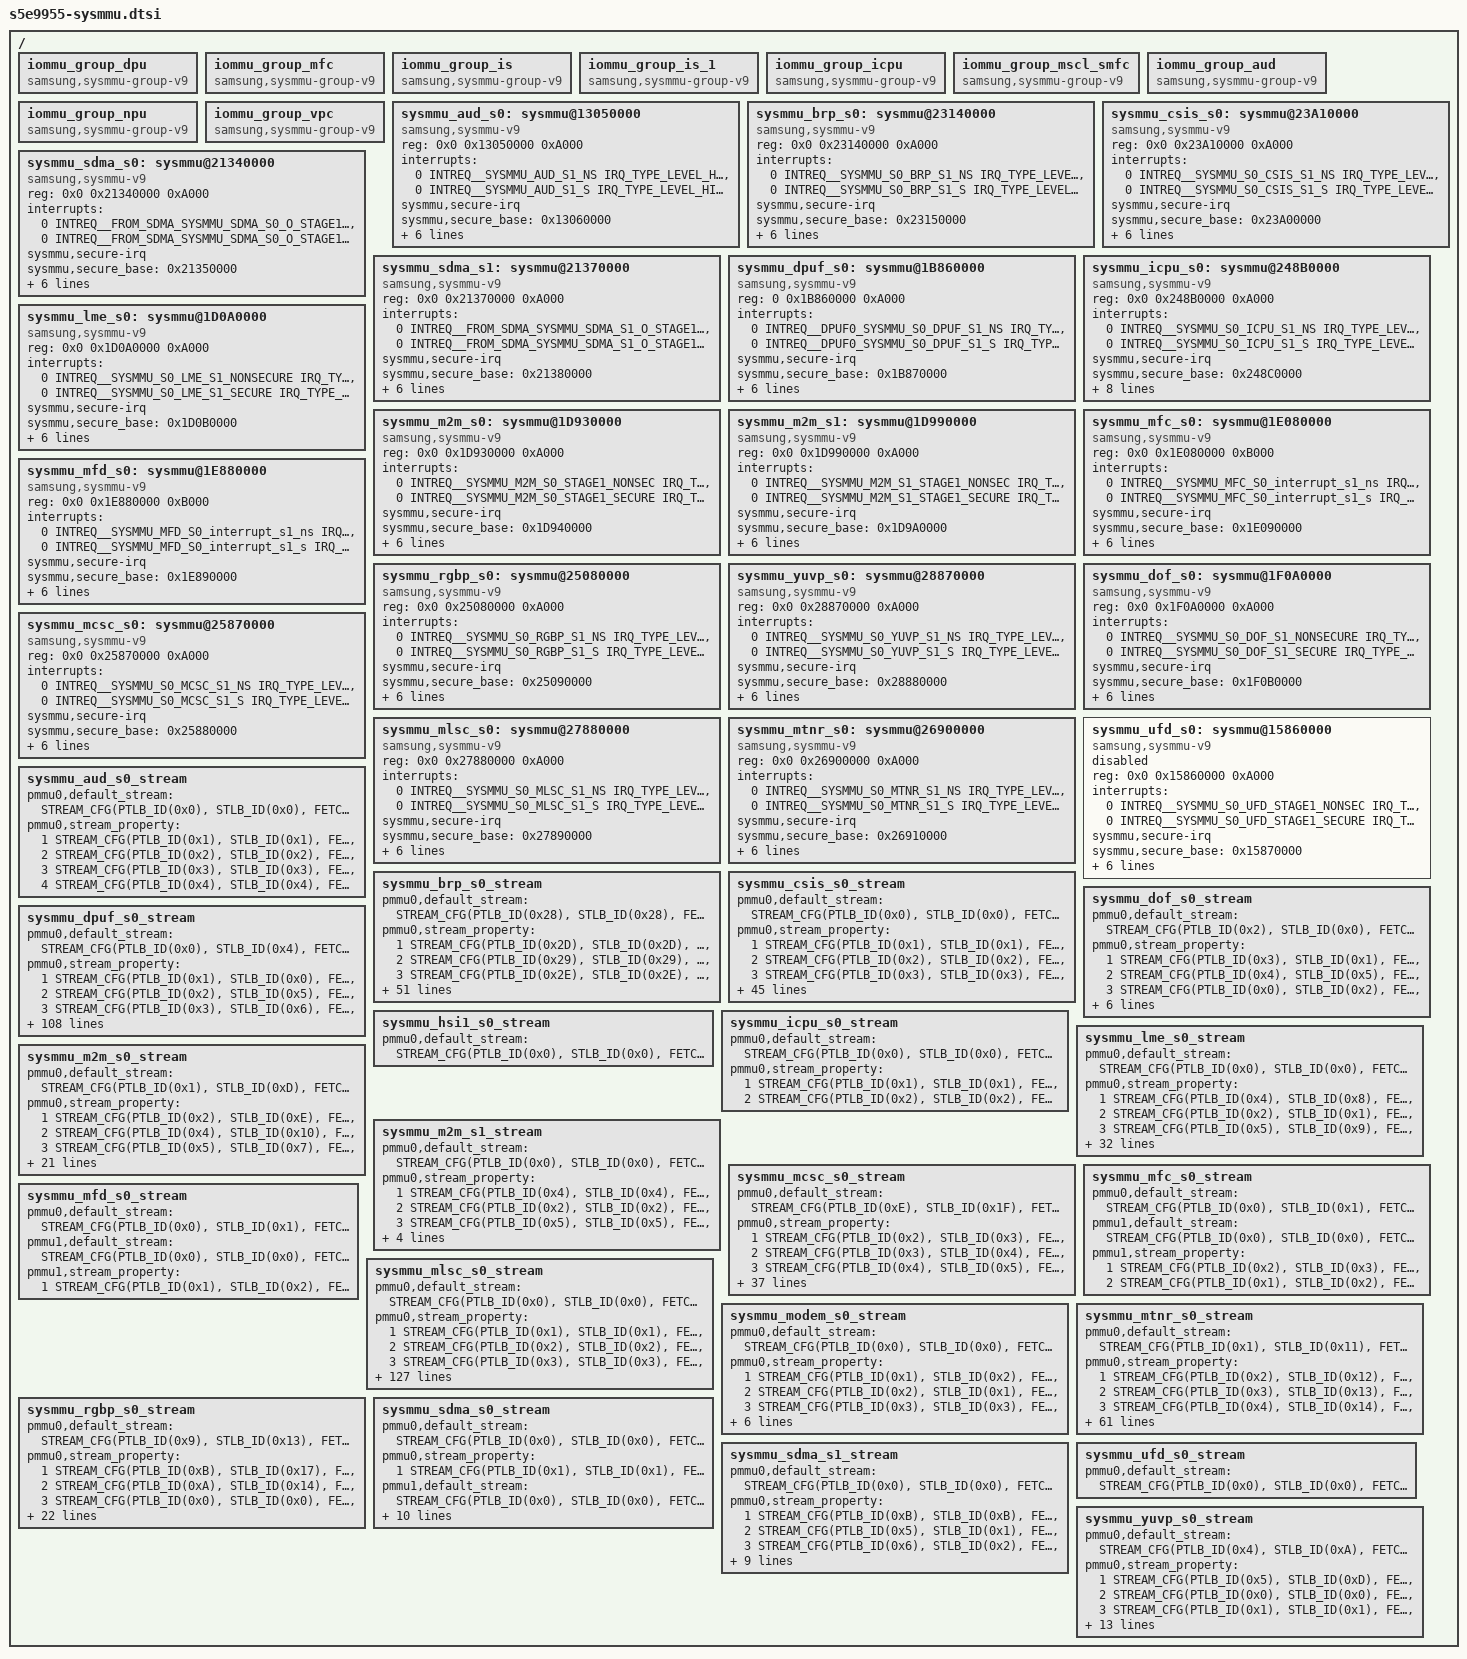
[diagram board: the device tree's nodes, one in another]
// SPDX-License-Identifier: GPL-2.0
/*
 * SAMSUNG S5E9955 SoC device tree source
 *
 * Copyright (c) 2023 Samsung Electronics Co., Ltd.
 *      http://www.samsung.com
 *
 * SAMSUNG S5E9955 SoC device nodes are listed in this file.
 * S5E9955 based board files can include this file and provide
 * values for board specific bindings.
 *
 * This program is free software; you can redistribute it and/or modify
 * it under the terms of the GNU General Public License version 2 as
 * published by the Free Software Foundation.
 */

#include <dt-bindings/interrupt-controller/arm-gic.h>
#include <dt-bindings/soc/samsung,sysmmu-v9.h>

/ {
	iommu_group_dpu: iommu_group_dpu {
		compatible = "samsung,sysmmu-group-v9";
	};

	iommu_group_mfc: iommu_group_mfc {
		compatible = "samsung,sysmmu-group-v9";
	};

	iommu_group_is: iommu_group_is {
		compatible = "samsung,sysmmu-group-v9";
	};

	iommu_group_is_1: iommu_group_is_1 {
		compatible = "samsung,sysmmu-group-v9";
	};

	iommu_group_icpu: iommu_group_icpu {
		compatible = "samsung,sysmmu-group-v9";
	};

	iommu_group_mscl_smfc: iommu_group_mscl_smfc {
		compatible = "samsung,sysmmu-group-v9";
	};

	iommu_group_aud: iommu_group_aud {
		compatible = "samsung,sysmmu-group-v9";
	};

	iommu_group_npu: iommu_group_npu {
		compatible = "samsung,sysmmu-group-v9";
	};

	iommu_group_vpc: iommu_group_vpc {
		compatible = "samsung,sysmmu-group-v9";
	};

	sysmmu_aud_s0: sysmmu@13050000 {
		compatible = "samsung,sysmmu-v9";
		reg = <0x0 0x13050000 0xA000>;
		interrupts = <0 INTREQ__SYSMMU_AUD_S1_NS IRQ_TYPE_LEVEL_HIGH>,
				<0 INTREQ__SYSMMU_AUD_S1_S IRQ_TYPE_LEVEL_HIGH>;
		sysmmu,secure-irq;
		sysmmu,secure_base = <0x13060000>;
		qos = <15>;
		#iommu-cells = <0>;
		stream-property = <&sysmmu_aud_s0_stream>;
		vmid_mask = <0x3>;
		sysmmu,feature-info = <0x1>;
		port-name = "ABOX (CA32_0) ABOX (CA32_1) ...";
		power-domains = <&pd_aud>;
	};

	sysmmu_brp_s0: sysmmu@23140000 {
		compatible = "samsung,sysmmu-v9";
		reg = <0x0 0x23140000 0xA000>;
		interrupts = <0 INTREQ__SYSMMU_S0_BRP_S1_NS IRQ_TYPE_LEVEL_HIGH>,
				<0 INTREQ__SYSMMU_S0_BRP_S1_S IRQ_TYPE_LEVEL_HIGH>;
		sysmmu,secure-irq;
		sysmmu,secure_base = <0x23150000>;
		qos = <15>;
		#iommu-cells = <0>;
		stream-property = <&sysmmu_brp_s0_stream>;
		vmid_mask = <0x3>;
		sysmmu,feature-info = <0x1>;
		port-name = "BYRP (M0) BYRP (M0) BYRP (M ...";
		power-domains = <&pd_byrp>;
		status = "okay";
	};

	sysmmu_csis_s0: sysmmu@23A10000 {
		compatible = "samsung,sysmmu-v9";
		reg = <0x0 0x23A10000 0xA000>;
		interrupts = <0 INTREQ__SYSMMU_S0_CSIS_S1_NS IRQ_TYPE_LEVEL_HIGH>,
				<0 INTREQ__SYSMMU_S0_CSIS_S1_S IRQ_TYPE_LEVEL_HIGH>;
		sysmmu,secure-irq;
		sysmmu,secure_base = <0x23A00000>;
		qos = <15>;
		#iommu-cells = <0>;
		stream-property = <&sysmmu_csis_s0_stream>;
		vmid_mask = <0x3>;
		sysmmu,feature-info = <0x1>;
		port-name = "CSISX7_V1.0 (CSIS DMA0) CSI ...";
		power-domains = <&pd_csis>;
		status = "okay";
	};

	sysmmu_sdma_s0: sysmmu@21340000 {
		compatible = "samsung,sysmmu-v9";
		reg = <0x0 0x21340000 0xA000>;
		interrupts = <0 INTREQ__FROM_SDMA_SYSMMU_SDMA_S0_O_STAGE1_NONSEC IRQ_TYPE_LEVEL_HIGH>,
				<0 INTREQ__FROM_SDMA_SYSMMU_SDMA_S0_O_STAGE1_SECURE IRQ_TYPE_LEVEL_HIGH>;
		sysmmu,secure-irq;
		sysmmu,secure_base = <0x21350000>;
		qos = <15>;
		#iommu-cells = <0>;
		stream-property = <&sysmmu_sdma_s0_stream>;
		vmid_mask = <0x3>;
		sysmmu,feature-info = <0x1>;
		port-name = "IP_SDMA (BUSD0) IP_SDMA (BU ...";
		power-domains = <&pd_sdma>;
	};

	sysmmu_sdma_s1: sysmmu@21370000 {
		compatible = "samsung,sysmmu-v9";
		reg = <0x0 0x21370000 0xA000>;
		interrupts = <0 INTREQ__FROM_SDMA_SYSMMU_SDMA_S1_O_STAGE1_NONSEC IRQ_TYPE_LEVEL_HIGH>,
				<0 INTREQ__FROM_SDMA_SYSMMU_SDMA_S1_O_STAGE1_SECURE IRQ_TYPE_LEVEL_HIGH>;
		sysmmu,secure-irq;
		sysmmu,secure_base = <0x21380000>;
		qos = <15>;
		#iommu-cells = <0>;
		stream-property = <&sysmmu_sdma_s1_stream>;
		vmid_mask = <0x3>;
		sysmmu,feature-info = <0x1>;
		port-name = "IP_DNC (DRAM)";
		power-domains = <&pd_sdma>;
	};

	sysmmu_dpuf_s0: sysmmu@1B860000 {
		compatible = "samsung,sysmmu-v9";
		reg = <0 0x1B860000 0xA000>;
		interrupts = <0 INTREQ__DPUF0_SYSMMU_S0_DPUF_S1_NS IRQ_TYPE_LEVEL_HIGH>,
				<0 INTREQ__DPUF0_SYSMMU_S0_DPUF_S1_S IRQ_TYPE_LEVEL_HIGH>;
		sysmmu,secure-irq;
		sysmmu,secure_base = <0x1B870000>;
		qos = <15>;
		#iommu-cells = <0>;
		stream-property = <&sysmmu_dpuf_s0_stream>;
		vmid_mask = <0x3>;
		sysmmu,feature-info = <0x1>;
		port-name = "DPU_DMA_TOP";
		power-domains = <&pd_dpuf1>;
	};

	sysmmu_icpu_s0: sysmmu@248B0000 {
		compatible = "samsung,sysmmu-v9";
		reg = <0x0 0x248B0000 0xA000>;
		interrupts = <0 INTREQ__SYSMMU_S0_ICPU_S1_NS IRQ_TYPE_LEVEL_HIGH>,
				<0 INTREQ__SYSMMU_S0_ICPU_S1_S  IRQ_TYPE_LEVEL_HIGH>;
		sysmmu,secure-irq;
		sysmmu,secure_base = <0x248C0000>;
		sysmmu,async-fault;
		qos = <15>;
		#iommu-cells = <0>;
		stream-property = <&sysmmu_icpu_s0_stream>;
		vmid_mask = <0x3>;
		sysmmu,feature-info = <0x1>;
		sysmmu,cacheable-override;
		port-name = "ICPU";
		power-domains = <&pd_icpu>;
		status = "okay";
	};

	sysmmu_lme_s0: sysmmu@1D0A0000 {
		compatible = "samsung,sysmmu-v9";
		reg = <0x0 0x1D0A0000 0xA000>;
		interrupts = <0 INTREQ__SYSMMU_S0_LME_S1_NONSECURE IRQ_TYPE_LEVEL_HIGH>,
				<0 INTREQ__SYSMMU_S0_LME_S1_SECURE IRQ_TYPE_LEVEL_HIGH>;
		sysmmu,secure-irq;
		sysmmu,secure_base = <0x1D0B0000>;
		qos = <15>;
		#iommu-cells = <0>;
		stream-property = <&sysmmu_lme_s0_stream>;
		vmid_mask = <0x3>;
		sysmmu,feature-info = <0x1>;
		port-name = "LME";
		power-domains = <&pd_lme>;
		status = "okay";
	};

	sysmmu_m2m_s0: sysmmu@1D930000 {
		compatible = "samsung,sysmmu-v9";
		reg = <0x0 0x1D930000 0xA000>;
		interrupts = <0 INTREQ__SYSMMU_M2M_S0_STAGE1_NONSEC IRQ_TYPE_LEVEL_HIGH>,
				<0 INTREQ__SYSMMU_M2M_S0_STAGE1_SECURE IRQ_TYPE_LEVEL_HIGH>;
		sysmmu,secure-irq;
		sysmmu,secure_base = <0x1D940000>;
		qos = <15>;
		#iommu-cells = <0>;
		stream-property = <&sysmmu_m2m_s0_stream>;
		vmid_mask = <0x3>;
		sysmmu,feature-info = <0x1>;
		port-name = "m2m_s0";
		power-domains = <&pd_m2m>;
	};

	sysmmu_m2m_s1: sysmmu@1D990000 {
		compatible = "samsung,sysmmu-v9";
		reg = <0x0 0x1D990000 0xA000>;
		interrupts = <0 INTREQ__SYSMMU_M2M_S1_STAGE1_NONSEC IRQ_TYPE_LEVEL_HIGH>,
				<0 INTREQ__SYSMMU_M2M_S1_STAGE1_SECURE IRQ_TYPE_LEVEL_HIGH>;
		sysmmu,secure-irq;
		sysmmu,secure_base = <0x1D9A0000>;
		qos = <15>;
		#iommu-cells = <0>;
		stream-property = <&sysmmu_m2m_s1_stream>;
		vmid_mask = <0x3>;
		sysmmu,feature-info = <0x1>;
		port-name = "m2m_s1";
		power-domains = <&pd_m2m>;
	};

	sysmmu_mfc_s0: sysmmu@1E080000 {
		compatible = "samsung,sysmmu-v9";
		reg = <0x0 0x1E080000 0xB000>;
		interrupts = <0 INTREQ__SYSMMU_MFC_S0_interrupt_s1_ns IRQ_TYPE_LEVEL_HIGH>,
				<0 INTREQ__SYSMMU_MFC_S0_interrupt_s1_s IRQ_TYPE_LEVEL_HIGH>;
		sysmmu,secure-irq;
		sysmmu,secure_base = <0x1E090000>;
		qos = <15>;
		#iommu-cells = <0>;
		stream-property = <&sysmmu_mfc_s0_stream>;
		vmid_mask = <0x7>;
		sysmmu,feature-info = <0x1>;
		port-name = "MFC0";
		power-domains = <&pd_mfc>;
	};

	sysmmu_mfd_s0: sysmmu@1E880000 {
		compatible = "samsung,sysmmu-v9";
		reg = <0x0 0x1E880000 0xB000>;
		interrupts = <0 INTREQ__SYSMMU_MFD_S0_interrupt_s1_ns IRQ_TYPE_LEVEL_HIGH>,
				<0 INTREQ__SYSMMU_MFD_S0_interrupt_s1_s IRQ_TYPE_LEVEL_HIGH>;
		sysmmu,secure-irq;
		sysmmu,secure_base = <0x1E890000>;
		qos = <15>;
		#iommu-cells = <0>;
		stream-property = <&sysmmu_mfd_s0_stream>;
		vmid_mask = <0x7>;
		sysmmu,feature-info = <0x1>;
		port-name = "MFC1";
		power-domains = <&pd_mfd>;
	};

	sysmmu_rgbp_s0: sysmmu@25080000 {
		compatible = "samsung,sysmmu-v9";
		reg = <0x0 0x25080000 0xA000>;
		interrupts = <0 INTREQ__SYSMMU_S0_RGBP_S1_NS IRQ_TYPE_LEVEL_HIGH>,
				<0 INTREQ__SYSMMU_S0_RGBP_S1_S IRQ_TYPE_LEVEL_HIGH>;
		sysmmu,secure-irq;
		sysmmu,secure_base = <0x25090000>;
		qos = <15>;
		#iommu-cells = <0>;
		stream-property = <&sysmmu_rgbp_s0_stream>;
		vmid_mask = <0x3>;
		sysmmu,feature-info = <0x1>;
		port-name = "RGBP (M0) RGBP (M0) RGBP (M ...";
		power-domains = <&pd_rgbp>;
		status = "okay";
	};

	sysmmu_yuvp_s0: sysmmu@28870000 {
		compatible = "samsung,sysmmu-v9";
		reg = <0x0 0x28870000 0xA000>;
		interrupts = <0 INTREQ__SYSMMU_S0_YUVP_S1_NS IRQ_TYPE_LEVEL_HIGH>,
				<0 INTREQ__SYSMMU_S0_YUVP_S1_S IRQ_TYPE_LEVEL_HIGH>;
		sysmmu,secure-irq;
		sysmmu,secure_base = <0x28880000>;
		qos = <15>;
		#iommu-cells = <0>;
		stream-property = <&sysmmu_yuvp_s0_stream>;
		vmid_mask = <0x3>;
		sysmmu,feature-info = <0x1>;
		port-name = "YUVP_M0_CL_VOTFR YUVP_M1_Y_ ...";
		power-domains = <&pd_yuvp>;
		status = "okay";
	};

	sysmmu_dof_s0: sysmmu@1F0A0000 {
		compatible = "samsung,sysmmu-v9";
		reg = <0x0 0x1F0A0000 0xA000>;
		interrupts = <0 INTREQ__SYSMMU_S0_DOF_S1_NONSECURE IRQ_TYPE_LEVEL_HIGH>,
				<0 INTREQ__SYSMMU_S0_DOF_S1_SECURE IRQ_TYPE_LEVEL_HIGH>;
		sysmmu,secure-irq;
		sysmmu,secure_base = <0x1F0B0000>;
		qos = <15>;
		#iommu-cells = <0>;
		stream-property = <&sysmmu_dof_s0_stream>;
		vmid_mask = <0x3>;
		sysmmu,feature-info = <0x1>;
		port-name = "DOF";
		power-domains = <&pd_dof>;
		status = "okay";
	};

	sysmmu_mcsc_s0: sysmmu@25870000 {
		compatible = "samsung,sysmmu-v9";
		reg = <0x0 0x25870000 0xA000>;
		interrupts = <0 INTREQ__SYSMMU_S0_MCSC_S1_NS IRQ_TYPE_LEVEL_HIGH>,
				<0 INTREQ__SYSMMU_S0_MCSC_S1_S IRQ_TYPE_LEVEL_HIGH>;
		sysmmu,secure-irq;
		sysmmu,secure_base = <0x25880000>;
		qos = <15>;
		#iommu-cells = <0>;
		stream-property = <&sysmmu_mcsc_s0_stream>;
		vmid_mask = <0x3>;
		sysmmu,feature-info = <0x1>;
		power-domains = <&pd_mcsc>;
		port-name = "MCSC";
		status = "okay";
	};

	sysmmu_mlsc_s0: sysmmu@27880000 {
		compatible = "samsung,sysmmu-v9";
		reg = <0x0 0x27880000 0xA000>;
		interrupts = <0 INTREQ__SYSMMU_S0_MLSC_S1_NS IRQ_TYPE_LEVEL_HIGH>,
				<0 INTREQ__SYSMMU_S0_MLSC_S1_S IRQ_TYPE_LEVEL_HIGH>;
		sysmmu,secure-irq;
		sysmmu,secure_base = <0x27890000>;
		qos = <15>;
		#iommu-cells = <0>;
		stream-property = <&sysmmu_mlsc_s0_stream>;
		vmid_mask = <0x3>;
		sysmmu,feature-info = <0x1>;
		power-domains = <&pd_mlsc>;
		port-name = "MLSC";
		status = "okay";
	};

	sysmmu_mtnr_s0: sysmmu@26900000 {
		compatible = "samsung,sysmmu-v9";
		reg = <0x0 0x26900000 0xA000>;
		interrupts = <0 INTREQ__SYSMMU_S0_MTNR_S1_NS IRQ_TYPE_LEVEL_HIGH>,
				<0 INTREQ__SYSMMU_S0_MTNR_S1_S IRQ_TYPE_LEVEL_HIGH>;
		sysmmu,secure-irq;
		sysmmu,secure_base = <0x26910000>;
		qos = <15>;
		#iommu-cells = <0>;
		stream-property = <&sysmmu_mtnr_s0_stream>;
		vmid_mask = <0x3>;
		sysmmu,feature-info = <0x1>;
		power-domains = <&pd_mtnr>;
		port-name = "MTNR";
		status = "okay";
	};

	sysmmu_ufd_s0: sysmmu@15860000 {
		compatible = "samsung,sysmmu-v9";
		reg = <0x0 0x15860000 0xA000>;
		interrupts = <0 INTREQ__SYSMMU_S0_UFD_STAGE1_NONSEC IRQ_TYPE_LEVEL_HIGH>,
				<0 INTREQ__SYSMMU_S0_UFD_STAGE1_SECURE IRQ_TYPE_LEVEL_HIGH>;
		sysmmu,secure-irq;
		sysmmu,secure_base = <0x15870000>;
		qos = <15>;
		#iommu-cells = <0>;
		stream-property = <&sysmmu_mlsc_s0_stream>;
		vmid_mask = <0x3>;
		sysmmu,feature-info = <0x1>;
		power-domains = <&pd_ufd>;
		port-name = "UFD";
		status = "disabled";
	};

	sysmmu_aud_s0_stream: sysmmu_aud_s0_stream {
		pmmu0,default_stream =
		<STREAM_CFG(PTLB_ID(0x0), STLB_ID(0x0), FETCH_SIZE(SIZE1), PTLB_DIS, STLB_DIS)>;
		pmmu0,stream_property =
		<1 STREAM_CFG(PTLB_ID(0x1), STLB_ID(0x1), FETCH_SIZE(SIZE1), PTLB_DIS, STLB_DIS)
		 STREAM_MATCH_CFG(DIR_RW)
		 STREAM_MATCH_SID_VALUE(0x1)
		 STREAM_MATCH_SID_MASK(0xF87)>,
		<2 STREAM_CFG(PTLB_ID(0x2), STLB_ID(0x2), FETCH_SIZE(SIZE1), PTLB_DIS, STLB_EN)
		 STREAM_MATCH_CFG(DIR_RW)
		 STREAM_MATCH_SID_VALUE(0x3)
		 STREAM_MATCH_SID_MASK(0xF87)>,
		<3 STREAM_CFG(PTLB_ID(0x3), STLB_ID(0x3), FETCH_SIZE(SIZE1), PTLB_DIS, STLB_DIS)
		 STREAM_MATCH_CFG(DIR_WRITE)
		 STREAM_MATCH_SID_VALUE(0x4)
		 STREAM_MATCH_SID_MASK(0xF87)>,
		<4 STREAM_CFG(PTLB_ID(0x4), STLB_ID(0x4), FETCH_SIZE(SIZE1), PTLB_DIS, STLB_DIS)
		 STREAM_MATCH_CFG(DIR_WRITE)
		 STREAM_MATCH_SID_VALUE(0x5)
		 STREAM_MATCH_SID_MASK(0xF87)>;
	};

	sysmmu_brp_s0_stream: sysmmu_brp_s0_stream {
		pmmu0,default_stream =
		<STREAM_CFG(PTLB_ID(0x28), STLB_ID(0x28), FETCH_SIZE(SIZE1), PTLB_DIS, STLB_DIS)>;
		pmmu0,stream_property =
		<1 STREAM_CFG(PTLB_ID(0x2D), STLB_ID(0x2D), FETCH_SIZE(SIZE1), PTLB_DIS, STLB_DIS)
		 STREAM_MATCH_CFG(DIR_WRITE)
		 STREAM_MATCH_SID_VALUE(0x0)
		 STREAM_MATCH_SID_MASK(0xF81)>,
		<2 STREAM_CFG(PTLB_ID(0x29), STLB_ID(0x29), FETCH_SIZE(SIZE1), PTLB_DIS, STLB_DIS)
		 STREAM_MATCH_CFG(DIR_READ)
		 STREAM_MATCH_SID_VALUE(0x80)
		 STREAM_MATCH_SID_MASK(0xF81)>,
		<3 STREAM_CFG(PTLB_ID(0x2E), STLB_ID(0x2E), FETCH_SIZE(SIZE1), PTLB_DIS, STLB_DIS)
		 STREAM_MATCH_CFG(DIR_WRITE)
		 STREAM_MATCH_SID_VALUE(0x80)
		 STREAM_MATCH_SID_MASK(0xF81)>,
		<4 STREAM_CFG(PTLB_ID(0x2A), STLB_ID(0x2A), FETCH_SIZE(SIZE1), PTLB_DIS, STLB_DIS)
		 STREAM_MATCH_CFG(DIR_READ)
		 STREAM_MATCH_SID_VALUE(0x100)
		 STREAM_MATCH_SID_MASK(0xF81)>,
		<5 STREAM_CFG(PTLB_ID(0x2F), STLB_ID(0x2F), FETCH_SIZE(SIZE1), PTLB_DIS, STLB_DIS)
		 STREAM_MATCH_CFG(DIR_WRITE)
		 STREAM_MATCH_SID_VALUE(0x100)
		 STREAM_MATCH_SID_MASK(0xF81)>,
		<6 STREAM_CFG(PTLB_ID(0x2B), STLB_ID(0x2B), FETCH_SIZE(SIZE1), PTLB_DIS, STLB_DIS)
		 STREAM_MATCH_CFG(DIR_READ)
		 STREAM_MATCH_SID_VALUE(0x180)
		 STREAM_MATCH_SID_MASK(0xF81)>,
		<7 STREAM_CFG(PTLB_ID(0x30), STLB_ID(0x30), FETCH_SIZE(SIZE1), PTLB_DIS, STLB_DIS)
		 STREAM_MATCH_CFG(DIR_WRITE)
		 STREAM_MATCH_SID_VALUE(0x180)
		 STREAM_MATCH_SID_MASK(0xF81)>,
		<8 STREAM_CFG(PTLB_ID(0x2C), STLB_ID(0x2C), FETCH_SIZE(SIZE1), PTLB_DIS, STLB_DIS)
		 STREAM_MATCH_CFG(DIR_READ)
		 STREAM_MATCH_SID_VALUE(0x200)
		 STREAM_MATCH_SID_MASK(0xF81)>,
		<9 STREAM_CFG(PTLB_ID(0x31), STLB_ID(0x31), FETCH_SIZE(SIZE1), PTLB_DIS, STLB_DIS)
		 STREAM_MATCH_CFG(DIR_WRITE)
		 STREAM_MATCH_SID_VALUE(0x200)
		 STREAM_MATCH_SID_MASK(0xF81)>,
		<10 STREAM_CFG(PTLB_ID(0x0), STLB_ID(0x0), FETCH_SIZE(SIZE1), PTLB_EN, STLB_EN)
		 STREAM_MATCH_CFG(DIR_READ)
		 STREAM_MATCH_SID_VALUE(0x280)
		 STREAM_MATCH_SID_MASK(0xF81)>,
		<11 STREAM_CFG(PTLB_ID(0x1), STLB_ID(0x1), FETCH_SIZE(SIZE1), PTLB_EN, STLB_EN)
		 STREAM_MATCH_CFG(DIR_READ)
		 STREAM_MATCH_SID_VALUE(0x281)
		 STREAM_MATCH_SID_MASK(0xF81)>,
		<12 STREAM_CFG(PTLB_ID(0x32), STLB_ID(0x32), FETCH_SIZE(SIZE1), PTLB_DIS, STLB_DIS)
		 STREAM_MATCH_CFG(DIR_WRITE)
		 STREAM_MATCH_SID_VALUE(0x280)
		 STREAM_MATCH_SID_MASK(0xF81)>,
		<13 STREAM_CFG(PTLB_ID(0x2), STLB_ID(0x2), FETCH_SIZE(SIZE1), PTLB_EN, STLB_EN)
		 STREAM_MATCH_CFG(DIR_READ)
		 STREAM_MATCH_SID_VALUE(0x300)
		 STREAM_MATCH_SID_MASK(0xF81)>,
		<14 STREAM_CFG(PTLB_ID(0x3), STLB_ID(0x3), FETCH_SIZE(SIZE1), PTLB_EN, STLB_EN)
		 STREAM_MATCH_CFG(DIR_READ)
		 STREAM_MATCH_SID_VALUE(0x301)
		 STREAM_MATCH_SID_MASK(0xF81)>,
		<15 STREAM_CFG(PTLB_ID(0x33), STLB_ID(0x33), FETCH_SIZE(SIZE1), PTLB_DIS, STLB_DIS)
		 STREAM_MATCH_CFG(DIR_WRITE)
		 STREAM_MATCH_SID_VALUE(0x300)
		 STREAM_MATCH_SID_MASK(0xF81)>,
		<16 STREAM_CFG(PTLB_ID(0x4), STLB_ID(0x4), FETCH_SIZE(SIZE1), PTLB_EN, STLB_EN)
		 STREAM_MATCH_CFG(DIR_READ)
		 STREAM_MATCH_SID_VALUE(0x380)
		 STREAM_MATCH_SID_MASK(0xF81)>,
		<17 STREAM_CFG(PTLB_ID(0x5), STLB_ID(0x5), FETCH_SIZE(SIZE1), PTLB_EN, STLB_EN)
		 STREAM_MATCH_CFG(DIR_READ)
		 STREAM_MATCH_SID_VALUE(0x381)
		 STREAM_MATCH_SID_MASK(0xF81)>,
		<18 STREAM_CFG(PTLB_ID(0x34), STLB_ID(0x34), FETCH_SIZE(SIZE1), PTLB_DIS, STLB_DIS)
		 STREAM_MATCH_CFG(DIR_WRITE)
		 STREAM_MATCH_SID_VALUE(0x380)
		 STREAM_MATCH_SID_MASK(0xF81)>,
		<19 STREAM_CFG(PTLB_ID(0x6), STLB_ID(0x6), FETCH_SIZE(SIZE1), PTLB_EN, STLB_EN)
		 STREAM_MATCH_CFG(DIR_READ)
		 STREAM_MATCH_SID_VALUE(0x400)
		 STREAM_MATCH_SID_MASK(0xF81)>,
		<20 STREAM_CFG(PTLB_ID(0x7), STLB_ID(0x7), FETCH_SIZE(SIZE1), PTLB_EN, STLB_EN)
		 STREAM_MATCH_CFG(DIR_READ)
		 STREAM_MATCH_SID_VALUE(0x401)
		 STREAM_MATCH_SID_MASK(0xF81)>,
		<21 STREAM_CFG(PTLB_ID(0x35), STLB_ID(0x35), FETCH_SIZE(SIZE1), PTLB_DIS, STLB_DIS)
		 STREAM_MATCH_CFG(DIR_WRITE)
		 STREAM_MATCH_SID_VALUE(0x400)
		 STREAM_MATCH_SID_MASK(0xF81)>,
		<22 STREAM_CFG(PTLB_ID(0x8), STLB_ID(0x8), FETCH_SIZE(SIZE1), PTLB_EN, STLB_EN)
		 STREAM_MATCH_CFG(DIR_READ)
		 STREAM_MATCH_SID_VALUE(0x480)
		 STREAM_MATCH_SID_MASK(0xF81)>,
		<23 STREAM_CFG(PTLB_ID(0x9), STLB_ID(0x9), FETCH_SIZE(SIZE1), PTLB_EN, STLB_EN)
		 STREAM_MATCH_CFG(DIR_READ)
		 STREAM_MATCH_SID_VALUE(0x481)
		 STREAM_MATCH_SID_MASK(0xF81)>,
		<24 STREAM_CFG(PTLB_ID(0x36), STLB_ID(0x36), FETCH_SIZE(SIZE1), PTLB_DIS, STLB_DIS)
		 STREAM_MATCH_CFG(DIR_WRITE)
		 STREAM_MATCH_SID_VALUE(0x480)
		 STREAM_MATCH_SID_MASK(0xF81)>,
		<25 STREAM_CFG(PTLB_ID(0xA), STLB_ID(0xA), FETCH_SIZE(SIZE1), PTLB_DIS, STLB_EN)
		 STREAM_MATCH_CFG(DIR_WRITE)
		 STREAM_MATCH_SID_VALUE(0x500)
		 STREAM_MATCH_SID_MASK(0xFFF)>,
		<26 STREAM_CFG(PTLB_ID(0xB), STLB_ID(0xB), FETCH_SIZE(SIZE1), PTLB_DIS, STLB_EN)
		 STREAM_MATCH_CFG(DIR_WRITE)
		 STREAM_MATCH_SID_VALUE(0x508)
		 STREAM_MATCH_SID_MASK(0xFFF)>,
		<27 STREAM_CFG(PTLB_ID(0xC), STLB_ID(0xC), FETCH_SIZE(SIZE1), PTLB_DIS, STLB_EN)
		 STREAM_MATCH_CFG(DIR_WRITE)
		 STREAM_MATCH_SID_VALUE(0x510)
		 STREAM_MATCH_SID_MASK(0xFFF)>,
		<28 STREAM_CFG(PTLB_ID(0xD), STLB_ID(0xD), FETCH_SIZE(SIZE1), PTLB_DIS, STLB_EN)
		 STREAM_MATCH_CFG(DIR_WRITE)
		 STREAM_MATCH_SID_VALUE(0x518)
		 STREAM_MATCH_SID_MASK(0xFFF)>,
		<29 STREAM_CFG(PTLB_ID(0xE), STLB_ID(0xE), FETCH_SIZE(SIZE1), PTLB_DIS, STLB_EN)
		 STREAM_MATCH_CFG(DIR_WRITE)
		 STREAM_MATCH_SID_VALUE(0x520)
		 STREAM_MATCH_SID_MASK(0xFFF)>,
		<30 STREAM_CFG(PTLB_ID(0xF), STLB_ID(0xF), FETCH_SIZE(SIZE1), PTLB_DIS, STLB_EN)
		 STREAM_MATCH_CFG(DIR_WRITE)
		 STREAM_MATCH_SID_VALUE(0x580)
		 STREAM_MATCH_SID_MASK(0xFFF)>,
		<31 STREAM_CFG(PTLB_ID(0x10), STLB_ID(0x10), FETCH_SIZE(SIZE1), PTLB_DIS, STLB_EN)
		 STREAM_MATCH_CFG(DIR_WRITE)
		 STREAM_MATCH_SID_VALUE(0x588)
		 STREAM_MATCH_SID_MASK(0xFFF)>,
		<32 STREAM_CFG(PTLB_ID(0x11), STLB_ID(0x11), FETCH_SIZE(SIZE1), PTLB_DIS, STLB_EN)
		 STREAM_MATCH_CFG(DIR_WRITE)
		 STREAM_MATCH_SID_VALUE(0x590)
		 STREAM_MATCH_SID_MASK(0xFFF)>,
		<33 STREAM_CFG(PTLB_ID(0x12), STLB_ID(0x12), FETCH_SIZE(SIZE1), PTLB_DIS, STLB_EN)
		 STREAM_MATCH_CFG(DIR_WRITE)
		 STREAM_MATCH_SID_VALUE(0x598)
		 STREAM_MATCH_SID_MASK(0xFFF)>,
		<34 STREAM_CFG(PTLB_ID(0x13), STLB_ID(0x13), FETCH_SIZE(SIZE1), PTLB_DIS, STLB_EN)
		 STREAM_MATCH_CFG(DIR_WRITE)
		 STREAM_MATCH_SID_VALUE(0x5A0)
		 STREAM_MATCH_SID_MASK(0xFFF)>,
		<35 STREAM_CFG(PTLB_ID(0x14), STLB_ID(0x14), FETCH_SIZE(SIZE1), PTLB_DIS, STLB_EN)
		 STREAM_MATCH_CFG(DIR_WRITE)
		 STREAM_MATCH_SID_VALUE(0x600)
		 STREAM_MATCH_SID_MASK(0xFFF)>,
		<36 STREAM_CFG(PTLB_ID(0x15), STLB_ID(0x15), FETCH_SIZE(SIZE1), PTLB_DIS, STLB_EN)
		 STREAM_MATCH_CFG(DIR_WRITE)
		 STREAM_MATCH_SID_VALUE(0x608)
		 STREAM_MATCH_SID_MASK(0xFFF)>,
		<37 STREAM_CFG(PTLB_ID(0x16), STLB_ID(0x16), FETCH_SIZE(SIZE1), PTLB_DIS, STLB_EN)
		 STREAM_MATCH_CFG(DIR_WRITE)
		 STREAM_MATCH_SID_VALUE(0x610)
		 STREAM_MATCH_SID_MASK(0xFFF)>,
		<38 STREAM_CFG(PTLB_ID(0x17), STLB_ID(0x17), FETCH_SIZE(SIZE1), PTLB_DIS, STLB_EN)
		 STREAM_MATCH_CFG(DIR_WRITE)
		 STREAM_MATCH_SID_VALUE(0x618)
		 STREAM_MATCH_SID_MASK(0xFFF)>,
		<39 STREAM_CFG(PTLB_ID(0x18), STLB_ID(0x18), FETCH_SIZE(SIZE1), PTLB_DIS, STLB_EN)
		 STREAM_MATCH_CFG(DIR_WRITE)
		 STREAM_MATCH_SID_VALUE(0x620)
		 STREAM_MATCH_SID_MASK(0xFFF)>,
		<40 STREAM_CFG(PTLB_ID(0x19), STLB_ID(0x19), FETCH_SIZE(SIZE1), PTLB_DIS, STLB_EN)
		 STREAM_MATCH_CFG(DIR_WRITE)
		 STREAM_MATCH_SID_VALUE(0x680)
		 STREAM_MATCH_SID_MASK(0xFFF)>,
		<41 STREAM_CFG(PTLB_ID(0x1A), STLB_ID(0x1A), FETCH_SIZE(SIZE1), PTLB_DIS, STLB_EN)
		 STREAM_MATCH_CFG(DIR_WRITE)
		 STREAM_MATCH_SID_VALUE(0x688)
		 STREAM_MATCH_SID_MASK(0xFFF)>,
		<42 STREAM_CFG(PTLB_ID(0x1B), STLB_ID(0x1B), FETCH_SIZE(SIZE1), PTLB_DIS, STLB_EN)
		 STREAM_MATCH_CFG(DIR_WRITE)
		 STREAM_MATCH_SID_VALUE(0x690)
		 STREAM_MATCH_SID_MASK(0xFFF)>,
		<43 STREAM_CFG(PTLB_ID(0x1C), STLB_ID(0x1C), FETCH_SIZE(SIZE1), PTLB_DIS, STLB_EN)
		 STREAM_MATCH_CFG(DIR_WRITE)
		 STREAM_MATCH_SID_VALUE(0x698)
		 STREAM_MATCH_SID_MASK(0xFFF)>,
		<44 STREAM_CFG(PTLB_ID(0x1D), STLB_ID(0x1D), FETCH_SIZE(SIZE1), PTLB_DIS, STLB_EN)
		 STREAM_MATCH_CFG(DIR_WRITE)
		 STREAM_MATCH_SID_VALUE(0x6A0)
		 STREAM_MATCH_SID_MASK(0xFFF)>,
		<45 STREAM_CFG(PTLB_ID(0x1E), STLB_ID(0x1E), FETCH_SIZE(SIZE1), PTLB_DIS, STLB_EN)
		 STREAM_MATCH_CFG(DIR_WRITE)
		 STREAM_MATCH_SID_VALUE(0x700)
		 STREAM_MATCH_SID_MASK(0xFFF)>,
		<46 STREAM_CFG(PTLB_ID(0x1F), STLB_ID(0x1F), FETCH_SIZE(SIZE1), PTLB_DIS, STLB_EN)
		 STREAM_MATCH_CFG(DIR_WRITE)
		 STREAM_MATCH_SID_VALUE(0x708)
		 STREAM_MATCH_SID_MASK(0xFFF)>,
		<47 STREAM_CFG(PTLB_ID(0x20), STLB_ID(0x20), FETCH_SIZE(SIZE1), PTLB_DIS, STLB_EN)
		 STREAM_MATCH_CFG(DIR_WRITE)
		 STREAM_MATCH_SID_VALUE(0x710)
		 STREAM_MATCH_SID_MASK(0xFFF)>,
		<48 STREAM_CFG(PTLB_ID(0x21), STLB_ID(0x21), FETCH_SIZE(SIZE1), PTLB_DIS, STLB_EN)
		 STREAM_MATCH_CFG(DIR_WRITE)
		 STREAM_MATCH_SID_VALUE(0x718)
		 STREAM_MATCH_SID_MASK(0xFFF)>,
		<49 STREAM_CFG(PTLB_ID(0x22), STLB_ID(0x22), FETCH_SIZE(SIZE1), PTLB_DIS, STLB_EN)
		 STREAM_MATCH_CFG(DIR_WRITE)
		 STREAM_MATCH_SID_VALUE(0x720)
		 STREAM_MATCH_SID_MASK(0xFFF)>,
		<50 STREAM_CFG(PTLB_ID(0x23), STLB_ID(0x23), FETCH_SIZE(SIZE1), PTLB_DIS, STLB_EN)
		 STREAM_MATCH_CFG(DIR_WRITE)
		 STREAM_MATCH_SID_VALUE(0x780)
		 STREAM_MATCH_SID_MASK(0xFFF)>,
		<51 STREAM_CFG(PTLB_ID(0x24), STLB_ID(0x24), FETCH_SIZE(SIZE1), PTLB_DIS, STLB_EN)
		 STREAM_MATCH_CFG(DIR_WRITE)
		 STREAM_MATCH_SID_VALUE(0x788)
		 STREAM_MATCH_SID_MASK(0xFFF)>,
		<52 STREAM_CFG(PTLB_ID(0x25), STLB_ID(0x25), FETCH_SIZE(SIZE1), PTLB_DIS, STLB_EN)
		 STREAM_MATCH_CFG(DIR_WRITE)
		 STREAM_MATCH_SID_VALUE(0x790)
		 STREAM_MATCH_SID_MASK(0xFFF)>,
		<53 STREAM_CFG(PTLB_ID(0x26), STLB_ID(0x26), FETCH_SIZE(SIZE1), PTLB_DIS, STLB_EN)
		 STREAM_MATCH_CFG(DIR_WRITE)
		 STREAM_MATCH_SID_VALUE(0x798)
		 STREAM_MATCH_SID_MASK(0xFFF)>,
		<54 STREAM_CFG(PTLB_ID(0x27), STLB_ID(0x27), FETCH_SIZE(SIZE1), PTLB_DIS, STLB_EN)
		 STREAM_MATCH_CFG(DIR_WRITE)
		 STREAM_MATCH_SID_VALUE(0x7A0)
		 STREAM_MATCH_SID_MASK(0xFFF)>;
	};

	sysmmu_csis_s0_stream: sysmmu_csis_s0_stream {
		pmmu0,default_stream =
		<STREAM_CFG(PTLB_ID(0x0), STLB_ID(0x0), FETCH_SIZE(SIZE1), PTLB_DIS, STLB_EN)>;
		pmmu0,stream_property =
		<1 STREAM_CFG(PTLB_ID(0x1), STLB_ID(0x1), FETCH_SIZE(SIZE1), PTLB_DIS, STLB_EN)
		 STREAM_MATCH_CFG(DIR_WRITE)
		 STREAM_MATCH_SID_VALUE(0x1)
		 STREAM_MATCH_SID_MASK(0xF87)>,
		<2 STREAM_CFG(PTLB_ID(0x2), STLB_ID(0x2), FETCH_SIZE(SIZE1), PTLB_DIS, STLB_EN)
		 STREAM_MATCH_CFG(DIR_WRITE)
		 STREAM_MATCH_SID_VALUE(0x2)
		 STREAM_MATCH_SID_MASK(0xF87)>,
		<3 STREAM_CFG(PTLB_ID(0x3), STLB_ID(0x3), FETCH_SIZE(SIZE1), PTLB_DIS, STLB_EN)
		 STREAM_MATCH_CFG(DIR_WRITE)
		 STREAM_MATCH_SID_VALUE(0x4)
		 STREAM_MATCH_SID_MASK(0xF87)>,
		<4 STREAM_CFG(PTLB_ID(0x4), STLB_ID(0x4), FETCH_SIZE(SIZE1), PTLB_DIS, STLB_EN)
		 STREAM_MATCH_CFG(DIR_WRITE)
		 STREAM_MATCH_SID_VALUE(0x6)
		 STREAM_MATCH_SID_MASK(0xF87)>,
		<5 STREAM_CFG(PTLB_ID(0x5), STLB_ID(0x5), FETCH_SIZE(SIZE1), PTLB_DIS, STLB_EN)
		 STREAM_MATCH_CFG(DIR_WRITE)
		 STREAM_MATCH_SID_VALUE(0x80)
		 STREAM_MATCH_SID_MASK(0xF87)>,
		<6 STREAM_CFG(PTLB_ID(0x6), STLB_ID(0x6), FETCH_SIZE(SIZE1), PTLB_DIS, STLB_EN)
		 STREAM_MATCH_CFG(DIR_WRITE)
		 STREAM_MATCH_SID_VALUE(0x81)
		 STREAM_MATCH_SID_MASK(0xF87)>,
		<7 STREAM_CFG(PTLB_ID(0x7), STLB_ID(0x7), FETCH_SIZE(SIZE1), PTLB_DIS, STLB_EN)
		 STREAM_MATCH_CFG(DIR_WRITE)
		 STREAM_MATCH_SID_VALUE(0x82)
		 STREAM_MATCH_SID_MASK(0xF87)>,
		<8 STREAM_CFG(PTLB_ID(0x8), STLB_ID(0x8), FETCH_SIZE(SIZE1), PTLB_DIS, STLB_EN)
		 STREAM_MATCH_CFG(DIR_WRITE)
		 STREAM_MATCH_SID_VALUE(0x84)
		 STREAM_MATCH_SID_MASK(0xF87)>,
		<9 STREAM_CFG(PTLB_ID(0x9), STLB_ID(0x9), FETCH_SIZE(SIZE1), PTLB_DIS, STLB_EN)
		 STREAM_MATCH_CFG(DIR_WRITE)
		 STREAM_MATCH_SID_VALUE(0x86)
		 STREAM_MATCH_SID_MASK(0xF87)>;
		pmmu1,default_stream =
		<STREAM_CFG(PTLB_ID(0x0), STLB_ID(0xA), FETCH_SIZE(SIZE1), PTLB_DIS, STLB_EN)>;
		pmmu1,stream_property =
		<1 STREAM_CFG(PTLB_ID(0x1), STLB_ID(0xB), FETCH_SIZE(SIZE1), PTLB_DIS, STLB_EN)
		 STREAM_MATCH_CFG(DIR_WRITE)
		 STREAM_MATCH_SID_VALUE(0x1)
		 STREAM_MATCH_SID_MASK(0xF87)>,
		<2 STREAM_CFG(PTLB_ID(0x2), STLB_ID(0xC), FETCH_SIZE(SIZE1), PTLB_DIS, STLB_EN)
		 STREAM_MATCH_CFG(DIR_WRITE)
		 STREAM_MATCH_SID_VALUE(0x2)
		 STREAM_MATCH_SID_MASK(0xF87)>,
		<3 STREAM_CFG(PTLB_ID(0x3), STLB_ID(0xD), FETCH_SIZE(SIZE1), PTLB_DIS, STLB_EN)
		 STREAM_MATCH_CFG(DIR_WRITE)
		 STREAM_MATCH_SID_VALUE(0x4)
		 STREAM_MATCH_SID_MASK(0xF87)>,
		<4 STREAM_CFG(PTLB_ID(0x4), STLB_ID(0xE), FETCH_SIZE(SIZE1), PTLB_DIS, STLB_EN)
		 STREAM_MATCH_CFG(DIR_WRITE)
		 STREAM_MATCH_SID_VALUE(0x6)
		 STREAM_MATCH_SID_MASK(0xF87)>,
		<5 STREAM_CFG(PTLB_ID(0x5), STLB_ID(0xF), FETCH_SIZE(SIZE1), PTLB_DIS, STLB_EN)
		 STREAM_MATCH_CFG(DIR_WRITE)
		 STREAM_MATCH_SID_VALUE(0x80)
		 STREAM_MATCH_SID_MASK(0xF87)>,
		<6 STREAM_CFG(PTLB_ID(0x6), STLB_ID(0x10), FETCH_SIZE(SIZE1), PTLB_DIS, STLB_EN)
		 STREAM_MATCH_CFG(DIR_WRITE)
		 STREAM_MATCH_SID_VALUE(0x81)
		 STREAM_MATCH_SID_MASK(0xF87)>,
		<7 STREAM_CFG(PTLB_ID(0x7), STLB_ID(0x11), FETCH_SIZE(SIZE1), PTLB_DIS, STLB_EN)
		 STREAM_MATCH_CFG(DIR_WRITE)
		 STREAM_MATCH_SID_VALUE(0x82)
		 STREAM_MATCH_SID_MASK(0xF87)>,
		<8 STREAM_CFG(PTLB_ID(0x8), STLB_ID(0x12), FETCH_SIZE(SIZE1), PTLB_DIS, STLB_EN)
		 STREAM_MATCH_CFG(DIR_WRITE)
		 STREAM_MATCH_SID_VALUE(0x84)
		 STREAM_MATCH_SID_MASK(0xF87)>,
		<9 STREAM_CFG(PTLB_ID(0x9), STLB_ID(0x13), FETCH_SIZE(SIZE1), PTLB_DIS, STLB_EN)
		 STREAM_MATCH_CFG(DIR_WRITE)
		 STREAM_MATCH_SID_VALUE(0x86)
		 STREAM_MATCH_SID_MASK(0xF87)>,
		<10 STREAM_CFG(PTLB_ID(0xA), STLB_ID(0x14), FETCH_SIZE(SIZE1), PTLB_DIS, STLB_EN)
		 STREAM_MATCH_CFG(DIR_WRITE)
		 STREAM_MATCH_SID_VALUE(0x100)
		 STREAM_MATCH_SID_MASK(0xF87)>,
		<11 STREAM_CFG(PTLB_ID(0xB), STLB_ID(0x15), FETCH_SIZE(SIZE1), PTLB_DIS, STLB_EN)
		 STREAM_MATCH_CFG(DIR_WRITE)
		 STREAM_MATCH_SID_VALUE(0x101)
		 STREAM_MATCH_SID_MASK(0xF87)>,
		<12 STREAM_CFG(PTLB_ID(0xC), STLB_ID(0x16), FETCH_SIZE(SIZE1), PTLB_DIS, STLB_EN)
		 STREAM_MATCH_CFG(DIR_WRITE)
		 STREAM_MATCH_SID_VALUE(0x102)
		 STREAM_MATCH_SID_MASK(0xF87)>,
		<13 STREAM_CFG(PTLB_ID(0xD), STLB_ID(0x17), FETCH_SIZE(SIZE1), PTLB_DIS, STLB_EN)
		 STREAM_MATCH_CFG(DIR_WRITE)
		 STREAM_MATCH_SID_VALUE(0x104)
		 STREAM_MATCH_SID_MASK(0xF87)>,
		<14 STREAM_CFG(PTLB_ID(0xE), STLB_ID(0x18), FETCH_SIZE(SIZE1), PTLB_DIS, STLB_EN)
		 STREAM_MATCH_CFG(DIR_WRITE)
		 STREAM_MATCH_SID_VALUE(0x106)
		 STREAM_MATCH_SID_MASK(0xF87)>;
		pmmu2,default_stream =
		<STREAM_CFG(PTLB_ID(0x0), STLB_ID(0x19), FETCH_SIZE(SIZE1), PTLB_EN, STLB_EN)>;
		pmmu2,stream_property =
		<1 STREAM_CFG(PTLB_ID(0x1), STLB_ID(0x1A), FETCH_SIZE(SIZE1), PTLB_DIS, STLB_EN)
		 STREAM_MATCH_CFG(DIR_WRITE)
		 STREAM_MATCH_SID_VALUE(0x0)
		 STREAM_MATCH_SID_MASK(0xFFF)>,
		<2 STREAM_CFG(PTLB_ID(0x2), STLB_ID(0x1B), FETCH_SIZE(SIZE1), PTLB_DIS, STLB_EN)
		 STREAM_MATCH_CFG(DIR_WRITE)
		 STREAM_MATCH_SID_VALUE(0x8)
		 STREAM_MATCH_SID_MASK(0xFFF)>,
		<3 STREAM_CFG(PTLB_ID(0x3), STLB_ID(0x1C), FETCH_SIZE(SIZE1), PTLB_DIS, STLB_EN)
		 STREAM_MATCH_CFG(DIR_WRITE)
		 STREAM_MATCH_SID_VALUE(0x10)
		 STREAM_MATCH_SID_MASK(0xFFF)>,
		<4 STREAM_CFG(PTLB_ID(0x4), STLB_ID(0x1D), FETCH_SIZE(SIZE1), PTLB_DIS, STLB_EN)
		 STREAM_MATCH_CFG(DIR_WRITE)
		 STREAM_MATCH_SID_VALUE(0x18)
		 STREAM_MATCH_SID_MASK(0xFFF)>,
		<5 STREAM_CFG(PTLB_ID(0x5), STLB_ID(0x1E), FETCH_SIZE(SIZE1), PTLB_DIS, STLB_EN)
		 STREAM_MATCH_CFG(DIR_WRITE)
		 STREAM_MATCH_SID_VALUE(0x80)
		 STREAM_MATCH_SID_MASK(0xFFF)>,
		<6 STREAM_CFG(PTLB_ID(0x6), STLB_ID(0x1F), FETCH_SIZE(SIZE1), PTLB_DIS, STLB_EN)
		 STREAM_MATCH_CFG(DIR_WRITE)
		 STREAM_MATCH_SID_VALUE(0x88)
		 STREAM_MATCH_SID_MASK(0xFFF)>,
		<7 STREAM_CFG(PTLB_ID(0x7), STLB_ID(0x20), FETCH_SIZE(SIZE1), PTLB_DIS, STLB_EN)
		 STREAM_MATCH_CFG(DIR_WRITE)
		 STREAM_MATCH_SID_VALUE(0x90)
		 STREAM_MATCH_SID_MASK(0xFFF)>,
		<8 STREAM_CFG(PTLB_ID(0x8), STLB_ID(0x21), FETCH_SIZE(SIZE1), PTLB_DIS, STLB_EN)
		 STREAM_MATCH_CFG(DIR_WRITE)
		 STREAM_MATCH_SID_VALUE(0x98)
		 STREAM_MATCH_SID_MASK(0xFFF)>,
		<9 STREAM_CFG(PTLB_ID(0x9), STLB_ID(0x22), FETCH_SIZE(SIZE1), PTLB_DIS, STLB_EN)
		 STREAM_MATCH_CFG(DIR_WRITE)
		 STREAM_MATCH_SID_VALUE(0x100)
		 STREAM_MATCH_SID_MASK(0xFFF)>,
		<10 STREAM_CFG(PTLB_ID(0xA), STLB_ID(0x23), FETCH_SIZE(SIZE1), PTLB_DIS, STLB_EN)
		 STREAM_MATCH_CFG(DIR_WRITE)
		 STREAM_MATCH_SID_VALUE(0x108)
		 STREAM_MATCH_SID_MASK(0xFFF)>,
		<11 STREAM_CFG(PTLB_ID(0xB), STLB_ID(0x24), FETCH_SIZE(SIZE1), PTLB_DIS, STLB_EN)
		 STREAM_MATCH_CFG(DIR_WRITE)
		 STREAM_MATCH_SID_VALUE(0x110)
		 STREAM_MATCH_SID_MASK(0xFFF)>,
		<12 STREAM_CFG(PTLB_ID(0xC), STLB_ID(0x25), FETCH_SIZE(SIZE1), PTLB_DIS, STLB_EN)
		 STREAM_MATCH_CFG(DIR_WRITE)
		 STREAM_MATCH_SID_VALUE(0x118)
		 STREAM_MATCH_SID_MASK(0xFFF)>,
		<13 STREAM_CFG(PTLB_ID(0x11), STLB_ID(0x2A), FETCH_SIZE(SIZE1), PTLB_DIS, STLB_DIS)
		 STREAM_MATCH_CFG(DIR_WRITE)
		 STREAM_MATCH_SID_VALUE(0x180)
		 STREAM_MATCH_SID_MASK(0xF81)>,
		<14 STREAM_CFG(PTLB_ID(0x12), STLB_ID(0x2B), FETCH_SIZE(SIZE1), PTLB_DIS, STLB_DIS)
		 STREAM_MATCH_CFG(DIR_WRITE)
		 STREAM_MATCH_SID_VALUE(0x200)
		 STREAM_MATCH_SID_MASK(0xF81)>,
		<15 STREAM_CFG(PTLB_ID(0x13), STLB_ID(0x2C), FETCH_SIZE(SIZE1), PTLB_DIS, STLB_DIS)
		 STREAM_MATCH_CFG(DIR_WRITE)
		 STREAM_MATCH_SID_VALUE(0x280)
		 STREAM_MATCH_SID_MASK(0xF81)>,
		<16 STREAM_CFG(PTLB_ID(0xD), STLB_ID(0x26), FETCH_SIZE(SIZE1), PTLB_DIS, STLB_DIS)
		 STREAM_MATCH_CFG(DIR_READ)
		 STREAM_MATCH_SID_VALUE(0x300)
		 STREAM_MATCH_SID_MASK(0xF81)>,
		<17 STREAM_CFG(PTLB_ID(0xE), STLB_ID(0x27), FETCH_SIZE(SIZE1), PTLB_DIS, STLB_DIS)
		 STREAM_MATCH_CFG(DIR_READ)
		 STREAM_MATCH_SID_VALUE(0x380)
		 STREAM_MATCH_SID_MASK(0xF81)>,
		<18 STREAM_CFG(PTLB_ID(0xF), STLB_ID(0x28), FETCH_SIZE(SIZE1), PTLB_DIS, STLB_DIS)
		 STREAM_MATCH_CFG(DIR_READ)
		 STREAM_MATCH_SID_VALUE(0x400)
		 STREAM_MATCH_SID_MASK(0xF81)>,
		<19 STREAM_CFG(PTLB_ID(0x10), STLB_ID(0x29), FETCH_SIZE(SIZE1), PTLB_DIS, STLB_DIS)
		 STREAM_MATCH_CFG(DIR_READ)
		 STREAM_MATCH_SID_VALUE(0x480)
		 STREAM_MATCH_SID_MASK(0xF81)>;
	};

	sysmmu_dof_s0_stream: sysmmu_dof_s0_stream {
		pmmu0,default_stream =
		<STREAM_CFG(PTLB_ID(0x2), STLB_ID(0x0), FETCH_SIZE(SIZE8), PTLB_EN, STLB_DIS)>;
		pmmu0,stream_property =
		<1 STREAM_CFG(PTLB_ID(0x3), STLB_ID(0x1), FETCH_SIZE(SIZE8), PTLB_EN, STLB_DIS)
		 STREAM_MATCH_CFG(DIR_READ)
		 STREAM_MATCH_SID_VALUE(0x1)
		 STREAM_MATCH_SID_MASK(0xF87)>,
		<2 STREAM_CFG(PTLB_ID(0x4), STLB_ID(0x5), FETCH_SIZE(SIZE1), PTLB_DIS, STLB_DIS)
		 STREAM_MATCH_CFG(DIR_RW)
		 STREAM_MATCH_SID_VALUE(0x2)
		 STREAM_MATCH_SID_MASK(0xF87)>,
		<3 STREAM_CFG(PTLB_ID(0x0), STLB_ID(0x2), FETCH_SIZE(SIZE4), PTLB_DIS, STLB_DIS)
		 STREAM_MATCH_CFG(DIR_RW)
		 STREAM_MATCH_SID_VALUE(0x3)
		 STREAM_MATCH_SID_MASK(0xF87)>,
		<4 STREAM_CFG(PTLB_ID(0x5), STLB_ID(0x6), FETCH_SIZE(SIZE1), PTLB_DIS, STLB_EN)
		 STREAM_MATCH_CFG(DIR_READ)
		 STREAM_MATCH_SID_VALUE(0x4)
		 STREAM_MATCH_SID_MASK(0xF87)>,
		<5 STREAM_CFG(PTLB_ID(0x6), STLB_ID(0x7), FETCH_SIZE(SIZE1), PTLB_DIS, STLB_EN)
		 STREAM_MATCH_CFG(DIR_READ)
		 STREAM_MATCH_SID_VALUE(0x5)
		 STREAM_MATCH_SID_MASK(0xF87)>,
		<6 STREAM_CFG(PTLB_ID(0x7), STLB_ID(0x3), FETCH_SIZE(SIZE8), PTLB_EN, STLB_DIS)
		 STREAM_MATCH_CFG(DIR_READ)
		 STREAM_MATCH_SID_VALUE(0x6)
		 STREAM_MATCH_SID_MASK(0xF87)>,
		<7 STREAM_CFG(PTLB_ID(0x1), STLB_ID(0x4), FETCH_SIZE(SIZE4), PTLB_DIS, STLB_DIS)
		 STREAM_MATCH_CFG(DIR_RW)
		 STREAM_MATCH_SID_VALUE(0x7)
		 STREAM_MATCH_SID_MASK(0xF87)>,
		<8 STREAM_CFG(PTLB_ID(0x8), STLB_ID(0x8), FETCH_SIZE(SIZE1), PTLB_DIS, STLB_DIS)
		 STREAM_MATCH_CFG(DIR_READ)
		 STREAM_MATCH_SID_VALUE(0x80)
		 STREAM_MATCH_SID_MASK(0xF81)>,
		<9 STREAM_CFG(PTLB_ID(0x9), STLB_ID(0x9), FETCH_SIZE(SIZE1), PTLB_DIS, STLB_DIS)
		 STREAM_MATCH_CFG(DIR_WRITE)
		 STREAM_MATCH_SID_VALUE(0x80)
		 STREAM_MATCH_SID_MASK(0xF81)>;
	};

	sysmmu_dpuf_s0_stream: sysmmu_dpuf_s0_stream {
		pmmu0,default_stream =
		<STREAM_CFG(PTLB_ID(0x0), STLB_ID(0x4), FETCH_SIZE(SIZE16), PTLB_EN, STLB_EN)>;
		pmmu0,stream_property =
		<1 STREAM_CFG(PTLB_ID(0x1), STLB_ID(0x0), FETCH_SIZE(SIZE32), PTLB_EN, STLB_EN)
		 STREAM_MATCH_CFG(DIR_READ)
		 STREAM_MATCH_SID_VALUE(0x4)
		 STREAM_MATCH_SID_MASK(0x1F)>,
		<2 STREAM_CFG(PTLB_ID(0x2), STLB_ID(0x5), FETCH_SIZE(SIZE16), PTLB_DIS, STLB_EN)
		 STREAM_MATCH_CFG(DIR_READ)
		 STREAM_MATCH_SID_VALUE(0x8)
		 STREAM_MATCH_SID_MASK(0x1F)>,
		<3 STREAM_CFG(PTLB_ID(0x3), STLB_ID(0x6), FETCH_SIZE(SIZE16), PTLB_DIS, STLB_EN)
		 STREAM_MATCH_CFG(DIR_READ)
		 STREAM_MATCH_SID_VALUE(0x10)
		 STREAM_MATCH_SID_MASK(0x1F)>,
		<4 STREAM_CFG(PTLB_ID(0x4), STLB_ID(0x7), FETCH_SIZE(SIZE16), PTLB_EN, STLB_EN)
		 STREAM_MATCH_CFG(DIR_READ)
		 STREAM_MATCH_SID_VALUE(0x18)
		 STREAM_MATCH_SID_MASK(0x1F)>,
		<5 STREAM_CFG(PTLB_ID(0x5), STLB_ID(0xC), FETCH_SIZE(SIZE2), PTLB_EN, STLB_EN)
		 STREAM_MATCH_CFG(DIR_READ)
		 STREAM_MATCH_SID_VALUE(0xC)
		 STREAM_MATCH_SID_MASK(0x1F)>,
		<6 STREAM_CFG(PTLB_ID(0x6), STLB_ID(0xD), FETCH_SIZE(SIZE2), PTLB_EN, STLB_EN)
		 STREAM_MATCH_CFG(DIR_READ)
		 STREAM_MATCH_SID_VALUE(0x14)
		 STREAM_MATCH_SID_MASK(0x1F)>,
		<7 STREAM_CFG(PTLB_ID(0x7), STLB_ID(0xE), FETCH_SIZE(SIZE2), PTLB_EN, STLB_EN)
		 STREAM_MATCH_CFG(DIR_READ)
		 STREAM_MATCH_SID_VALUE(0x1C)
		 STREAM_MATCH_SID_MASK(0x1F)>,
		<8 STREAM_CFG(PTLB_ID(0x8), STLB_ID(0x1), FETCH_SIZE(SIZE32), PTLB_EN, STLB_EN)
		 STREAM_MATCH_CFG(DIR_READ)
		 STREAM_MATCH_SID_VALUE(0x5)
		 STREAM_MATCH_SID_MASK(0x1F)>,
		<9 STREAM_CFG(PTLB_ID(0x9), STLB_ID(0xF), FETCH_SIZE(SIZE2), PTLB_EN, STLB_EN)
		 STREAM_MATCH_CFG(DIR_READ)
		 STREAM_MATCH_SID_VALUE(0xD)
		 STREAM_MATCH_SID_MASK(0x1F)>,
		<10 STREAM_CFG(PTLB_ID(0xA), STLB_ID(0x10), FETCH_SIZE(SIZE2), PTLB_EN, STLB_EN)
		 STREAM_MATCH_CFG(DIR_READ)
		 STREAM_MATCH_SID_VALUE(0x15)
		 STREAM_MATCH_SID_MASK(0x1F)>,
		<11 STREAM_CFG(PTLB_ID(0xB), STLB_ID(0x11), FETCH_SIZE(SIZE2), PTLB_EN, STLB_EN)
		 STREAM_MATCH_CFG(DIR_READ)
		 STREAM_MATCH_SID_VALUE(0x1D)
		 STREAM_MATCH_SID_MASK(0x1F)>,
		<12 STREAM_CFG(PTLB_ID(0xC), STLB_ID(0x12), FETCH_SIZE(SIZE2), PTLB_EN, STLB_EN)
		 STREAM_MATCH_CFG(DIR_READ)
		 STREAM_MATCH_SID_VALUE(0x2)
		 STREAM_MATCH_SID_MASK(0x1F)>,
		<13 STREAM_CFG(PTLB_ID(0xD), STLB_ID(0x13), FETCH_SIZE(SIZE2), PTLB_EN, STLB_EN)
		 STREAM_MATCH_CFG(DIR_READ)
		 STREAM_MATCH_SID_VALUE(0xA)
		 STREAM_MATCH_SID_MASK(0x1F)>,
		<14 STREAM_CFG(PTLB_ID(0xE), STLB_ID(0x14), FETCH_SIZE(SIZE2), PTLB_EN, STLB_EN)
		 STREAM_MATCH_CFG(DIR_READ)
		 STREAM_MATCH_SID_VALUE(0x12)
		 STREAM_MATCH_SID_MASK(0x1F)>,
		<15 STREAM_CFG(PTLB_ID(0xF), STLB_ID(0x15), FETCH_SIZE(SIZE2), PTLB_EN, STLB_EN)
		 STREAM_MATCH_CFG(DIR_READ)
		 STREAM_MATCH_SID_VALUE(0x1A)
		 STREAM_MATCH_SID_MASK(0x1F)>,
		<16 STREAM_CFG(PTLB_ID(0x10), STLB_ID(0x16), FETCH_SIZE(SIZE2), PTLB_EN, STLB_EN)
		 STREAM_MATCH_CFG(DIR_READ)
		 STREAM_MATCH_SID_VALUE(0x6)
		 STREAM_MATCH_SID_MASK(0x1F)>,
		<17 STREAM_CFG(PTLB_ID(0x11), STLB_ID(0x17), FETCH_SIZE(SIZE2), PTLB_EN, STLB_EN)
		 STREAM_MATCH_CFG(DIR_READ)
		 STREAM_MATCH_SID_VALUE(0xE)
		 STREAM_MATCH_SID_MASK(0x1F)>,
		<18 STREAM_CFG(PTLB_ID(0x12), STLB_ID(0x18), FETCH_SIZE(SIZE2), PTLB_EN, STLB_EN)
		 STREAM_MATCH_CFG(DIR_READ)
		 STREAM_MATCH_SID_VALUE(0x16)
		 STREAM_MATCH_SID_MASK(0x1F)>,
		<19 STREAM_CFG(PTLB_ID(0x13), STLB_ID(0x19), FETCH_SIZE(SIZE2), PTLB_EN, STLB_EN)
		 STREAM_MATCH_CFG(DIR_READ)
		 STREAM_MATCH_SID_VALUE(0x7)
		 STREAM_MATCH_SID_MASK(0x1F)>,
		<20 STREAM_CFG(PTLB_ID(0x14), STLB_ID(0x1A), FETCH_SIZE(SIZE2), PTLB_EN, STLB_EN)
		 STREAM_MATCH_CFG(DIR_READ)
		 STREAM_MATCH_SID_VALUE(0xF)
		 STREAM_MATCH_SID_MASK(0x1F)>,
		<21 STREAM_CFG(PTLB_ID(0x15), STLB_ID(0x1B), FETCH_SIZE(SIZE2), PTLB_EN, STLB_EN)
		 STREAM_MATCH_CFG(DIR_READ)
		 STREAM_MATCH_SID_VALUE(0x17)
		 STREAM_MATCH_SID_MASK(0x1F)>,
		<22 STREAM_CFG(PTLB_ID(0x16), STLB_ID(0x2C), FETCH_SIZE(SIZE1), PTLB_EN, STLB_EN)
		 STREAM_MATCH_CFG(DIR_READ)
		 STREAM_MATCH_SID_VALUE(0xB)
		 STREAM_MATCH_SID_MASK(0x1F)>,
		<23 STREAM_CFG(PTLB_ID(0x17), STLB_ID(0x2D), FETCH_SIZE(SIZE1), PTLB_EN, STLB_EN)
		 STREAM_MATCH_CFG(DIR_READ)
		 STREAM_MATCH_SID_VALUE(0x1B)
		 STREAM_MATCH_SID_MASK(0x1F)>,
		<24 STREAM_CFG(PTLB_ID(0x18), STLB_ID(0x2E), FETCH_SIZE(SIZE1), PTLB_DIS, STLB_EN)
		 STREAM_MATCH_CFG(DIR_WRITE)
		 STREAM_MATCH_SID_VALUE(0x0)
		 STREAM_MATCH_SID_MASK(0x1F)>,
		<25 STREAM_CFG(PTLB_ID(0x19), STLB_ID(0x2F), FETCH_SIZE(SIZE1), PTLB_DIS, STLB_EN)
		 STREAM_MATCH_CFG(DIR_WRITE)
		 STREAM_MATCH_SID_VALUE(0x1)
		 STREAM_MATCH_SID_MASK(0x1F)>;
		pmmu1,default_stream =
		<STREAM_CFG(PTLB_ID(0x0), STLB_ID(0x4), FETCH_SIZE(SIZE16), PTLB_EN, STLB_EN)>;
		pmmu1,stream_property =
		<1 STREAM_CFG(PTLB_ID(0x1), STLB_ID(0x0), FETCH_SIZE(SIZE32), PTLB_EN, STLB_EN)
		 STREAM_MATCH_CFG(DIR_READ)
		 STREAM_MATCH_SID_VALUE(0x4)
		 STREAM_MATCH_SID_MASK(0x1F)>,
		<2 STREAM_CFG(PTLB_ID(0x2), STLB_ID(0x5), FETCH_SIZE(SIZE16), PTLB_EN, STLB_EN)
		 STREAM_MATCH_CFG(DIR_READ)
		 STREAM_MATCH_SID_VALUE(0x8)
		 STREAM_MATCH_SID_MASK(0x1F)>,
		<3 STREAM_CFG(PTLB_ID(0x3), STLB_ID(0x6), FETCH_SIZE(SIZE16), PTLB_EN, STLB_EN)
		 STREAM_MATCH_CFG(DIR_READ)
		 STREAM_MATCH_SID_VALUE(0x10)
		 STREAM_MATCH_SID_MASK(0x1F)>,
		<4 STREAM_CFG(PTLB_ID(0x4), STLB_ID(0x7), FETCH_SIZE(SIZE16), PTLB_EN, STLB_EN)
		 STREAM_MATCH_CFG(DIR_READ)
		 STREAM_MATCH_SID_VALUE(0x18)
		 STREAM_MATCH_SID_MASK(0x1F)>,
		<5 STREAM_CFG(PTLB_ID(0x5), STLB_ID(0xC), FETCH_SIZE(SIZE2), PTLB_EN, STLB_EN)
		 STREAM_MATCH_CFG(DIR_READ)
		 STREAM_MATCH_SID_VALUE(0xC)
		 STREAM_MATCH_SID_MASK(0x1F)>,
		<6 STREAM_CFG(PTLB_ID(0x6), STLB_ID(0xD), FETCH_SIZE(SIZE2), PTLB_EN, STLB_EN)
		 STREAM_MATCH_CFG(DIR_READ)
		 STREAM_MATCH_SID_VALUE(0x14)
		 STREAM_MATCH_SID_MASK(0x1F)>,
		<7 STREAM_CFG(PTLB_ID(0x7), STLB_ID(0xE), FETCH_SIZE(SIZE2), PTLB_EN, STLB_EN)
		 STREAM_MATCH_CFG(DIR_READ)
		 STREAM_MATCH_SID_VALUE(0x1C)
		 STREAM_MATCH_SID_MASK(0x1F)>,
		<8 STREAM_CFG(PTLB_ID(0x8), STLB_ID(0x1), FETCH_SIZE(SIZE32), PTLB_EN, STLB_EN)
		 STREAM_MATCH_CFG(DIR_READ)
		 STREAM_MATCH_SID_VALUE(0x5)
		 STREAM_MATCH_SID_MASK(0x1F)>,
		<9 STREAM_CFG(PTLB_ID(0x9), STLB_ID(0xF), FETCH_SIZE(SIZE2), PTLB_EN, STLB_EN)
		 STREAM_MATCH_CFG(DIR_READ)
		 STREAM_MATCH_SID_VALUE(0xD)
		 STREAM_MATCH_SID_MASK(0x1F)>,
		<10 STREAM_CFG(PTLB_ID(0xA), STLB_ID(0x10), FETCH_SIZE(SIZE2), PTLB_EN, STLB_EN)
		 STREAM_MATCH_CFG(DIR_READ)
		 STREAM_MATCH_SID_VALUE(0x15)
		 STREAM_MATCH_SID_MASK(0x1F)>,
		<11 STREAM_CFG(PTLB_ID(0xB), STLB_ID(0x11), FETCH_SIZE(SIZE2), PTLB_EN, STLB_EN)
		 STREAM_MATCH_CFG(DIR_READ)
		 STREAM_MATCH_SID_VALUE(0x1D)
		 STREAM_MATCH_SID_MASK(0x1F)>,
		<12 STREAM_CFG(PTLB_ID(0xC), STLB_ID(0x12), FETCH_SIZE(SIZE2), PTLB_EN, STLB_EN)
		 STREAM_MATCH_CFG(DIR_READ)
		 STREAM_MATCH_SID_VALUE(0x2)
		 STREAM_MATCH_SID_MASK(0x1F)>,
		<13 STREAM_CFG(PTLB_ID(0xD), STLB_ID(0x13), FETCH_SIZE(SIZE2), PTLB_EN, STLB_EN)
		 STREAM_MATCH_CFG(DIR_READ)
		 STREAM_MATCH_SID_VALUE(0xA)
		 STREAM_MATCH_SID_MASK(0x1F)>,
		<14 STREAM_CFG(PTLB_ID(0xE), STLB_ID(0x14), FETCH_SIZE(SIZE2), PTLB_EN, STLB_EN)
		 STREAM_MATCH_CFG(DIR_READ)
		 STREAM_MATCH_SID_VALUE(0x12)
		 STREAM_MATCH_SID_MASK(0x1F)>,
		<15 STREAM_CFG(PTLB_ID(0xF), STLB_ID(0x15), FETCH_SIZE(SIZE2), PTLB_EN, STLB_EN)
		 STREAM_MATCH_CFG(DIR_READ)
		 STREAM_MATCH_SID_VALUE(0x1A)
		 STREAM_MATCH_SID_MASK(0x1F)>,
		<16 STREAM_CFG(PTLB_ID(0x10), STLB_ID(0x16), FETCH_SIZE(SIZE2), PTLB_EN, STLB_EN)
		 STREAM_MATCH_CFG(DIR_READ)
		 STREAM_MATCH_SID_VALUE(0x6)
		 STREAM_MATCH_SID_MASK(0x1F)>,
		<17 STREAM_CFG(PTLB_ID(0x11), STLB_ID(0x17), FETCH_SIZE(SIZE2), PTLB_EN, STLB_EN)
		 STREAM_MATCH_CFG(DIR_READ)
		 STREAM_MATCH_SID_VALUE(0xE)
		 STREAM_MATCH_SID_MASK(0x1F)>,
		<18 STREAM_CFG(PTLB_ID(0x12), STLB_ID(0x18), FETCH_SIZE(SIZE2), PTLB_EN, STLB_EN)
		 STREAM_MATCH_CFG(DIR_READ)
		 STREAM_MATCH_SID_VALUE(0x16)
		 STREAM_MATCH_SID_MASK(0x1F)>,
		<19 STREAM_CFG(PTLB_ID(0x13), STLB_ID(0x19), FETCH_SIZE(SIZE2), PTLB_EN, STLB_EN)
		 STREAM_MATCH_CFG(DIR_READ)
		 STREAM_MATCH_SID_VALUE(0x7)
		 STREAM_MATCH_SID_MASK(0x1F)>,
		<20 STREAM_CFG(PTLB_ID(0x14), STLB_ID(0x1A), FETCH_SIZE(SIZE2), PTLB_EN, STLB_EN)
		 STREAM_MATCH_CFG(DIR_READ)
		 STREAM_MATCH_SID_VALUE(0xF)
		 STREAM_MATCH_SID_MASK(0x1F)>,
		<21 STREAM_CFG(PTLB_ID(0x15), STLB_ID(0x1B), FETCH_SIZE(SIZE2), PTLB_EN, STLB_EN)
		 STREAM_MATCH_CFG(DIR_READ)
		 STREAM_MATCH_SID_VALUE(0x17)
		 STREAM_MATCH_SID_MASK(0x1F)>,
		<22 STREAM_CFG(PTLB_ID(0x16), STLB_ID(0x38), FETCH_SIZE(SIZE1), PTLB_DIS, STLB_DIS)
		 STREAM_MATCH_CFG(DIR_WRITE)
		 STREAM_MATCH_SID_VALUE(0x10)
		 STREAM_MATCH_SID_MASK(0x1F)>;
		pmmu2,default_stream =
		<STREAM_CFG(PTLB_ID(0x0), STLB_ID(0x8), FETCH_SIZE(SIZE16), PTLB_EN, STLB_EN)>;
		pmmu2,stream_property =
		<1 STREAM_CFG(PTLB_ID(0x1), STLB_ID(0x2), FETCH_SIZE(SIZE32), PTLB_EN, STLB_EN)
		 STREAM_MATCH_CFG(DIR_READ)
		 STREAM_MATCH_SID_VALUE(0x4)
		 STREAM_MATCH_SID_MASK(0x1F)>,
		<2 STREAM_CFG(PTLB_ID(0x2), STLB_ID(0x9), FETCH_SIZE(SIZE16), PTLB_DIS, STLB_EN)
		 STREAM_MATCH_CFG(DIR_READ)
		 STREAM_MATCH_SID_VALUE(0x8)
		 STREAM_MATCH_SID_MASK(0x1F)>,
		<3 STREAM_CFG(PTLB_ID(0x3), STLB_ID(0xA), FETCH_SIZE(SIZE16), PTLB_DIS, STLB_EN)
		 STREAM_MATCH_CFG(DIR_READ)
		 STREAM_MATCH_SID_VALUE(0x10)
		 STREAM_MATCH_SID_MASK(0x1F)>,
		<4 STREAM_CFG(PTLB_ID(0x4), STLB_ID(0xB), FETCH_SIZE(SIZE16), PTLB_EN, STLB_EN)
		 STREAM_MATCH_CFG(DIR_READ)
		 STREAM_MATCH_SID_VALUE(0x18)
		 STREAM_MATCH_SID_MASK(0x1F)>,
		<5 STREAM_CFG(PTLB_ID(0x5), STLB_ID(0x1C), FETCH_SIZE(SIZE2), PTLB_EN, STLB_EN)
		 STREAM_MATCH_CFG(DIR_READ)
		 STREAM_MATCH_SID_VALUE(0xC)
		 STREAM_MATCH_SID_MASK(0x1F)>,
		<6 STREAM_CFG(PTLB_ID(0x6), STLB_ID(0x1D), FETCH_SIZE(SIZE2), PTLB_EN, STLB_EN)
		 STREAM_MATCH_CFG(DIR_READ)
		 STREAM_MATCH_SID_VALUE(0x14)
		 STREAM_MATCH_SID_MASK(0x1F)>,
		<7 STREAM_CFG(PTLB_ID(0x7), STLB_ID(0x1E), FETCH_SIZE(SIZE2), PTLB_EN, STLB_EN)
		 STREAM_MATCH_CFG(DIR_READ)
		 STREAM_MATCH_SID_VALUE(0x1C)
		 STREAM_MATCH_SID_MASK(0x1F)>,
		<8 STREAM_CFG(PTLB_ID(0x8), STLB_ID(0x3), FETCH_SIZE(SIZE32), PTLB_EN, STLB_EN)
		 STREAM_MATCH_CFG(DIR_READ)
		 STREAM_MATCH_SID_VALUE(0x5)
		 STREAM_MATCH_SID_MASK(0x1F)>,
		<9 STREAM_CFG(PTLB_ID(0x9), STLB_ID(0x1F), FETCH_SIZE(SIZE2), PTLB_EN, STLB_EN)
		 STREAM_MATCH_CFG(DIR_READ)
		 STREAM_MATCH_SID_VALUE(0xD)
		 STREAM_MATCH_SID_MASK(0x1F)>,
		<10 STREAM_CFG(PTLB_ID(0xA), STLB_ID(0x20), FETCH_SIZE(SIZE2), PTLB_EN, STLB_EN)
		 STREAM_MATCH_CFG(DIR_READ)
		 STREAM_MATCH_SID_VALUE(0x15)
		 STREAM_MATCH_SID_MASK(0x1F)>,
		<11 STREAM_CFG(PTLB_ID(0xB), STLB_ID(0x21), FETCH_SIZE(SIZE2), PTLB_EN, STLB_EN)
		 STREAM_MATCH_CFG(DIR_READ)
		 STREAM_MATCH_SID_VALUE(0x1D)
		 STREAM_MATCH_SID_MASK(0x1F)>,
		<12 STREAM_CFG(PTLB_ID(0xC), STLB_ID(0x22), FETCH_SIZE(SIZE2), PTLB_EN, STLB_EN)
		 STREAM_MATCH_CFG(DIR_READ)
		 STREAM_MATCH_SID_VALUE(0x2)
		 STREAM_MATCH_SID_MASK(0x1F)>,
		<13 STREAM_CFG(PTLB_ID(0xD), STLB_ID(0x23), FETCH_SIZE(SIZE2), PTLB_EN, STLB_EN)
		 STREAM_MATCH_CFG(DIR_READ)
		 STREAM_MATCH_SID_VALUE(0xA)
		 STREAM_MATCH_SID_MASK(0x1F)>,
		<14 STREAM_CFG(PTLB_ID(0xE), STLB_ID(0x24), FETCH_SIZE(SIZE2), PTLB_EN, STLB_EN)
		 STREAM_MATCH_CFG(DIR_READ)
		 STREAM_MATCH_SID_VALUE(0x12)
		 STREAM_MATCH_SID_MASK(0x1F)>,
		<15 STREAM_CFG(PTLB_ID(0xF), STLB_ID(0x25), FETCH_SIZE(SIZE2), PTLB_EN, STLB_EN)
		 STREAM_MATCH_CFG(DIR_READ)
		 STREAM_MATCH_SID_VALUE(0x1A)
		 STREAM_MATCH_SID_MASK(0x1F)>,
		<16 STREAM_CFG(PTLB_ID(0x10), STLB_ID(0x26), FETCH_SIZE(SIZE2), PTLB_EN, STLB_EN)
		 STREAM_MATCH_CFG(DIR_READ)
		 STREAM_MATCH_SID_VALUE(0x6)
		 STREAM_MATCH_SID_MASK(0x1F)>,
		<17 STREAM_CFG(PTLB_ID(0x11), STLB_ID(0x27), FETCH_SIZE(SIZE2), PTLB_EN, STLB_EN)
		 STREAM_MATCH_CFG(DIR_READ)
		 STREAM_MATCH_SID_VALUE(0xE)
		 STREAM_MATCH_SID_MASK(0x1F)>,
		<18 STREAM_CFG(PTLB_ID(0x12), STLB_ID(0x28), FETCH_SIZE(SIZE2), PTLB_EN, STLB_EN)
		 STREAM_MATCH_CFG(DIR_READ)
		 STREAM_MATCH_SID_VALUE(0x16)
		 STREAM_MATCH_SID_MASK(0x1F)>,
		<19 STREAM_CFG(PTLB_ID(0x13), STLB_ID(0x29), FETCH_SIZE(SIZE2), PTLB_EN, STLB_EN)
		 STREAM_MATCH_CFG(DIR_READ)
		 STREAM_MATCH_SID_VALUE(0x7)
		 STREAM_MATCH_SID_MASK(0x1F)>,
		<20 STREAM_CFG(PTLB_ID(0x14), STLB_ID(0x2A), FETCH_SIZE(SIZE2), PTLB_EN, STLB_EN)
		 STREAM_MATCH_CFG(DIR_READ)
		 STREAM_MATCH_SID_VALUE(0xF)
		 STREAM_MATCH_SID_MASK(0x1F)>,
		<21 STREAM_CFG(PTLB_ID(0x15), STLB_ID(0x2B), FETCH_SIZE(SIZE2), PTLB_EN, STLB_EN)
		 STREAM_MATCH_CFG(DIR_READ)
		 STREAM_MATCH_SID_VALUE(0x17)
		 STREAM_MATCH_SID_MASK(0x1F)>,
		<22 STREAM_CFG(PTLB_ID(0x16), STLB_ID(0x30), FETCH_SIZE(SIZE1), PTLB_EN, STLB_EN)
		 STREAM_MATCH_CFG(DIR_READ)
		 STREAM_MATCH_SID_VALUE(0xB)
		 STREAM_MATCH_SID_MASK(0x1F)>,
		<23 STREAM_CFG(PTLB_ID(0x17), STLB_ID(0x31), FETCH_SIZE(SIZE1), PTLB_EN, STLB_EN)
		 STREAM_MATCH_CFG(DIR_READ)
		 STREAM_MATCH_SID_VALUE(0x1B)
		 STREAM_MATCH_SID_MASK(0x1F)>,
		<24 STREAM_CFG(PTLB_ID(0x18), STLB_ID(0x32), FETCH_SIZE(SIZE1), PTLB_DIS, STLB_EN)
		 STREAM_MATCH_CFG(DIR_WRITE)
		 STREAM_MATCH_SID_VALUE(0x0)
		 STREAM_MATCH_SID_MASK(0x1F)>,
		<25 STREAM_CFG(PTLB_ID(0x19), STLB_ID(0x33), FETCH_SIZE(SIZE1), PTLB_DIS, STLB_EN)
		 STREAM_MATCH_CFG(DIR_WRITE)
		 STREAM_MATCH_SID_VALUE(0x1)
		 STREAM_MATCH_SID_MASK(0x1F)>;
		pmmu3,default_stream =
		<STREAM_CFG(PTLB_ID(0x0), STLB_ID(0x8), FETCH_SIZE(SIZE16), PTLB_EN, STLB_EN)>;
		pmmu3,stream_property =
		<1 STREAM_CFG(PTLB_ID(0x1), STLB_ID(0x2), FETCH_SIZE(SIZE32), PTLB_EN, STLB_EN)
		 STREAM_MATCH_CFG(DIR_READ)
		 STREAM_MATCH_SID_VALUE(0x4)
		 STREAM_MATCH_SID_MASK(0x1F)>,
		<2 STREAM_CFG(PTLB_ID(0x2), STLB_ID(0x9), FETCH_SIZE(SIZE16), PTLB_EN, STLB_EN)
		 STREAM_MATCH_CFG(DIR_READ)
		 STREAM_MATCH_SID_VALUE(0x8)
		 STREAM_MATCH_SID_MASK(0x1F)>,
		<3 STREAM_CFG(PTLB_ID(0x3), STLB_ID(0xA), FETCH_SIZE(SIZE16), PTLB_EN, STLB_EN)
		 STREAM_MATCH_CFG(DIR_READ)
		 STREAM_MATCH_SID_VALUE(0x10)
		 STREAM_MATCH_SID_MASK(0x1F)>,
		<4 STREAM_CFG(PTLB_ID(0x4), STLB_ID(0xB), FETCH_SIZE(SIZE16), PTLB_EN, STLB_EN)
		 STREAM_MATCH_CFG(DIR_READ)
		 STREAM_MATCH_SID_VALUE(0x18)
		 STREAM_MATCH_SID_MASK(0x1F)>,
		<5 STREAM_CFG(PTLB_ID(0x5), STLB_ID(0x1C), FETCH_SIZE(SIZE2), PTLB_EN, STLB_EN)
		 STREAM_MATCH_CFG(DIR_READ)
		 STREAM_MATCH_SID_VALUE(0xC)
		 STREAM_MATCH_SID_MASK(0x1F)>,
		<6 STREAM_CFG(PTLB_ID(0x6), STLB_ID(0x1D), FETCH_SIZE(SIZE2), PTLB_EN, STLB_EN)
		 STREAM_MATCH_CFG(DIR_READ)
		 STREAM_MATCH_SID_VALUE(0x14)
		 STREAM_MATCH_SID_MASK(0x1F)>,
		<7 STREAM_CFG(PTLB_ID(0x7), STLB_ID(0x1E), FETCH_SIZE(SIZE2), PTLB_EN, STLB_EN)
		 STREAM_MATCH_CFG(DIR_READ)
		 STREAM_MATCH_SID_VALUE(0x1C)
		 STREAM_MATCH_SID_MASK(0x1F)>,
		<8 STREAM_CFG(PTLB_ID(0x8), STLB_ID(0x3), FETCH_SIZE(SIZE32), PTLB_EN, STLB_EN)
		 STREAM_MATCH_CFG(DIR_READ)
		 STREAM_MATCH_SID_VALUE(0x5)
		 STREAM_MATCH_SID_MASK(0x1F)>,
		<9 STREAM_CFG(PTLB_ID(0x9), STLB_ID(0x1F), FETCH_SIZE(SIZE2), PTLB_EN, STLB_EN)
		 STREAM_MATCH_CFG(DIR_READ)
		 STREAM_MATCH_SID_VALUE(0xD)
		 STREAM_MATCH_SID_MASK(0x1F)>,
		<10 STREAM_CFG(PTLB_ID(0xA), STLB_ID(0x20), FETCH_SIZE(SIZE2), PTLB_EN, STLB_EN)
		 STREAM_MATCH_CFG(DIR_READ)
		 STREAM_MATCH_SID_VALUE(0x15)
		 STREAM_MATCH_SID_MASK(0x1F)>,
		<11 STREAM_CFG(PTLB_ID(0xB), STLB_ID(0x21), FETCH_SIZE(SIZE2), PTLB_EN, STLB_EN)
		 STREAM_MATCH_CFG(DIR_READ)
		 STREAM_MATCH_SID_VALUE(0x1D)
		 STREAM_MATCH_SID_MASK(0x1F)>,
		<12 STREAM_CFG(PTLB_ID(0xC), STLB_ID(0x22), FETCH_SIZE(SIZE2), PTLB_EN, STLB_EN)
		 STREAM_MATCH_CFG(DIR_READ)
		 STREAM_MATCH_SID_VALUE(0x2)
		 STREAM_MATCH_SID_MASK(0x1F)>,
		<13 STREAM_CFG(PTLB_ID(0xD), STLB_ID(0x23), FETCH_SIZE(SIZE2), PTLB_EN, STLB_EN)
		 STREAM_MATCH_CFG(DIR_READ)
		 STREAM_MATCH_SID_VALUE(0xA)
		 STREAM_MATCH_SID_MASK(0x1F)>,
		<14 STREAM_CFG(PTLB_ID(0xE), STLB_ID(0x24), FETCH_SIZE(SIZE2), PTLB_EN, STLB_EN)
		 STREAM_MATCH_CFG(DIR_READ)
		 STREAM_MATCH_SID_VALUE(0x12)
		 STREAM_MATCH_SID_MASK(0x1F)>,
		<15 STREAM_CFG(PTLB_ID(0xF), STLB_ID(0x25), FETCH_SIZE(SIZE2), PTLB_EN, STLB_EN)
		 STREAM_MATCH_CFG(DIR_READ)
		 STREAM_MATCH_SID_VALUE(0x1A)
		 STREAM_MATCH_SID_MASK(0x1F)>,
		<16 STREAM_CFG(PTLB_ID(0x10), STLB_ID(0x26), FETCH_SIZE(SIZE2), PTLB_EN, STLB_EN)
		 STREAM_MATCH_CFG(DIR_READ)
		 STREAM_MATCH_SID_VALUE(0x6)
		 STREAM_MATCH_SID_MASK(0x1F)>,
		<17 STREAM_CFG(PTLB_ID(0x11), STLB_ID(0x27), FETCH_SIZE(SIZE2), PTLB_EN, STLB_EN)
		 STREAM_MATCH_CFG(DIR_READ)
		 STREAM_MATCH_SID_VALUE(0xE)
		 STREAM_MATCH_SID_MASK(0x1F)>,
		<18 STREAM_CFG(PTLB_ID(0x12), STLB_ID(0x28), FETCH_SIZE(SIZE2), PTLB_EN, STLB_EN)
		 STREAM_MATCH_CFG(DIR_READ)
		 STREAM_MATCH_SID_VALUE(0x16)
		 STREAM_MATCH_SID_MASK(0x1F)>,
		<19 STREAM_CFG(PTLB_ID(0x13), STLB_ID(0x29), FETCH_SIZE(SIZE2), PTLB_EN, STLB_EN)
		 STREAM_MATCH_CFG(DIR_READ)
		 STREAM_MATCH_SID_VALUE(0x7)
		 STREAM_MATCH_SID_MASK(0x1F)>,
		<20 STREAM_CFG(PTLB_ID(0x14), STLB_ID(0x2A), FETCH_SIZE(SIZE2), PTLB_EN, STLB_EN)
		 STREAM_MATCH_CFG(DIR_READ)
		 STREAM_MATCH_SID_VALUE(0xF)
		 STREAM_MATCH_SID_MASK(0x1F)>,
		<21 STREAM_CFG(PTLB_ID(0x15), STLB_ID(0x2B), FETCH_SIZE(SIZE2), PTLB_EN, STLB_EN)
		 STREAM_MATCH_CFG(DIR_READ)
		 STREAM_MATCH_SID_VALUE(0x17)
		 STREAM_MATCH_SID_MASK(0x1F)>,
		<22 STREAM_CFG(PTLB_ID(0x16), STLB_ID(0x39), FETCH_SIZE(SIZE1), PTLB_DIS, STLB_DIS)
		 STREAM_MATCH_CFG(DIR_WRITE)
		 STREAM_MATCH_SID_VALUE(0x10)
		 STREAM_MATCH_SID_MASK(0x1F)>;
		pmmu4,default_stream =
		<STREAM_CFG(PTLB_ID(0x0), STLB_ID(0x34), FETCH_SIZE(SIZE1), PTLB_EN, STLB_EN)>;
		pmmu4,stream_property =
		<1 STREAM_CFG(PTLB_ID(0x1), STLB_ID(0x35), FETCH_SIZE(SIZE1), PTLB_EN, STLB_EN)
		 STREAM_MATCH_CFG(DIR_READ)
		 STREAM_MATCH_SID_VALUE(0x11)
		 STREAM_MATCH_SID_MASK(0x1F)>;
		pmmu5,default_stream =
		<STREAM_CFG(PTLB_ID(0x0), STLB_ID(0x36), FETCH_SIZE(SIZE1), PTLB_EN, STLB_EN)>;
		pmmu5,stream_property =
		<1 STREAM_CFG(PTLB_ID(0x1), STLB_ID(0x37), FETCH_SIZE(SIZE1), PTLB_EN, STLB_EN)
		 STREAM_MATCH_CFG(DIR_READ)
		 STREAM_MATCH_SID_VALUE(0x13)
		 STREAM_MATCH_SID_MASK(0x1F)>;
	};

	sysmmu_hsi1_s0_stream: sysmmu_hsi1_s0_stream {
		pmmu0,default_stream =
		<STREAM_CFG(PTLB_ID(0x0), STLB_ID(0x0), FETCH_SIZE(SIZE1), PTLB_DIS, STLB_DIS)>;
	};

	sysmmu_icpu_s0_stream: sysmmu_icpu_s0_stream {
		pmmu0,default_stream =
		<STREAM_CFG(PTLB_ID(0x0), STLB_ID(0x0), FETCH_SIZE(SIZE1), PTLB_DIS, STLB_DIS)>;
		pmmu0,stream_property =
		<1 STREAM_CFG(PTLB_ID(0x1), STLB_ID(0x1), FETCH_SIZE(SIZE1), PTLB_EN, STLB_EN)
		 STREAM_MATCH_CFG(DIR_RW)
		 STREAM_MATCH_SID_VALUE(0x81)
		 STREAM_MATCH_SID_MASK(0xF81)>,
		<2 STREAM_CFG(PTLB_ID(0x2), STLB_ID(0x2), FETCH_SIZE(SIZE1), PTLB_DIS, STLB_DIS)
		 STREAM_MATCH_CFG(DIR_WRITE)
		 STREAM_MATCH_SID_VALUE(0x0)
		 STREAM_MATCH_SID_MASK(0xF83)>;
	};

	sysmmu_lme_s0_stream: sysmmu_lme_s0_stream {
		pmmu0,default_stream =
		<STREAM_CFG(PTLB_ID(0x0), STLB_ID(0x0), FETCH_SIZE(SIZE8), PTLB_EN, STLB_EN)>;
		pmmu0,stream_property =
		<1 STREAM_CFG(PTLB_ID(0x4), STLB_ID(0x8), FETCH_SIZE(SIZE1), PTLB_EN, STLB_EN)
		 STREAM_MATCH_CFG(DIR_READ)
		 STREAM_MATCH_SID_VALUE(0x1)
		 STREAM_MATCH_SID_MASK(0xF83)>,
		<2 STREAM_CFG(PTLB_ID(0x2), STLB_ID(0x1), FETCH_SIZE(SIZE8), PTLB_EN, STLB_EN)
		 STREAM_MATCH_CFG(DIR_WRITE)
		 STREAM_MATCH_SID_VALUE(0x0)
		 STREAM_MATCH_SID_MASK(0xF83)>,
		<3 STREAM_CFG(PTLB_ID(0x5), STLB_ID(0x9), FETCH_SIZE(SIZE1), PTLB_DIS, STLB_EN)
		 STREAM_MATCH_CFG(DIR_WRITE)
		 STREAM_MATCH_SID_VALUE(0x1)
		 STREAM_MATCH_SID_MASK(0xF83)>,
		<4 STREAM_CFG(PTLB_ID(0x3), STLB_ID(0x2), FETCH_SIZE(SIZE8), PTLB_EN, STLB_EN)
		 STREAM_MATCH_CFG(DIR_WRITE)
		 STREAM_MATCH_SID_VALUE(0x2)
		 STREAM_MATCH_SID_MASK(0xF83)>,
		<5 STREAM_CFG(PTLB_ID(0x6), STLB_ID(0xA), FETCH_SIZE(SIZE1), PTLB_DIS, STLB_EN)
		 STREAM_MATCH_CFG(DIR_WRITE)
		 STREAM_MATCH_SID_VALUE(0x3)
		 STREAM_MATCH_SID_MASK(0xF83)>,
		<6 STREAM_CFG(PTLB_ID(0x1), STLB_ID(0x3), FETCH_SIZE(SIZE8), PTLB_EN, STLB_EN)
		 STREAM_MATCH_CFG(DIR_READ)
		 STREAM_MATCH_SID_VALUE(0x80)
		 STREAM_MATCH_SID_MASK(0xF81)>,
		<7 STREAM_CFG(PTLB_ID(0x7), STLB_ID(0xB), FETCH_SIZE(SIZE1), PTLB_EN, STLB_EN)
		 STREAM_MATCH_CFG(DIR_READ)
		 STREAM_MATCH_SID_VALUE(0x81)
		 STREAM_MATCH_SID_MASK(0xF81)>,
		<8 STREAM_CFG(PTLB_ID(0x8), STLB_ID(0x16), FETCH_SIZE(SIZE1), PTLB_EN, STLB_DIS)
		 STREAM_MATCH_CFG(DIR_WRITE)
		 STREAM_MATCH_SID_VALUE(0x100)
		 STREAM_MATCH_SID_MASK(0xF81)>,
		<9 STREAM_CFG(PTLB_ID(0xA), STLB_ID(0x17), FETCH_SIZE(SIZE1), PTLB_EN, STLB_DIS)
		 STREAM_MATCH_CFG(DIR_WRITE)
		 STREAM_MATCH_SID_VALUE(0x180)
		 STREAM_MATCH_SID_MASK(0xF81)>,
		<10 STREAM_CFG(PTLB_ID(0x9), STLB_ID(0x18), FETCH_SIZE(SIZE1), PTLB_EN, STLB_DIS)
		 STREAM_MATCH_CFG(DIR_READ)
		 STREAM_MATCH_SID_VALUE(0x200)
		 STREAM_MATCH_SID_MASK(0xF81)>,
		<11 STREAM_CFG(PTLB_ID(0xB), STLB_ID(0x19), FETCH_SIZE(SIZE1), PTLB_DIS, STLB_DIS)
		 STREAM_MATCH_CFG(DIR_WRITE)
		 STREAM_MATCH_SID_VALUE(0x200)
		 STREAM_MATCH_SID_MASK(0xF81)>;
		pmmu1,default_stream =
		<STREAM_CFG(PTLB_ID(0x0), STLB_ID(0x4), FETCH_SIZE(SIZE8), PTLB_EN, STLB_EN)>;
		pmmu1,stream_property =
		<1 STREAM_CFG(PTLB_ID(0x4), STLB_ID(0xC), FETCH_SIZE(SIZE1), PTLB_EN, STLB_EN)
		 STREAM_MATCH_CFG(DIR_READ)
		 STREAM_MATCH_SID_VALUE(0x1)
		 STREAM_MATCH_SID_MASK(0xF83)>,
		<2 STREAM_CFG(PTLB_ID(0x2), STLB_ID(0x5), FETCH_SIZE(SIZE8), PTLB_EN, STLB_EN)
		 STREAM_MATCH_CFG(DIR_WRITE)
		 STREAM_MATCH_SID_VALUE(0x0)
		 STREAM_MATCH_SID_MASK(0xF83)>,
		<3 STREAM_CFG(PTLB_ID(0x5), STLB_ID(0xD), FETCH_SIZE(SIZE1), PTLB_DIS, STLB_EN)
		 STREAM_MATCH_CFG(DIR_WRITE)
		 STREAM_MATCH_SID_VALUE(0x1)
		 STREAM_MATCH_SID_MASK(0xF83)>,
		<4 STREAM_CFG(PTLB_ID(0x3), STLB_ID(0x6), FETCH_SIZE(SIZE8), PTLB_EN, STLB_EN)
		 STREAM_MATCH_CFG(DIR_WRITE)
		 STREAM_MATCH_SID_VALUE(0x2)
		 STREAM_MATCH_SID_MASK(0xF83)>,
		<5 STREAM_CFG(PTLB_ID(0x6), STLB_ID(0xE), FETCH_SIZE(SIZE1), PTLB_DIS, STLB_EN)
		 STREAM_MATCH_CFG(DIR_WRITE)
		 STREAM_MATCH_SID_VALUE(0x3)
		 STREAM_MATCH_SID_MASK(0xF83)>,
		<6 STREAM_CFG(PTLB_ID(0x1), STLB_ID(0x7), FETCH_SIZE(SIZE8), PTLB_EN, STLB_EN)
		 STREAM_MATCH_CFG(DIR_READ)
		 STREAM_MATCH_SID_VALUE(0x80)
		 STREAM_MATCH_SID_MASK(0xF81)>,
		<7 STREAM_CFG(PTLB_ID(0x7), STLB_ID(0xF), FETCH_SIZE(SIZE1), PTLB_EN, STLB_EN)
		 STREAM_MATCH_CFG(DIR_READ)
		 STREAM_MATCH_SID_VALUE(0x81)
		 STREAM_MATCH_SID_MASK(0xF81)>,
		<8 STREAM_CFG(PTLB_ID(0x8), STLB_ID(0x10), FETCH_SIZE(SIZE1), PTLB_EN, STLB_EN)
		 STREAM_MATCH_CFG(DIR_WRITE)
		 STREAM_MATCH_SID_VALUE(0x80)
		 STREAM_MATCH_SID_MASK(0xF81)>,
		<9 STREAM_CFG(PTLB_ID(0x9), STLB_ID(0x1A), FETCH_SIZE(SIZE1), PTLB_EN, STLB_DIS)
		 STREAM_MATCH_CFG(DIR_WRITE)
		 STREAM_MATCH_SID_VALUE(0x100)
		 STREAM_MATCH_SID_MASK(0xF81)>,
		<10 STREAM_CFG(PTLB_ID(0xB), STLB_ID(0x1D), FETCH_SIZE(SIZE1), PTLB_EN, STLB_DIS)
		 STREAM_MATCH_CFG(DIR_WRITE)
		 STREAM_MATCH_SID_VALUE(0x180)
		 STREAM_MATCH_SID_MASK(0xF81)>,
		<11 STREAM_CFG(PTLB_ID(0xA), STLB_ID(0x1B), FETCH_SIZE(SIZE1), PTLB_EN, STLB_DIS)
		 STREAM_MATCH_CFG(DIR_READ)
		 STREAM_MATCH_SID_VALUE(0x200)
		 STREAM_MATCH_SID_MASK(0xF81)>,
		<12 STREAM_CFG(PTLB_ID(0xC), STLB_ID(0x1E), FETCH_SIZE(SIZE1), PTLB_DIS, STLB_DIS)
		 STREAM_MATCH_CFG(DIR_WRITE)
		 STREAM_MATCH_SID_VALUE(0x200)
		 STREAM_MATCH_SID_MASK(0xF81)>;
		pmmu2,default_stream =
		<STREAM_CFG(PTLB_ID(0x5), STLB_ID(0x1C), FETCH_SIZE(SIZE1), PTLB_DIS, STLB_DIS)>;
		pmmu2,stream_property =
		<1 STREAM_CFG(PTLB_ID(0x1), STLB_ID(0x11), FETCH_SIZE(SIZE1), PTLB_DIS, STLB_EN)
		 STREAM_MATCH_CFG(DIR_WRITE)
		 STREAM_MATCH_SID_VALUE(0x0)
		 STREAM_MATCH_SID_MASK(0xF81)>,
		<2 STREAM_CFG(PTLB_ID(0x0), STLB_ID(0x15), FETCH_SIZE(SIZE1), PTLB_DIS, STLB_DIS)
		 STREAM_MATCH_CFG(DIR_READ)
		 STREAM_MATCH_SID_VALUE(0x80)
		 STREAM_MATCH_SID_MASK(0xF81)>,
		<3 STREAM_CFG(PTLB_ID(0x2), STLB_ID(0x12), FETCH_SIZE(SIZE1), PTLB_DIS, STLB_EN)
		 STREAM_MATCH_CFG(DIR_WRITE)
		 STREAM_MATCH_SID_VALUE(0x80)
		 STREAM_MATCH_SID_MASK(0xF81)>,
		<4 STREAM_CFG(PTLB_ID(0x3), STLB_ID(0x13), FETCH_SIZE(SIZE1), PTLB_EN, STLB_EN)
		 STREAM_MATCH_CFG(DIR_READ)
		 STREAM_MATCH_SID_VALUE(0x100)
		 STREAM_MATCH_SID_MASK(0xF81)>,
		<5 STREAM_CFG(PTLB_ID(0x4), STLB_ID(0x14), FETCH_SIZE(SIZE1), PTLB_DIS, STLB_EN)
		 STREAM_MATCH_CFG(DIR_WRITE)
		 STREAM_MATCH_SID_VALUE(0x100)
		 STREAM_MATCH_SID_MASK(0xF81)>,
		<6 STREAM_CFG(PTLB_ID(0x6), STLB_ID(0x1F), FETCH_SIZE(SIZE1), PTLB_DIS, STLB_DIS)
		 STREAM_MATCH_CFG(DIR_WRITE)
		 STREAM_MATCH_SID_VALUE(0x180)
		 STREAM_MATCH_SID_MASK(0xF81)>;
	};

	sysmmu_m2m_s0_stream: sysmmu_m2m_s0_stream {
		pmmu0,default_stream =
		<STREAM_CFG(PTLB_ID(0x1), STLB_ID(0xD), FETCH_SIZE(SIZE8), PTLB_DIS, STLB_DIS)>;
		pmmu0,stream_property =
		<1 STREAM_CFG(PTLB_ID(0x2), STLB_ID(0xE), FETCH_SIZE(SIZE8), PTLB_DIS, STLB_DIS)
		 STREAM_MATCH_CFG(DIR_RW)
		 STREAM_MATCH_SID_VALUE(0x80)
		 STREAM_MATCH_SID_MASK(0xF80)>,
		<2 STREAM_CFG(PTLB_ID(0x4), STLB_ID(0x10), FETCH_SIZE(SIZE1), PTLB_EN, STLB_DIS)
		 STREAM_MATCH_CFG(DIR_READ)
		 STREAM_MATCH_SID_VALUE(0x101)
		 STREAM_MATCH_SID_MASK(0xF81)>,
		<3 STREAM_CFG(PTLB_ID(0x5), STLB_ID(0x7), FETCH_SIZE(SIZE1), PTLB_DIS, STLB_EN)
		 STREAM_MATCH_CFG(DIR_WRITE)
		 STREAM_MATCH_SID_VALUE(0x104)
		 STREAM_MATCH_SID_MASK(0xF8F)>,
		<4 STREAM_CFG(PTLB_ID(0x6), STLB_ID(0x8), FETCH_SIZE(SIZE1), PTLB_DIS, STLB_EN)
		 STREAM_MATCH_CFG(DIR_WRITE)
		 STREAM_MATCH_SID_VALUE(0x106)
		 STREAM_MATCH_SID_MASK(0xF8F)>,
		<5 STREAM_CFG(PTLB_ID(0x0), STLB_ID(0xC), FETCH_SIZE(SIZE32), PTLB_DIS, STLB_EN)
		 STREAM_MATCH_CFG(DIR_READ)
		 STREAM_MATCH_SID_VALUE(0x100)
		 STREAM_MATCH_SID_MASK(0xF81)>,
		<6 STREAM_CFG(PTLB_ID(0x0), STLB_ID(0xC), FETCH_SIZE(SIZE32), PTLB_DIS, STLB_EN)
		 STREAM_MATCH_CFG(DIR_WRITE)
		 STREAM_MATCH_SID_VALUE(0x108)
		 STREAM_MATCH_SID_MASK(0xF8F)>,
		<7 STREAM_CFG(PTLB_ID(0x0), STLB_ID(0xC), FETCH_SIZE(SIZE32), PTLB_DIS, STLB_EN)
		 STREAM_MATCH_CFG(DIR_WRITE)
		 STREAM_MATCH_SID_VALUE(0x100)
		 STREAM_MATCH_SID_MASK(0xF8F)>,
		<8 STREAM_CFG(PTLB_ID(0x0), STLB_ID(0xC), FETCH_SIZE(SIZE32), PTLB_DIS, STLB_EN)
		 STREAM_MATCH_CFG(DIR_WRITE)
		 STREAM_MATCH_SID_VALUE(0x102)
		 STREAM_MATCH_SID_MASK(0xF8F)>,
		<9 STREAM_CFG(PTLB_ID(0xA), STLB_ID(0x11), FETCH_SIZE(SIZE1), PTLB_DIS, STLB_DIS)
		 STREAM_MATCH_CFG(DIR_WRITE)
		 STREAM_MATCH_SID_VALUE(0x181)
		 STREAM_MATCH_SID_MASK(0xF81)>,
		<10 STREAM_CFG(PTLB_ID(0x3), STLB_ID(0xF), FETCH_SIZE(SIZE8), PTLB_DIS, STLB_DIS)
		 STREAM_MATCH_CFG(DIR_RW)
		 STREAM_MATCH_SID_VALUE(0x200)
		 STREAM_MATCH_SID_MASK(0xF80)>,
		<11 STREAM_CFG(PTLB_ID(0xB), STLB_ID(0x0), FETCH_SIZE(SIZE8), PTLB_DIS, STLB_EN)
		 STREAM_MATCH_CFG(DIR_READ)
		 STREAM_MATCH_SID_VALUE(0x280)
		 STREAM_MATCH_SID_MASK(0xF87)>,
		<12 STREAM_CFG(PTLB_ID(0xC), STLB_ID(0x3), FETCH_SIZE(SIZE4), PTLB_DIS, STLB_EN)
		 STREAM_MATCH_CFG(DIR_READ)
		 STREAM_MATCH_SID_VALUE(0x281)
		 STREAM_MATCH_SID_MASK(0xF87)>,
		<13 STREAM_CFG(PTLB_ID(0xD), STLB_ID(0x1), FETCH_SIZE(SIZE8), PTLB_DIS, STLB_EN)
		 STREAM_MATCH_CFG(DIR_READ)
		 STREAM_MATCH_SID_VALUE(0x282)
		 STREAM_MATCH_SID_MASK(0xF87)>,
		<14 STREAM_CFG(PTLB_ID(0xE), STLB_ID(0x4), FETCH_SIZE(SIZE4), PTLB_DIS, STLB_EN)
		 STREAM_MATCH_CFG(DIR_READ)
		 STREAM_MATCH_SID_VALUE(0x283)
		 STREAM_MATCH_SID_MASK(0xF87)>,
		<15 STREAM_CFG(PTLB_ID(0xF), STLB_ID(0x2), FETCH_SIZE(SIZE8), PTLB_DIS, STLB_EN)
		 STREAM_MATCH_CFG(DIR_READ)
		 STREAM_MATCH_SID_VALUE(0x284)
		 STREAM_MATCH_SID_MASK(0xF87)>,
		<16 STREAM_CFG(PTLB_ID(0x7), STLB_ID(0x9), FETCH_SIZE(SIZE1), PTLB_DIS, STLB_EN)
		 STREAM_MATCH_CFG(DIR_READ)
		 STREAM_MATCH_SID_VALUE(0x285)
		 STREAM_MATCH_SID_MASK(0xF87)>,
		<17 STREAM_CFG(PTLB_ID(0xC), STLB_ID(0x3), FETCH_SIZE(SIZE4), PTLB_DIS, STLB_EN)
		 STREAM_MATCH_CFG(DIR_READ)
		 STREAM_MATCH_SID_VALUE(0x286)
		 STREAM_MATCH_SID_MASK(0xF87)>,
		<18 STREAM_CFG(PTLB_ID(0xB), STLB_ID(0x0), FETCH_SIZE(SIZE8), PTLB_DIS, STLB_EN)
		 STREAM_MATCH_CFG(DIR_READ)
		 STREAM_MATCH_SID_VALUE(0x287)
		 STREAM_MATCH_SID_MASK(0xF87)>,
		<19 STREAM_CFG(PTLB_ID(0x10), STLB_ID(0x5), FETCH_SIZE(SIZE4), PTLB_DIS, STLB_EN)
		 STREAM_MATCH_CFG(DIR_WRITE)
		 STREAM_MATCH_SID_VALUE(0x280)
		 STREAM_MATCH_SID_MASK(0xF87)>,
		<20 STREAM_CFG(PTLB_ID(0x11), STLB_ID(0x6), FETCH_SIZE(SIZE2), PTLB_DIS, STLB_EN)
		 STREAM_MATCH_CFG(DIR_WRITE)
		 STREAM_MATCH_SID_VALUE(0x281)
		 STREAM_MATCH_SID_MASK(0xF87)>,
		<21 STREAM_CFG(PTLB_ID(0x8), STLB_ID(0xA), FETCH_SIZE(SIZE1), PTLB_DIS, STLB_EN)
		 STREAM_MATCH_CFG(DIR_WRITE)
		 STREAM_MATCH_SID_VALUE(0x282)
		 STREAM_MATCH_SID_MASK(0xF87)>,
		<22 STREAM_CFG(PTLB_ID(0x9), STLB_ID(0xB), FETCH_SIZE(SIZE1), PTLB_DIS, STLB_EN)
		 STREAM_MATCH_CFG(DIR_WRITE)
		 STREAM_MATCH_SID_VALUE(0x283)
		 STREAM_MATCH_SID_MASK(0xF87)>,
		<23 STREAM_CFG(PTLB_ID(0x11), STLB_ID(0x6), FETCH_SIZE(SIZE2), PTLB_DIS, STLB_EN)
		 STREAM_MATCH_CFG(DIR_WRITE)
		 STREAM_MATCH_SID_VALUE(0x284)
		 STREAM_MATCH_SID_MASK(0xF87)>,
		<24 STREAM_CFG(PTLB_ID(0x10), STLB_ID(0x5), FETCH_SIZE(SIZE4), PTLB_DIS, STLB_EN)
		 STREAM_MATCH_CFG(DIR_WRITE)
		 STREAM_MATCH_SID_VALUE(0x285)
		 STREAM_MATCH_SID_MASK(0xF87)>;
	};

	sysmmu_m2m_s1_stream: sysmmu_m2m_s1_stream {
		pmmu0,default_stream =
		<STREAM_CFG(PTLB_ID(0x0), STLB_ID(0x0), FETCH_SIZE(SIZE32), PTLB_EN, STLB_EN)>;
		pmmu0,stream_property =
		<1 STREAM_CFG(PTLB_ID(0x4), STLB_ID(0x4), FETCH_SIZE(SIZE1), PTLB_EN, STLB_EN)
		 STREAM_MATCH_CFG(DIR_READ)
		 STREAM_MATCH_SID_VALUE(0x1)
		 STREAM_MATCH_SID_MASK(0xF83)>,
		<2 STREAM_CFG(PTLB_ID(0x2), STLB_ID(0x2), FETCH_SIZE(SIZE16), PTLB_EN, STLB_EN)
		 STREAM_MATCH_CFG(DIR_READ)
		 STREAM_MATCH_SID_VALUE(0x2)
		 STREAM_MATCH_SID_MASK(0xF83)>,
		<3 STREAM_CFG(PTLB_ID(0x5), STLB_ID(0x5), FETCH_SIZE(SIZE1), PTLB_EN, STLB_EN)
		 STREAM_MATCH_CFG(DIR_READ)
		 STREAM_MATCH_SID_VALUE(0x3)
		 STREAM_MATCH_SID_MASK(0xF83)>,
		<4 STREAM_CFG(PTLB_ID(0x3), STLB_ID(0x3), FETCH_SIZE(SIZE16), PTLB_DIS, STLB_EN)
		 STREAM_MATCH_CFG(DIR_WRITE)
		 STREAM_MATCH_SID_VALUE(0x0)
		 STREAM_MATCH_SID_MASK(0xF81)>,
		<5 STREAM_CFG(PTLB_ID(0x6), STLB_ID(0x6), FETCH_SIZE(SIZE1), PTLB_DIS, STLB_EN)
		 STREAM_MATCH_CFG(DIR_WRITE)
		 STREAM_MATCH_SID_VALUE(0x1)
		 STREAM_MATCH_SID_MASK(0xF81)>,
		<6 STREAM_CFG(PTLB_ID(0x1), STLB_ID(0x1), FETCH_SIZE(SIZE32), PTLB_DIS, STLB_EN)
		 STREAM_MATCH_CFG(DIR_WRITE)
		 STREAM_MATCH_SID_VALUE(0x80)
		 STREAM_MATCH_SID_MASK(0xF81)>,
		<7 STREAM_CFG(PTLB_ID(0x7), STLB_ID(0x7), FETCH_SIZE(SIZE1), PTLB_DIS, STLB_EN)
		 STREAM_MATCH_CFG(DIR_WRITE)
		 STREAM_MATCH_SID_VALUE(0x81)
		 STREAM_MATCH_SID_MASK(0xF81)>;
	};

	sysmmu_mcsc_s0_stream: sysmmu_mcsc_s0_stream {
		pmmu0,default_stream =
		<STREAM_CFG(PTLB_ID(0xE), STLB_ID(0x1F), FETCH_SIZE(SIZE1), PTLB_DIS, STLB_DIS)>;
		pmmu0,stream_property =
		<1 STREAM_CFG(PTLB_ID(0x2), STLB_ID(0x3), FETCH_SIZE(SIZE1), PTLB_DIS, STLB_EN)
		 STREAM_MATCH_CFG(DIR_WRITE)
		 STREAM_MATCH_SID_VALUE(0x0)
		 STREAM_MATCH_SID_MASK(0xF87)>,
		<2 STREAM_CFG(PTLB_ID(0x3), STLB_ID(0x4), FETCH_SIZE(SIZE1), PTLB_DIS, STLB_EN)
		 STREAM_MATCH_CFG(DIR_WRITE)
		 STREAM_MATCH_SID_VALUE(0x1)
		 STREAM_MATCH_SID_MASK(0xF87)>,
		<3 STREAM_CFG(PTLB_ID(0x4), STLB_ID(0x5), FETCH_SIZE(SIZE1), PTLB_DIS, STLB_EN)
		 STREAM_MATCH_CFG(DIR_WRITE)
		 STREAM_MATCH_SID_VALUE(0x2)
		 STREAM_MATCH_SID_MASK(0xF87)>,
		<4 STREAM_CFG(PTLB_ID(0x5), STLB_ID(0x6), FETCH_SIZE(SIZE1), PTLB_DIS, STLB_EN)
		 STREAM_MATCH_CFG(DIR_WRITE)
		 STREAM_MATCH_SID_VALUE(0x3)
		 STREAM_MATCH_SID_MASK(0xF87)>,
		<5 STREAM_CFG(PTLB_ID(0x6), STLB_ID(0x7), FETCH_SIZE(SIZE1), PTLB_DIS, STLB_EN)
		 STREAM_MATCH_CFG(DIR_WRITE)
		 STREAM_MATCH_SID_VALUE(0x4)
		 STREAM_MATCH_SID_MASK(0xF87)>,
		<6 STREAM_CFG(PTLB_ID(0x7), STLB_ID(0x8), FETCH_SIZE(SIZE1), PTLB_DIS, STLB_EN)
		 STREAM_MATCH_CFG(DIR_WRITE)
		 STREAM_MATCH_SID_VALUE(0x80)
		 STREAM_MATCH_SID_MASK(0xF87)>,
		<7 STREAM_CFG(PTLB_ID(0x8), STLB_ID(0x9), FETCH_SIZE(SIZE1), PTLB_DIS, STLB_EN)
		 STREAM_MATCH_CFG(DIR_WRITE)
		 STREAM_MATCH_SID_VALUE(0x82)
		 STREAM_MATCH_SID_MASK(0xF87)>,
		<8 STREAM_CFG(PTLB_ID(0x9), STLB_ID(0xA), FETCH_SIZE(SIZE1), PTLB_DIS, STLB_EN)
		 STREAM_MATCH_CFG(DIR_WRITE)
		 STREAM_MATCH_SID_VALUE(0x84)
		 STREAM_MATCH_SID_MASK(0xF87)>,
		<9 STREAM_CFG(PTLB_ID(0x10), STLB_ID(0x1D), FETCH_SIZE(SIZE1), PTLB_DIS, STLB_DIS)
		 STREAM_MATCH_CFG(DIR_WRITE)
		 STREAM_MATCH_SID_VALUE(0x100)
		 STREAM_MATCH_SID_MASK(0xF81)>,
		<10 STREAM_CFG(PTLB_ID(0x11), STLB_ID(0x21), FETCH_SIZE(SIZE1), PTLB_DIS, STLB_DIS)
		 STREAM_MATCH_CFG(DIR_WRITE)
		 STREAM_MATCH_SID_VALUE(0x180)
		 STREAM_MATCH_SID_MASK(0xF81)>,
		<11 STREAM_CFG(PTLB_ID(0xF), STLB_ID(0x20), FETCH_SIZE(SIZE1), PTLB_DIS, STLB_DIS)
		 STREAM_MATCH_CFG(DIR_READ)
		 STREAM_MATCH_SID_VALUE(0x200)
		 STREAM_MATCH_SID_MASK(0xF81)>,
		<12 STREAM_CFG(PTLB_ID(0xA), STLB_ID(0xB), FETCH_SIZE(SIZE1), PTLB_EN, STLB_EN)
		 STREAM_MATCH_CFG(DIR_READ)
		 STREAM_MATCH_SID_VALUE(0x280)
		 STREAM_MATCH_SID_MASK(0xF81)>,
		<13 STREAM_CFG(PTLB_ID(0x12), STLB_ID(0x22), FETCH_SIZE(SIZE1), PTLB_DIS, STLB_DIS)
		 STREAM_MATCH_CFG(DIR_WRITE)
		 STREAM_MATCH_SID_VALUE(0x280)
		 STREAM_MATCH_SID_MASK(0xF81)>,
		<14 STREAM_CFG(PTLB_ID(0xB), STLB_ID(0xC), FETCH_SIZE(SIZE1), PTLB_EN, STLB_EN)
		 STREAM_MATCH_CFG(DIR_READ)
		 STREAM_MATCH_SID_VALUE(0x300)
		 STREAM_MATCH_SID_MASK(0xF81)>,
		<15 STREAM_CFG(PTLB_ID(0x0), STLB_ID(0x1E), FETCH_SIZE(SIZE32), PTLB_EN, STLB_EN)
		 STREAM_MATCH_CFG(DIR_READ)
		 STREAM_MATCH_SID_VALUE(0x380)
		 STREAM_MATCH_SID_MASK(0xF81)>,
		<16 STREAM_CFG(PTLB_ID(0xC), STLB_ID(0x1), FETCH_SIZE(SIZE1), PTLB_EN, STLB_DIS)
		 STREAM_MATCH_CFG(DIR_READ)
		 STREAM_MATCH_SID_VALUE(0x381)
		 STREAM_MATCH_SID_MASK(0xF81)>,
		<17 STREAM_CFG(PTLB_ID(0x1), STLB_ID(0x1E), FETCH_SIZE(SIZE32), PTLB_EN, STLB_EN)
		 STREAM_MATCH_CFG(DIR_READ)
		 STREAM_MATCH_SID_VALUE(0x400)
		 STREAM_MATCH_SID_MASK(0xF81)>,
		<18 STREAM_CFG(PTLB_ID(0xD), STLB_ID(0x1), FETCH_SIZE(SIZE1), PTLB_EN, STLB_DIS)
		 STREAM_MATCH_CFG(DIR_READ)
		 STREAM_MATCH_SID_VALUE(0x401)
		 STREAM_MATCH_SID_MASK(0xF81)>;
		pmmu1,default_stream =
		<STREAM_CFG(PTLB_ID(0x1), STLB_ID(0xD), FETCH_SIZE(SIZE1), PTLB_DIS, STLB_EN)>;
		pmmu1,stream_property =
		<1 STREAM_CFG(PTLB_ID(0x2), STLB_ID(0xE), FETCH_SIZE(SIZE1), PTLB_DIS, STLB_EN)
		 STREAM_MATCH_CFG(DIR_WRITE)
		 STREAM_MATCH_SID_VALUE(0x1)
		 STREAM_MATCH_SID_MASK(0xF87)>,
		<2 STREAM_CFG(PTLB_ID(0x3), STLB_ID(0xF), FETCH_SIZE(SIZE1), PTLB_DIS, STLB_EN)
		 STREAM_MATCH_CFG(DIR_WRITE)
		 STREAM_MATCH_SID_VALUE(0x2)
		 STREAM_MATCH_SID_MASK(0xF87)>,
		<3 STREAM_CFG(PTLB_ID(0x4), STLB_ID(0x10), FETCH_SIZE(SIZE1), PTLB_DIS, STLB_EN)
		 STREAM_MATCH_CFG(DIR_WRITE)
		 STREAM_MATCH_SID_VALUE(0x3)
		 STREAM_MATCH_SID_MASK(0xF87)>,
		<4 STREAM_CFG(PTLB_ID(0x5), STLB_ID(0x11), FETCH_SIZE(SIZE1), PTLB_DIS, STLB_EN)
		 STREAM_MATCH_CFG(DIR_WRITE)
		 STREAM_MATCH_SID_VALUE(0x4)
		 STREAM_MATCH_SID_MASK(0xF87)>,
		<5 STREAM_CFG(PTLB_ID(0x6), STLB_ID(0x12), FETCH_SIZE(SIZE1), PTLB_DIS, STLB_EN)
		 STREAM_MATCH_CFG(DIR_WRITE)
		 STREAM_MATCH_SID_VALUE(0x80)
		 STREAM_MATCH_SID_MASK(0xF87)>,
		<6 STREAM_CFG(PTLB_ID(0x7), STLB_ID(0x13), FETCH_SIZE(SIZE1), PTLB_DIS, STLB_EN)
		 STREAM_MATCH_CFG(DIR_WRITE)
		 STREAM_MATCH_SID_VALUE(0x82)
		 STREAM_MATCH_SID_MASK(0xF87)>,
		<7 STREAM_CFG(PTLB_ID(0x8), STLB_ID(0x14), FETCH_SIZE(SIZE1), PTLB_DIS, STLB_EN)
		 STREAM_MATCH_CFG(DIR_WRITE)
		 STREAM_MATCH_SID_VALUE(0x84)
		 STREAM_MATCH_SID_MASK(0xF87)>,
		<8 STREAM_CFG(PTLB_ID(0x9), STLB_ID(0x15), FETCH_SIZE(SIZE1), PTLB_EN, STLB_EN)
		 STREAM_MATCH_CFG(DIR_READ)
		 STREAM_MATCH_SID_VALUE(0x100)
		 STREAM_MATCH_SID_MASK(0xF81)>,
		<9 STREAM_CFG(PTLB_ID(0xA), STLB_ID(0x16), FETCH_SIZE(SIZE1), PTLB_EN, STLB_EN)
		 STREAM_MATCH_CFG(DIR_READ)
		 STREAM_MATCH_SID_VALUE(0x101)
		 STREAM_MATCH_SID_MASK(0xF81)>,
		<10 STREAM_CFG(PTLB_ID(0xB), STLB_ID(0x17), FETCH_SIZE(SIZE1), PTLB_EN, STLB_EN)
		 STREAM_MATCH_CFG(DIR_READ)
		 STREAM_MATCH_SID_VALUE(0x180)
		 STREAM_MATCH_SID_MASK(0xF81)>,
		<11 STREAM_CFG(PTLB_ID(0x0), STLB_ID(0x0), FETCH_SIZE(SIZE16), PTLB_DIS, STLB_EN)
		 STREAM_MATCH_CFG(DIR_READ)
		 STREAM_MATCH_SID_VALUE(0x200)
		 STREAM_MATCH_SID_MASK(0xF81)>;
		pmmu2,default_stream =
		<STREAM_CFG(PTLB_ID(0x0), STLB_ID(0x18), FETCH_SIZE(SIZE1), PTLB_DIS, STLB_EN)>;
		pmmu2,stream_property =
		<1 STREAM_CFG(PTLB_ID(0x1), STLB_ID(0x19), FETCH_SIZE(SIZE1), PTLB_DIS, STLB_EN)
		 STREAM_MATCH_CFG(DIR_WRITE)
		 STREAM_MATCH_SID_VALUE(0x2)
		 STREAM_MATCH_SID_MASK(0xF8F)>,
		<2 STREAM_CFG(PTLB_ID(0x2), STLB_ID(0x1A), FETCH_SIZE(SIZE1), PTLB_DIS, STLB_EN)
		 STREAM_MATCH_CFG(DIR_WRITE)
		 STREAM_MATCH_SID_VALUE(0x4)
		 STREAM_MATCH_SID_MASK(0xF8F)>,
		<3 STREAM_CFG(PTLB_ID(0x3), STLB_ID(0x1B), FETCH_SIZE(SIZE1), PTLB_DIS, STLB_EN)
		 STREAM_MATCH_CFG(DIR_WRITE)
		 STREAM_MATCH_SID_VALUE(0x80)
		 STREAM_MATCH_SID_MASK(0xF81)>,
		<4 STREAM_CFG(PTLB_ID(0x4), STLB_ID(0x1C), FETCH_SIZE(SIZE1), PTLB_DIS, STLB_EN)
		 STREAM_MATCH_CFG(DIR_WRITE)
		 STREAM_MATCH_SID_VALUE(0x81)
		 STREAM_MATCH_SID_MASK(0xF81)>,
		<5 STREAM_CFG(PTLB_ID(0x5), STLB_ID(0x2), FETCH_SIZE(SIZE2), PTLB_DIS, STLB_EN)
		 STREAM_MATCH_CFG(DIR_WRITE)
		 STREAM_MATCH_SID_VALUE(0x100)
		 STREAM_MATCH_SID_MASK(0xF81)>;
	};

	sysmmu_mfc_s0_stream: sysmmu_mfc_s0_stream {
		pmmu0,default_stream =
		<STREAM_CFG(PTLB_ID(0x0), STLB_ID(0x1), FETCH_SIZE(SIZE4), PTLB_DIS, STLB_DIS)>;
		pmmu1,default_stream =
		<STREAM_CFG(PTLB_ID(0x0), STLB_ID(0x0), FETCH_SIZE(SIZE4), PTLB_DIS, STLB_EN)>;
		pmmu1,stream_property =
		<1 STREAM_CFG(PTLB_ID(0x2), STLB_ID(0x3), FETCH_SIZE(SIZE1), PTLB_DIS, STLB_DIS)
		 STREAM_MATCH_CFG(DIR_WRITE)
		 STREAM_MATCH_SID_VALUE(0x80)
		 STREAM_MATCH_SID_MASK(0xF80)>,
		<2 STREAM_CFG(PTLB_ID(0x1), STLB_ID(0x2), FETCH_SIZE(SIZE1), PTLB_DIS, STLB_DIS)
		 STREAM_MATCH_CFG(DIR_RW)
		 STREAM_MATCH_SID_VALUE(0x100)
		 STREAM_MATCH_SID_MASK(0xF80)>;
	};

	sysmmu_mfd_s0_stream: sysmmu_mfd_s0_stream {
		pmmu0,default_stream =
		<STREAM_CFG(PTLB_ID(0x0), STLB_ID(0x1), FETCH_SIZE(SIZE4), PTLB_DIS, STLB_DIS)>;
		pmmu1,default_stream =
		<STREAM_CFG(PTLB_ID(0x0), STLB_ID(0x0), FETCH_SIZE(SIZE4), PTLB_DIS, STLB_EN)>;
		pmmu1,stream_property =
		<1 STREAM_CFG(PTLB_ID(0x1), STLB_ID(0x2), FETCH_SIZE(SIZE1), PTLB_DIS, STLB_DIS)
		 STREAM_MATCH_CFG(DIR_WRITE)
		 STREAM_MATCH_SID_VALUE(0x80)
		 STREAM_MATCH_SID_MASK(0xF80)>;
	};

	sysmmu_mlsc_s0_stream: sysmmu_mlsc_s0_stream {
		pmmu0,default_stream =
		<STREAM_CFG(PTLB_ID(0x0), STLB_ID(0x0), FETCH_SIZE(SIZE1), PTLB_EN, STLB_EN)>;
		pmmu0,stream_property =
		<1 STREAM_CFG(PTLB_ID(0x1), STLB_ID(0x1), FETCH_SIZE(SIZE1), PTLB_EN, STLB_EN)
		 STREAM_MATCH_CFG(DIR_WRITE)
		 STREAM_MATCH_SID_VALUE(0x8)
		 STREAM_MATCH_SID_MASK(0xF9F)>,
		<2 STREAM_CFG(PTLB_ID(0x2), STLB_ID(0x2), FETCH_SIZE(SIZE1), PTLB_EN, STLB_EN)
		 STREAM_MATCH_CFG(DIR_WRITE)
		 STREAM_MATCH_SID_VALUE(0x10)
		 STREAM_MATCH_SID_MASK(0xF9F)>,
		<3 STREAM_CFG(PTLB_ID(0x3), STLB_ID(0x3), FETCH_SIZE(SIZE1), PTLB_EN, STLB_EN)
		 STREAM_MATCH_CFG(DIR_WRITE)
		 STREAM_MATCH_SID_VALUE(0x18)
		 STREAM_MATCH_SID_MASK(0xF9F)>,
		<4 STREAM_CFG(PTLB_ID(0x4), STLB_ID(0x4), FETCH_SIZE(SIZE1), PTLB_EN, STLB_EN)
		 STREAM_MATCH_CFG(DIR_READ)
		 STREAM_MATCH_SID_VALUE(0x0)
		 STREAM_MATCH_SID_MASK(0xF81)>,
		<5 STREAM_CFG(PTLB_ID(0x5), STLB_ID(0x5), FETCH_SIZE(SIZE1), PTLB_EN, STLB_EN)
		 STREAM_MATCH_CFG(DIR_READ)
		 STREAM_MATCH_SID_VALUE(0x1)
		 STREAM_MATCH_SID_MASK(0xF81)>,
		<6 STREAM_CFG(PTLB_ID(0x6), STLB_ID(0x6), FETCH_SIZE(SIZE1), PTLB_EN, STLB_EN)
		 STREAM_MATCH_CFG(DIR_WRITE)
		 STREAM_MATCH_SID_VALUE(0x80)
		 STREAM_MATCH_SID_MASK(0xF9F)>,
		<7 STREAM_CFG(PTLB_ID(0x7), STLB_ID(0x7), FETCH_SIZE(SIZE1), PTLB_EN, STLB_EN)
		 STREAM_MATCH_CFG(DIR_WRITE)
		 STREAM_MATCH_SID_VALUE(0x88)
		 STREAM_MATCH_SID_MASK(0xF9F)>,
		<8 STREAM_CFG(PTLB_ID(0x8), STLB_ID(0x8), FETCH_SIZE(SIZE1), PTLB_EN, STLB_EN)
		 STREAM_MATCH_CFG(DIR_WRITE)
		 STREAM_MATCH_SID_VALUE(0x90)
		 STREAM_MATCH_SID_MASK(0xF9F)>,
		<9 STREAM_CFG(PTLB_ID(0x9), STLB_ID(0x9), FETCH_SIZE(SIZE1), PTLB_EN, STLB_EN)
		 STREAM_MATCH_CFG(DIR_WRITE)
		 STREAM_MATCH_SID_VALUE(0x98)
		 STREAM_MATCH_SID_MASK(0xF9F)>,
		<10 STREAM_CFG(PTLB_ID(0x16), STLB_ID(0xA), FETCH_SIZE(SIZE1), PTLB_DIS, STLB_EN)
		 STREAM_MATCH_CFG(DIR_READ)
		 STREAM_MATCH_SID_VALUE(0x80)
		 STREAM_MATCH_SID_MASK(0xF81)>,
		<11 STREAM_CFG(PTLB_ID(0xA), STLB_ID(0xB), FETCH_SIZE(SIZE1), PTLB_EN, STLB_EN)
		 STREAM_MATCH_CFG(DIR_WRITE)
		 STREAM_MATCH_SID_VALUE(0x100)
		 STREAM_MATCH_SID_MASK(0xF9F)>,
		<12 STREAM_CFG(PTLB_ID(0xB), STLB_ID(0xC), FETCH_SIZE(SIZE1), PTLB_EN, STLB_EN)
		 STREAM_MATCH_CFG(DIR_WRITE)
		 STREAM_MATCH_SID_VALUE(0x101)
		 STREAM_MATCH_SID_MASK(0xF9F)>,
		<13 STREAM_CFG(PTLB_ID(0xC), STLB_ID(0xD), FETCH_SIZE(SIZE1), PTLB_EN, STLB_EN)
		 STREAM_MATCH_CFG(DIR_WRITE)
		 STREAM_MATCH_SID_VALUE(0x108)
		 STREAM_MATCH_SID_MASK(0xF9F)>,
		<14 STREAM_CFG(PTLB_ID(0xD), STLB_ID(0xE), FETCH_SIZE(SIZE1), PTLB_EN, STLB_EN)
		 STREAM_MATCH_CFG(DIR_WRITE)
		 STREAM_MATCH_SID_VALUE(0x109)
		 STREAM_MATCH_SID_MASK(0xF9F)>,
		<15 STREAM_CFG(PTLB_ID(0xE), STLB_ID(0xF), FETCH_SIZE(SIZE1), PTLB_EN, STLB_EN)
		 STREAM_MATCH_CFG(DIR_WRITE)
		 STREAM_MATCH_SID_VALUE(0x110)
		 STREAM_MATCH_SID_MASK(0xF9F)>,
		<16 STREAM_CFG(PTLB_ID(0xF), STLB_ID(0x10), FETCH_SIZE(SIZE1), PTLB_EN, STLB_EN)
		 STREAM_MATCH_CFG(DIR_WRITE)
		 STREAM_MATCH_SID_VALUE(0x111)
		 STREAM_MATCH_SID_MASK(0xF9F)>,
		<17 STREAM_CFG(PTLB_ID(0x10), STLB_ID(0x11), FETCH_SIZE(SIZE1), PTLB_EN, STLB_EN)
		 STREAM_MATCH_CFG(DIR_WRITE)
		 STREAM_MATCH_SID_VALUE(0x118)
		 STREAM_MATCH_SID_MASK(0xF9F)>,
		<18 STREAM_CFG(PTLB_ID(0x11), STLB_ID(0x12), FETCH_SIZE(SIZE1), PTLB_EN, STLB_EN)
		 STREAM_MATCH_CFG(DIR_WRITE)
		 STREAM_MATCH_SID_VALUE(0x119)
		 STREAM_MATCH_SID_MASK(0xF9F)>,
		<19 STREAM_CFG(PTLB_ID(0x17), STLB_ID(0x13), FETCH_SIZE(SIZE1), PTLB_DIS, STLB_EN)
		 STREAM_MATCH_CFG(DIR_READ)
		 STREAM_MATCH_SID_VALUE(0x100)
		 STREAM_MATCH_SID_MASK(0xF81)>,
		<20 STREAM_CFG(PTLB_ID(0x12), STLB_ID(0x14), FETCH_SIZE(SIZE1), PTLB_EN, STLB_EN)
		 STREAM_MATCH_CFG(DIR_WRITE)
		 STREAM_MATCH_SID_VALUE(0x180)
		 STREAM_MATCH_SID_MASK(0xF9F)>,
		<21 STREAM_CFG(PTLB_ID(0x13), STLB_ID(0x15), FETCH_SIZE(SIZE1), PTLB_EN, STLB_EN)
		 STREAM_MATCH_CFG(DIR_WRITE)
		 STREAM_MATCH_SID_VALUE(0x188)
		 STREAM_MATCH_SID_MASK(0xF9F)>,
		<22 STREAM_CFG(PTLB_ID(0x14), STLB_ID(0x16), FETCH_SIZE(SIZE1), PTLB_EN, STLB_EN)
		 STREAM_MATCH_CFG(DIR_WRITE)
		 STREAM_MATCH_SID_VALUE(0x190)
		 STREAM_MATCH_SID_MASK(0xF9F)>,
		<23 STREAM_CFG(PTLB_ID(0x15), STLB_ID(0x17), FETCH_SIZE(SIZE1), PTLB_EN, STLB_EN)
		 STREAM_MATCH_CFG(DIR_WRITE)
		 STREAM_MATCH_SID_VALUE(0x198)
		 STREAM_MATCH_SID_MASK(0xF9F)>,
		<24 STREAM_CFG(PTLB_ID(0x1C), STLB_ID(0x80), FETCH_SIZE(SIZE1), PTLB_DIS, STLB_DIS)
		 STREAM_MATCH_CFG(DIR_WRITE)
		 STREAM_MATCH_SID_VALUE(0x200)
		 STREAM_MATCH_SID_MASK(0xF81)>,
		<25 STREAM_CFG(PTLB_ID(0x18), STLB_ID(0x7A), FETCH_SIZE(SIZE1), PTLB_DIS, STLB_DIS)
		 STREAM_MATCH_CFG(DIR_WRITE)
		 STREAM_MATCH_SID_VALUE(0x280)
		 STREAM_MATCH_SID_MASK(0xF81)>,
		<26 STREAM_CFG(PTLB_ID(0x19), STLB_ID(0x7B), FETCH_SIZE(SIZE1), PTLB_DIS, STLB_DIS)
		 STREAM_MATCH_CFG(DIR_WRITE)
		 STREAM_MATCH_SID_VALUE(0x300)
		 STREAM_MATCH_SID_MASK(0xF81)>,
		<27 STREAM_CFG(PTLB_ID(0x1A), STLB_ID(0x7C), FETCH_SIZE(SIZE1), PTLB_DIS, STLB_DIS)
		 STREAM_MATCH_CFG(DIR_WRITE)
		 STREAM_MATCH_SID_VALUE(0x380)
		 STREAM_MATCH_SID_MASK(0xF81)>,
		<28 STREAM_CFG(PTLB_ID(0x1B), STLB_ID(0x7D), FETCH_SIZE(SIZE1), PTLB_DIS, STLB_DIS)
		 STREAM_MATCH_CFG(DIR_WRITE)
		 STREAM_MATCH_SID_VALUE(0x400)
		 STREAM_MATCH_SID_MASK(0xF81)>;
		pmmu1,default_stream =
		<STREAM_CFG(PTLB_ID(0x0), STLB_ID(0x18), FETCH_SIZE(SIZE1), PTLB_DIS, STLB_EN)>;
		pmmu1,stream_property =
		<1 STREAM_CFG(PTLB_ID(0x1), STLB_ID(0x19), FETCH_SIZE(SIZE1), PTLB_DIS, STLB_EN)
		 STREAM_MATCH_CFG(DIR_WRITE)
		 STREAM_MATCH_SID_VALUE(0x8)
		 STREAM_MATCH_SID_MASK(0xF9F)>,
		<2 STREAM_CFG(PTLB_ID(0x2), STLB_ID(0x1A), FETCH_SIZE(SIZE1), PTLB_DIS, STLB_EN)
		 STREAM_MATCH_CFG(DIR_WRITE)
		 STREAM_MATCH_SID_VALUE(0x10)
		 STREAM_MATCH_SID_MASK(0xF9F)>,
		<3 STREAM_CFG(PTLB_ID(0x3), STLB_ID(0x1B), FETCH_SIZE(SIZE1), PTLB_DIS, STLB_EN)
		 STREAM_MATCH_CFG(DIR_WRITE)
		 STREAM_MATCH_SID_VALUE(0x18)
		 STREAM_MATCH_SID_MASK(0xF9F)>,
		<4 STREAM_CFG(PTLB_ID(0x4), STLB_ID(0x1C), FETCH_SIZE(SIZE1), PTLB_DIS, STLB_EN)
		 STREAM_MATCH_CFG(DIR_WRITE)
		 STREAM_MATCH_SID_VALUE(0x2)
		 STREAM_MATCH_SID_MASK(0xF9F)>,
		<5 STREAM_CFG(PTLB_ID(0x5), STLB_ID(0x1D), FETCH_SIZE(SIZE1), PTLB_DIS, STLB_EN)
		 STREAM_MATCH_CFG(DIR_WRITE)
		 STREAM_MATCH_SID_VALUE(0xA)
		 STREAM_MATCH_SID_MASK(0xF9F)>,
		<6 STREAM_CFG(PTLB_ID(0x6), STLB_ID(0x1E), FETCH_SIZE(SIZE1), PTLB_DIS, STLB_EN)
		 STREAM_MATCH_CFG(DIR_WRITE)
		 STREAM_MATCH_SID_VALUE(0x12)
		 STREAM_MATCH_SID_MASK(0xF9F)>,
		<7 STREAM_CFG(PTLB_ID(0x7), STLB_ID(0x1F), FETCH_SIZE(SIZE1), PTLB_DIS, STLB_EN)
		 STREAM_MATCH_CFG(DIR_WRITE)
		 STREAM_MATCH_SID_VALUE(0x1A)
		 STREAM_MATCH_SID_MASK(0xF9F)>,
		<8 STREAM_CFG(PTLB_ID(0x8), STLB_ID(0x20), FETCH_SIZE(SIZE1), PTLB_EN, STLB_EN)
		 STREAM_MATCH_CFG(DIR_READ)
		 STREAM_MATCH_SID_VALUE(0x0)
		 STREAM_MATCH_SID_MASK(0xF81)>,
		<9 STREAM_CFG(PTLB_ID(0x9), STLB_ID(0x21), FETCH_SIZE(SIZE1), PTLB_EN, STLB_EN)
		 STREAM_MATCH_CFG(DIR_READ)
		 STREAM_MATCH_SID_VALUE(0x1)
		 STREAM_MATCH_SID_MASK(0xF81)>,
		<10 STREAM_CFG(PTLB_ID(0xA), STLB_ID(0x22), FETCH_SIZE(SIZE1), PTLB_DIS, STLB_EN)
		 STREAM_MATCH_CFG(DIR_WRITE)
		 STREAM_MATCH_SID_VALUE(0x80)
		 STREAM_MATCH_SID_MASK(0xF9F)>,
		<11 STREAM_CFG(PTLB_ID(0xB), STLB_ID(0x23), FETCH_SIZE(SIZE1), PTLB_DIS, STLB_EN)
		 STREAM_MATCH_CFG(DIR_WRITE)
		 STREAM_MATCH_SID_VALUE(0x88)
		 STREAM_MATCH_SID_MASK(0xF9F)>,
		<12 STREAM_CFG(PTLB_ID(0xC), STLB_ID(0x24), FETCH_SIZE(SIZE1), PTLB_DIS, STLB_EN)
		 STREAM_MATCH_CFG(DIR_WRITE)
		 STREAM_MATCH_SID_VALUE(0x90)
		 STREAM_MATCH_SID_MASK(0xF9F)>,
		<13 STREAM_CFG(PTLB_ID(0xD), STLB_ID(0x25), FETCH_SIZE(SIZE1), PTLB_DIS, STLB_EN)
		 STREAM_MATCH_CFG(DIR_WRITE)
		 STREAM_MATCH_SID_VALUE(0x98)
		 STREAM_MATCH_SID_MASK(0xF9F)>,
		<14 STREAM_CFG(PTLB_ID(0xE), STLB_ID(0x26), FETCH_SIZE(SIZE1), PTLB_DIS, STLB_EN)
		 STREAM_MATCH_CFG(DIR_WRITE)
		 STREAM_MATCH_SID_VALUE(0x82)
		 STREAM_MATCH_SID_MASK(0xF9F)>,
		<15 STREAM_CFG(PTLB_ID(0xF), STLB_ID(0x27), FETCH_SIZE(SIZE1), PTLB_DIS, STLB_EN)
		 STREAM_MATCH_CFG(DIR_WRITE)
		 STREAM_MATCH_SID_VALUE(0x8A)
		 STREAM_MATCH_SID_MASK(0xF9F)>,
		<16 STREAM_CFG(PTLB_ID(0x10), STLB_ID(0x28), FETCH_SIZE(SIZE1), PTLB_DIS, STLB_EN)
		 STREAM_MATCH_CFG(DIR_WRITE)
		 STREAM_MATCH_SID_VALUE(0x92)
		 STREAM_MATCH_SID_MASK(0xF9F)>,
		<17 STREAM_CFG(PTLB_ID(0x11), STLB_ID(0x29), FETCH_SIZE(SIZE1), PTLB_DIS, STLB_EN)
		 STREAM_MATCH_CFG(DIR_WRITE)
		 STREAM_MATCH_SID_VALUE(0x9A)
		 STREAM_MATCH_SID_MASK(0xF9F)>,
		<18 STREAM_CFG(PTLB_ID(0x62), STLB_ID(0x7E), FETCH_SIZE(SIZE1), PTLB_DIS, STLB_EN)
		 STREAM_MATCH_CFG(DIR_READ)
		 STREAM_MATCH_SID_VALUE(0x80)
		 STREAM_MATCH_SID_MASK(0xF81)>,
		<19 STREAM_CFG(PTLB_ID(0x12), STLB_ID(0x2A), FETCH_SIZE(SIZE1), PTLB_DIS, STLB_EN)
		 STREAM_MATCH_CFG(DIR_WRITE)
		 STREAM_MATCH_SID_VALUE(0x100)
		 STREAM_MATCH_SID_MASK(0xF9F)>,
		<20 STREAM_CFG(PTLB_ID(0x13), STLB_ID(0x2B), FETCH_SIZE(SIZE1), PTLB_DIS, STLB_EN)
		 STREAM_MATCH_CFG(DIR_WRITE)
		 STREAM_MATCH_SID_VALUE(0x101)
		 STREAM_MATCH_SID_MASK(0xF9F)>,
		<21 STREAM_CFG(PTLB_ID(0x14), STLB_ID(0x2C), FETCH_SIZE(SIZE1), PTLB_DIS, STLB_EN)
		 STREAM_MATCH_CFG(DIR_WRITE)
		 STREAM_MATCH_SID_VALUE(0x108)
		 STREAM_MATCH_SID_MASK(0xF9F)>,
		<22 STREAM_CFG(PTLB_ID(0x15), STLB_ID(0x2D), FETCH_SIZE(SIZE1), PTLB_DIS, STLB_EN)
		 STREAM_MATCH_CFG(DIR_WRITE)
		 STREAM_MATCH_SID_VALUE(0x109)
		 STREAM_MATCH_SID_MASK(0xF9F)>,
		<23 STREAM_CFG(PTLB_ID(0x16), STLB_ID(0x2E), FETCH_SIZE(SIZE1), PTLB_DIS, STLB_EN)
		 STREAM_MATCH_CFG(DIR_WRITE)
		 STREAM_MATCH_SID_VALUE(0x110)
		 STREAM_MATCH_SID_MASK(0xF9F)>,
		<24 STREAM_CFG(PTLB_ID(0x17), STLB_ID(0x2F), FETCH_SIZE(SIZE1), PTLB_DIS, STLB_EN)
		 STREAM_MATCH_CFG(DIR_WRITE)
		 STREAM_MATCH_SID_VALUE(0x111)
		 STREAM_MATCH_SID_MASK(0xF9F)>,
		<25 STREAM_CFG(PTLB_ID(0x18), STLB_ID(0x30), FETCH_SIZE(SIZE1), PTLB_DIS, STLB_EN)
		 STREAM_MATCH_CFG(DIR_WRITE)
		 STREAM_MATCH_SID_VALUE(0x118)
		 STREAM_MATCH_SID_MASK(0xF9F)>,
		<26 STREAM_CFG(PTLB_ID(0x19), STLB_ID(0x31), FETCH_SIZE(SIZE1), PTLB_DIS, STLB_EN)
		 STREAM_MATCH_CFG(DIR_WRITE)
		 STREAM_MATCH_SID_VALUE(0x119)
		 STREAM_MATCH_SID_MASK(0xF9F)>,
		<27 STREAM_CFG(PTLB_ID(0x63), STLB_ID(0x7F), FETCH_SIZE(SIZE1), PTLB_DIS, STLB_EN)
		 STREAM_MATCH_CFG(DIR_READ)
		 STREAM_MATCH_SID_VALUE(0x100)
		 STREAM_MATCH_SID_MASK(0xF81)>,
		<28 STREAM_CFG(PTLB_ID(0x1A), STLB_ID(0x32), FETCH_SIZE(SIZE1), PTLB_DIS, STLB_EN)
		 STREAM_MATCH_CFG(DIR_WRITE)
		 STREAM_MATCH_SID_VALUE(0x180)
		 STREAM_MATCH_SID_MASK(0xF9F)>,
		<29 STREAM_CFG(PTLB_ID(0x1B), STLB_ID(0x33), FETCH_SIZE(SIZE1), PTLB_DIS, STLB_EN)
		 STREAM_MATCH_CFG(DIR_WRITE)
		 STREAM_MATCH_SID_VALUE(0x181)
		 STREAM_MATCH_SID_MASK(0xF9F)>,
		<30 STREAM_CFG(PTLB_ID(0x1C), STLB_ID(0x34), FETCH_SIZE(SIZE1), PTLB_DIS, STLB_EN)
		 STREAM_MATCH_CFG(DIR_WRITE)
		 STREAM_MATCH_SID_VALUE(0x188)
		 STREAM_MATCH_SID_MASK(0xF9F)>,
		<31 STREAM_CFG(PTLB_ID(0x1D), STLB_ID(0x35), FETCH_SIZE(SIZE1), PTLB_DIS, STLB_EN)
		 STREAM_MATCH_CFG(DIR_WRITE)
		 STREAM_MATCH_SID_VALUE(0x189)
		 STREAM_MATCH_SID_MASK(0xF9F)>,
		<32 STREAM_CFG(PTLB_ID(0x1E), STLB_ID(0x36), FETCH_SIZE(SIZE1), PTLB_DIS, STLB_EN)
		 STREAM_MATCH_CFG(DIR_WRITE)
		 STREAM_MATCH_SID_VALUE(0x190)
		 STREAM_MATCH_SID_MASK(0xF9F)>,
		<33 STREAM_CFG(PTLB_ID(0x1F), STLB_ID(0x37), FETCH_SIZE(SIZE1), PTLB_DIS, STLB_EN)
		 STREAM_MATCH_CFG(DIR_WRITE)
		 STREAM_MATCH_SID_VALUE(0x191)
		 STREAM_MATCH_SID_MASK(0xF9F)>,
		<34 STREAM_CFG(PTLB_ID(0x20), STLB_ID(0x38), FETCH_SIZE(SIZE1), PTLB_DIS, STLB_EN)
		 STREAM_MATCH_CFG(DIR_WRITE)
		 STREAM_MATCH_SID_VALUE(0x198)
		 STREAM_MATCH_SID_MASK(0xF9F)>,
		<35 STREAM_CFG(PTLB_ID(0x21), STLB_ID(0x39), FETCH_SIZE(SIZE1), PTLB_DIS, STLB_EN)
		 STREAM_MATCH_CFG(DIR_WRITE)
		 STREAM_MATCH_SID_VALUE(0x199)
		 STREAM_MATCH_SID_MASK(0xF9F)>,
		<36 STREAM_CFG(PTLB_ID(0x22), STLB_ID(0x3A), FETCH_SIZE(SIZE1), PTLB_DIS, STLB_EN)
		 STREAM_MATCH_CFG(DIR_WRITE)
		 STREAM_MATCH_SID_VALUE(0x200)
		 STREAM_MATCH_SID_MASK(0xF9F)>,
		<37 STREAM_CFG(PTLB_ID(0x23), STLB_ID(0x3B), FETCH_SIZE(SIZE1), PTLB_DIS, STLB_EN)
		 STREAM_MATCH_CFG(DIR_WRITE)
		 STREAM_MATCH_SID_VALUE(0x201)
		 STREAM_MATCH_SID_MASK(0xF9F)>,
		<38 STREAM_CFG(PTLB_ID(0x24), STLB_ID(0x3C), FETCH_SIZE(SIZE1), PTLB_DIS, STLB_EN)
		 STREAM_MATCH_CFG(DIR_WRITE)
		 STREAM_MATCH_SID_VALUE(0x208)
		 STREAM_MATCH_SID_MASK(0xF9F)>,
		<39 STREAM_CFG(PTLB_ID(0x25), STLB_ID(0x3D), FETCH_SIZE(SIZE1), PTLB_DIS, STLB_EN)
		 STREAM_MATCH_CFG(DIR_WRITE)
		 STREAM_MATCH_SID_VALUE(0x209)
		 STREAM_MATCH_SID_MASK(0xF9F)>,
		<40 STREAM_CFG(PTLB_ID(0x26), STLB_ID(0x3E), FETCH_SIZE(SIZE1), PTLB_DIS, STLB_EN)
		 STREAM_MATCH_CFG(DIR_WRITE)
		 STREAM_MATCH_SID_VALUE(0x210)
		 STREAM_MATCH_SID_MASK(0xF9F)>,
		<41 STREAM_CFG(PTLB_ID(0x27), STLB_ID(0x3F), FETCH_SIZE(SIZE1), PTLB_DIS, STLB_EN)
		 STREAM_MATCH_CFG(DIR_WRITE)
		 STREAM_MATCH_SID_VALUE(0x211)
		 STREAM_MATCH_SID_MASK(0xF9F)>,
		<42 STREAM_CFG(PTLB_ID(0x28), STLB_ID(0x40), FETCH_SIZE(SIZE1), PTLB_DIS, STLB_EN)
		 STREAM_MATCH_CFG(DIR_WRITE)
		 STREAM_MATCH_SID_VALUE(0x218)
		 STREAM_MATCH_SID_MASK(0xF9F)>,
		<43 STREAM_CFG(PTLB_ID(0x29), STLB_ID(0x41), FETCH_SIZE(SIZE1), PTLB_DIS, STLB_EN)
		 STREAM_MATCH_CFG(DIR_WRITE)
		 STREAM_MATCH_SID_VALUE(0x219)
		 STREAM_MATCH_SID_MASK(0xF9F)>,
		<44 STREAM_CFG(PTLB_ID(0x2A), STLB_ID(0x42), FETCH_SIZE(SIZE1), PTLB_DIS, STLB_EN)
		 STREAM_MATCH_CFG(DIR_WRITE)
		 STREAM_MATCH_SID_VALUE(0x280)
		 STREAM_MATCH_SID_MASK(0xF9F)>,
		<45 STREAM_CFG(PTLB_ID(0x2B), STLB_ID(0x43), FETCH_SIZE(SIZE1), PTLB_DIS, STLB_EN)
		 STREAM_MATCH_CFG(DIR_WRITE)
		 STREAM_MATCH_SID_VALUE(0x281)
		 STREAM_MATCH_SID_MASK(0xF9F)>,
		<46 STREAM_CFG(PTLB_ID(0x2C), STLB_ID(0x44), FETCH_SIZE(SIZE1), PTLB_DIS, STLB_EN)
		 STREAM_MATCH_CFG(DIR_WRITE)
		 STREAM_MATCH_SID_VALUE(0x288)
		 STREAM_MATCH_SID_MASK(0xF9F)>,
		<47 STREAM_CFG(PTLB_ID(0x2D), STLB_ID(0x45), FETCH_SIZE(SIZE1), PTLB_DIS, STLB_EN)
		 STREAM_MATCH_CFG(DIR_WRITE)
		 STREAM_MATCH_SID_VALUE(0x289)
		 STREAM_MATCH_SID_MASK(0xF9F)>,
		<48 STREAM_CFG(PTLB_ID(0x2E), STLB_ID(0x46), FETCH_SIZE(SIZE1), PTLB_DIS, STLB_EN)
		 STREAM_MATCH_CFG(DIR_WRITE)
		 STREAM_MATCH_SID_VALUE(0x290)
		 STREAM_MATCH_SID_MASK(0xF9F)>,
		<49 STREAM_CFG(PTLB_ID(0x2F), STLB_ID(0x47), FETCH_SIZE(SIZE1), PTLB_DIS, STLB_EN)
		 STREAM_MATCH_CFG(DIR_WRITE)
		 STREAM_MATCH_SID_VALUE(0x291)
		 STREAM_MATCH_SID_MASK(0xF9F)>,
		<50 STREAM_CFG(PTLB_ID(0x30), STLB_ID(0x48), FETCH_SIZE(SIZE1), PTLB_DIS, STLB_EN)
		 STREAM_MATCH_CFG(DIR_WRITE)
		 STREAM_MATCH_SID_VALUE(0x298)
		 STREAM_MATCH_SID_MASK(0xF9F)>,
		<51 STREAM_CFG(PTLB_ID(0x31), STLB_ID(0x49), FETCH_SIZE(SIZE1), PTLB_DIS, STLB_EN)
		 STREAM_MATCH_CFG(DIR_WRITE)
		 STREAM_MATCH_SID_VALUE(0x299)
		 STREAM_MATCH_SID_MASK(0xF9F)>,
		<52 STREAM_CFG(PTLB_ID(0x32), STLB_ID(0x4A), FETCH_SIZE(SIZE1), PTLB_DIS, STLB_EN)
		 STREAM_MATCH_CFG(DIR_WRITE)
		 STREAM_MATCH_SID_VALUE(0x300)
		 STREAM_MATCH_SID_MASK(0xF9F)>,
		<53 STREAM_CFG(PTLB_ID(0x33), STLB_ID(0x4B), FETCH_SIZE(SIZE1), PTLB_DIS, STLB_EN)
		 STREAM_MATCH_CFG(DIR_WRITE)
		 STREAM_MATCH_SID_VALUE(0x301)
		 STREAM_MATCH_SID_MASK(0xF9F)>,
		<54 STREAM_CFG(PTLB_ID(0x34), STLB_ID(0x4C), FETCH_SIZE(SIZE1), PTLB_DIS, STLB_EN)
		 STREAM_MATCH_CFG(DIR_WRITE)
		 STREAM_MATCH_SID_VALUE(0x308)
		 STREAM_MATCH_SID_MASK(0xF9F)>,
		<55 STREAM_CFG(PTLB_ID(0x35), STLB_ID(0x4D), FETCH_SIZE(SIZE1), PTLB_DIS, STLB_EN)
		 STREAM_MATCH_CFG(DIR_WRITE)
		 STREAM_MATCH_SID_VALUE(0x309)
		 STREAM_MATCH_SID_MASK(0xF9F)>,
		<56 STREAM_CFG(PTLB_ID(0x36), STLB_ID(0x4E), FETCH_SIZE(SIZE1), PTLB_DIS, STLB_EN)
		 STREAM_MATCH_CFG(DIR_WRITE)
		 STREAM_MATCH_SID_VALUE(0x310)
		 STREAM_MATCH_SID_MASK(0xF9F)>,
		<57 STREAM_CFG(PTLB_ID(0x37), STLB_ID(0x4F), FETCH_SIZE(SIZE1), PTLB_DIS, STLB_EN)
		 STREAM_MATCH_CFG(DIR_WRITE)
		 STREAM_MATCH_SID_VALUE(0x311)
		 STREAM_MATCH_SID_MASK(0xF9F)>,
		<58 STREAM_CFG(PTLB_ID(0x38), STLB_ID(0x50), FETCH_SIZE(SIZE1), PTLB_DIS, STLB_EN)
		 STREAM_MATCH_CFG(DIR_WRITE)
		 STREAM_MATCH_SID_VALUE(0x318)
		 STREAM_MATCH_SID_MASK(0xF9F)>,
		<59 STREAM_CFG(PTLB_ID(0x39), STLB_ID(0x51), FETCH_SIZE(SIZE1), PTLB_DIS, STLB_EN)
		 STREAM_MATCH_CFG(DIR_WRITE)
		 STREAM_MATCH_SID_VALUE(0x319)
		 STREAM_MATCH_SID_MASK(0xF9F)>,
		<60 STREAM_CFG(PTLB_ID(0x3A), STLB_ID(0x52), FETCH_SIZE(SIZE1), PTLB_DIS, STLB_EN)
		 STREAM_MATCH_CFG(DIR_WRITE)
		 STREAM_MATCH_SID_VALUE(0x380)
		 STREAM_MATCH_SID_MASK(0xF9F)>,
		<61 STREAM_CFG(PTLB_ID(0x3B), STLB_ID(0x53), FETCH_SIZE(SIZE1), PTLB_DIS, STLB_EN)
		 STREAM_MATCH_CFG(DIR_WRITE)
		 STREAM_MATCH_SID_VALUE(0x381)
		 STREAM_MATCH_SID_MASK(0xF9F)>,
		<62 STREAM_CFG(PTLB_ID(0x3C), STLB_ID(0x54), FETCH_SIZE(SIZE1), PTLB_DIS, STLB_EN)
		 STREAM_MATCH_CFG(DIR_WRITE)
		 STREAM_MATCH_SID_VALUE(0x388)
		 STREAM_MATCH_SID_MASK(0xF9F)>,
		<63 STREAM_CFG(PTLB_ID(0x3D), STLB_ID(0x55), FETCH_SIZE(SIZE1), PTLB_DIS, STLB_EN)
		 STREAM_MATCH_CFG(DIR_WRITE)
		 STREAM_MATCH_SID_VALUE(0x389)
		 STREAM_MATCH_SID_MASK(0xF9F)>,
		<64 STREAM_CFG(PTLB_ID(0x3E), STLB_ID(0x56), FETCH_SIZE(SIZE1), PTLB_DIS, STLB_EN)
		 STREAM_MATCH_CFG(DIR_WRITE)
		 STREAM_MATCH_SID_VALUE(0x390)
		 STREAM_MATCH_SID_MASK(0xF9F)>,
		<65 STREAM_CFG(PTLB_ID(0x3F), STLB_ID(0x57), FETCH_SIZE(SIZE1), PTLB_DIS, STLB_EN)
		 STREAM_MATCH_CFG(DIR_WRITE)
		 STREAM_MATCH_SID_VALUE(0x391)
		 STREAM_MATCH_SID_MASK(0xF9F)>,
		<66 STREAM_CFG(PTLB_ID(0x40), STLB_ID(0x58), FETCH_SIZE(SIZE1), PTLB_DIS, STLB_EN)
		 STREAM_MATCH_CFG(DIR_WRITE)
		 STREAM_MATCH_SID_VALUE(0x398)
		 STREAM_MATCH_SID_MASK(0xF9F)>,
		<67 STREAM_CFG(PTLB_ID(0x41), STLB_ID(0x59), FETCH_SIZE(SIZE1), PTLB_DIS, STLB_EN)
		 STREAM_MATCH_CFG(DIR_WRITE)
		 STREAM_MATCH_SID_VALUE(0x399)
		 STREAM_MATCH_SID_MASK(0xF9F)>,
		<68 STREAM_CFG(PTLB_ID(0x42), STLB_ID(0x5A), FETCH_SIZE(SIZE1), PTLB_DIS, STLB_EN)
		 STREAM_MATCH_CFG(DIR_WRITE)
		 STREAM_MATCH_SID_VALUE(0x400)
		 STREAM_MATCH_SID_MASK(0xF9F)>,
		<69 STREAM_CFG(PTLB_ID(0x43), STLB_ID(0x5B), FETCH_SIZE(SIZE1), PTLB_DIS, STLB_EN)
		 STREAM_MATCH_CFG(DIR_WRITE)
		 STREAM_MATCH_SID_VALUE(0x408)
		 STREAM_MATCH_SID_MASK(0xF9F)>,
		<70 STREAM_CFG(PTLB_ID(0x44), STLB_ID(0x5C), FETCH_SIZE(SIZE1), PTLB_DIS, STLB_EN)
		 STREAM_MATCH_CFG(DIR_WRITE)
		 STREAM_MATCH_SID_VALUE(0x410)
		 STREAM_MATCH_SID_MASK(0xF9F)>,
		<71 STREAM_CFG(PTLB_ID(0x45), STLB_ID(0x5D), FETCH_SIZE(SIZE1), PTLB_DIS, STLB_EN)
		 STREAM_MATCH_CFG(DIR_WRITE)
		 STREAM_MATCH_SID_VALUE(0x418)
		 STREAM_MATCH_SID_MASK(0xF9F)>,
		<72 STREAM_CFG(PTLB_ID(0x46), STLB_ID(0x5E), FETCH_SIZE(SIZE1), PTLB_DIS, STLB_EN)
		 STREAM_MATCH_CFG(DIR_WRITE)
		 STREAM_MATCH_SID_VALUE(0x480)
		 STREAM_MATCH_SID_MASK(0xF9F)>,
		<73 STREAM_CFG(PTLB_ID(0x47), STLB_ID(0x5F), FETCH_SIZE(SIZE1), PTLB_DIS, STLB_EN)
		 STREAM_MATCH_CFG(DIR_WRITE)
		 STREAM_MATCH_SID_VALUE(0x488)
		 STREAM_MATCH_SID_MASK(0xF9F)>,
		<74 STREAM_CFG(PTLB_ID(0x48), STLB_ID(0x60), FETCH_SIZE(SIZE1), PTLB_DIS, STLB_EN)
		 STREAM_MATCH_CFG(DIR_WRITE)
		 STREAM_MATCH_SID_VALUE(0x490)
		 STREAM_MATCH_SID_MASK(0xF9F)>,
		<75 STREAM_CFG(PTLB_ID(0x49), STLB_ID(0x61), FETCH_SIZE(SIZE1), PTLB_DIS, STLB_EN)
		 STREAM_MATCH_CFG(DIR_WRITE)
		 STREAM_MATCH_SID_VALUE(0x498)
		 STREAM_MATCH_SID_MASK(0xF9F)>,
		<76 STREAM_CFG(PTLB_ID(0x4A), STLB_ID(0x62), FETCH_SIZE(SIZE1), PTLB_DIS, STLB_EN)
		 STREAM_MATCH_CFG(DIR_WRITE)
		 STREAM_MATCH_SID_VALUE(0x500)
		 STREAM_MATCH_SID_MASK(0xF9F)>,
		<77 STREAM_CFG(PTLB_ID(0x4B), STLB_ID(0x63), FETCH_SIZE(SIZE1), PTLB_DIS, STLB_EN)
		 STREAM_MATCH_CFG(DIR_WRITE)
		 STREAM_MATCH_SID_VALUE(0x508)
		 STREAM_MATCH_SID_MASK(0xF9F)>,
		<78 STREAM_CFG(PTLB_ID(0x4C), STLB_ID(0x64), FETCH_SIZE(SIZE1), PTLB_DIS, STLB_EN)
		 STREAM_MATCH_CFG(DIR_WRITE)
		 STREAM_MATCH_SID_VALUE(0x510)
		 STREAM_MATCH_SID_MASK(0xF9F)>,
		<79 STREAM_CFG(PTLB_ID(0x4D), STLB_ID(0x65), FETCH_SIZE(SIZE1), PTLB_DIS, STLB_EN)
		 STREAM_MATCH_CFG(DIR_WRITE)
		 STREAM_MATCH_SID_VALUE(0x518)
		 STREAM_MATCH_SID_MASK(0xF9F)>,
		<80 STREAM_CFG(PTLB_ID(0x4E), STLB_ID(0x66), FETCH_SIZE(SIZE1), PTLB_DIS, STLB_EN)
		 STREAM_MATCH_CFG(DIR_WRITE)
		 STREAM_MATCH_SID_VALUE(0x580)
		 STREAM_MATCH_SID_MASK(0xF9F)>,
		<81 STREAM_CFG(PTLB_ID(0x4F), STLB_ID(0x67), FETCH_SIZE(SIZE1), PTLB_DIS, STLB_EN)
		 STREAM_MATCH_CFG(DIR_WRITE)
		 STREAM_MATCH_SID_VALUE(0x588)
		 STREAM_MATCH_SID_MASK(0xF9F)>,
		<82 STREAM_CFG(PTLB_ID(0x50), STLB_ID(0x68), FETCH_SIZE(SIZE1), PTLB_DIS, STLB_EN)
		 STREAM_MATCH_CFG(DIR_WRITE)
		 STREAM_MATCH_SID_VALUE(0x590)
		 STREAM_MATCH_SID_MASK(0xF9F)>,
		<83 STREAM_CFG(PTLB_ID(0x51), STLB_ID(0x69), FETCH_SIZE(SIZE1), PTLB_DIS, STLB_EN)
		 STREAM_MATCH_CFG(DIR_WRITE)
		 STREAM_MATCH_SID_VALUE(0x598)
		 STREAM_MATCH_SID_MASK(0xF9F)>,
		<84 STREAM_CFG(PTLB_ID(0x52), STLB_ID(0x6A), FETCH_SIZE(SIZE1), PTLB_DIS, STLB_EN)
		 STREAM_MATCH_CFG(DIR_WRITE)
		 STREAM_MATCH_SID_VALUE(0x600)
		 STREAM_MATCH_SID_MASK(0xF9F)>,
		<85 STREAM_CFG(PTLB_ID(0x53), STLB_ID(0x6B), FETCH_SIZE(SIZE1), PTLB_DIS, STLB_EN)
		 STREAM_MATCH_CFG(DIR_WRITE)
		 STREAM_MATCH_SID_VALUE(0x608)
		 STREAM_MATCH_SID_MASK(0xF9F)>,
		<86 STREAM_CFG(PTLB_ID(0x54), STLB_ID(0x6C), FETCH_SIZE(SIZE1), PTLB_DIS, STLB_EN)
		 STREAM_MATCH_CFG(DIR_WRITE)
		 STREAM_MATCH_SID_VALUE(0x610)
		 STREAM_MATCH_SID_MASK(0xF9F)>,
		<87 STREAM_CFG(PTLB_ID(0x55), STLB_ID(0x6D), FETCH_SIZE(SIZE1), PTLB_DIS, STLB_EN)
		 STREAM_MATCH_CFG(DIR_WRITE)
		 STREAM_MATCH_SID_VALUE(0x618)
		 STREAM_MATCH_SID_MASK(0xF9F)>,
		<88 STREAM_CFG(PTLB_ID(0x56), STLB_ID(0x6E), FETCH_SIZE(SIZE1), PTLB_DIS, STLB_EN)
		 STREAM_MATCH_CFG(DIR_WRITE)
		 STREAM_MATCH_SID_VALUE(0x680)
		 STREAM_MATCH_SID_MASK(0xF9F)>,
		<89 STREAM_CFG(PTLB_ID(0x57), STLB_ID(0x6F), FETCH_SIZE(SIZE1), PTLB_DIS, STLB_EN)
		 STREAM_MATCH_CFG(DIR_WRITE)
		 STREAM_MATCH_SID_VALUE(0x688)
		 STREAM_MATCH_SID_MASK(0xF9F)>,
		<90 STREAM_CFG(PTLB_ID(0x58), STLB_ID(0x70), FETCH_SIZE(SIZE1), PTLB_DIS, STLB_EN)
		 STREAM_MATCH_CFG(DIR_WRITE)
		 STREAM_MATCH_SID_VALUE(0x690)
		 STREAM_MATCH_SID_MASK(0xF9F)>,
		<91 STREAM_CFG(PTLB_ID(0x59), STLB_ID(0x71), FETCH_SIZE(SIZE1), PTLB_DIS, STLB_EN)
		 STREAM_MATCH_CFG(DIR_WRITE)
		 STREAM_MATCH_SID_VALUE(0x698)
		 STREAM_MATCH_SID_MASK(0xF9F)>,
		<92 STREAM_CFG(PTLB_ID(0x5A), STLB_ID(0x72), FETCH_SIZE(SIZE1), PTLB_DIS, STLB_EN)
		 STREAM_MATCH_CFG(DIR_WRITE)
		 STREAM_MATCH_SID_VALUE(0x700)
		 STREAM_MATCH_SID_MASK(0xF9F)>,
		<93 STREAM_CFG(PTLB_ID(0x5B), STLB_ID(0x73), FETCH_SIZE(SIZE1), PTLB_DIS, STLB_EN)
		 STREAM_MATCH_CFG(DIR_WRITE)
		 STREAM_MATCH_SID_VALUE(0x708)
		 STREAM_MATCH_SID_MASK(0xF9F)>,
		<94 STREAM_CFG(PTLB_ID(0x5C), STLB_ID(0x74), FETCH_SIZE(SIZE1), PTLB_DIS, STLB_EN)
		 STREAM_MATCH_CFG(DIR_WRITE)
		 STREAM_MATCH_SID_VALUE(0x710)
		 STREAM_MATCH_SID_MASK(0xF9F)>,
		<95 STREAM_CFG(PTLB_ID(0x5D), STLB_ID(0x75), FETCH_SIZE(SIZE1), PTLB_DIS, STLB_EN)
		 STREAM_MATCH_CFG(DIR_WRITE)
		 STREAM_MATCH_SID_VALUE(0x718)
		 STREAM_MATCH_SID_MASK(0xF9F)>,
		<96 STREAM_CFG(PTLB_ID(0x5E), STLB_ID(0x76), FETCH_SIZE(SIZE1), PTLB_DIS, STLB_EN)
		 STREAM_MATCH_CFG(DIR_WRITE)
		 STREAM_MATCH_SID_VALUE(0x780)
		 STREAM_MATCH_SID_MASK(0xF9F)>,
		<97 STREAM_CFG(PTLB_ID(0x5F), STLB_ID(0x77), FETCH_SIZE(SIZE1), PTLB_DIS, STLB_EN)
		 STREAM_MATCH_CFG(DIR_WRITE)
		 STREAM_MATCH_SID_VALUE(0x788)
		 STREAM_MATCH_SID_MASK(0xF9F)>,
		<98 STREAM_CFG(PTLB_ID(0x60), STLB_ID(0x78), FETCH_SIZE(SIZE1), PTLB_DIS, STLB_EN)
		 STREAM_MATCH_CFG(DIR_WRITE)
		 STREAM_MATCH_SID_VALUE(0x790)
		 STREAM_MATCH_SID_MASK(0xF9F)>,
		<99 STREAM_CFG(PTLB_ID(0x61), STLB_ID(0x79), FETCH_SIZE(SIZE1), PTLB_DIS, STLB_EN)
		 STREAM_MATCH_CFG(DIR_WRITE)
		 STREAM_MATCH_SID_VALUE(0x798)
		 STREAM_MATCH_SID_MASK(0xF9F)>;
	};

	sysmmu_modem_s0_stream: sysmmu_modem_s0_stream {
		pmmu0,default_stream =
		<STREAM_CFG(PTLB_ID(0x0), STLB_ID(0x0), FETCH_SIZE(SIZE2), PTLB_DIS, STLB_EN)>;
		pmmu0,stream_property =
		<1 STREAM_CFG(PTLB_ID(0x1), STLB_ID(0x2), FETCH_SIZE(SIZE1), PTLB_DIS, STLB_EN)
		 STREAM_MATCH_CFG(DIR_RW)
		 STREAM_MATCH_SID_VALUE(0x10)
		 STREAM_MATCH_SID_MASK(0xF95)>,
		<2 STREAM_CFG(PTLB_ID(0x2), STLB_ID(0x1), FETCH_SIZE(SIZE2), PTLB_EN, STLB_EN)
		 STREAM_MATCH_CFG(DIR_READ)
		 STREAM_MATCH_SID_VALUE(0x4)
		 STREAM_MATCH_SID_MASK(0xF9F)>,
		<3 STREAM_CFG(PTLB_ID(0x3), STLB_ID(0x3), FETCH_SIZE(SIZE1), PTLB_DIS, STLB_EN)
		 STREAM_MATCH_CFG(DIR_RW)
		 STREAM_MATCH_SID_VALUE(0x14)
		 STREAM_MATCH_SID_MASK(0xF9F)>,
		<4 STREAM_CFG(PTLB_ID(0x4), STLB_ID(0x4), FETCH_SIZE(SIZE1), PTLB_DIS, STLB_EN)
		 STREAM_MATCH_CFG(DIR_RW)
		 STREAM_MATCH_SID_VALUE(0x6)
		 STREAM_MATCH_SID_MASK(0xF9F)>,
		<5 STREAM_CFG(PTLB_ID(0x5), STLB_ID(0x5), FETCH_SIZE(SIZE1), PTLB_DIS, STLB_EN)
		 STREAM_MATCH_CFG(DIR_RW)
		 STREAM_MATCH_SID_VALUE(0x1)
		 STREAM_MATCH_SID_MASK(0xF9F)>,
		<6 STREAM_CFG(PTLB_ID(0x5), STLB_ID(0x5), FETCH_SIZE(SIZE1), PTLB_DIS, STLB_EN)
		 STREAM_MATCH_CFG(DIR_RW)
		 STREAM_MATCH_SID_VALUE(0x3)
		 STREAM_MATCH_SID_MASK(0xF9F)>,
		<7 STREAM_CFG(PTLB_ID(0x5), STLB_ID(0x5), FETCH_SIZE(SIZE1), PTLB_DIS, STLB_EN)
		 STREAM_MATCH_CFG(DIR_RW)
		 STREAM_MATCH_SID_VALUE(0x5)
		 STREAM_MATCH_SID_MASK(0xF9F)>,
		<8 STREAM_CFG(PTLB_ID(0x5), STLB_ID(0x5), FETCH_SIZE(SIZE1), PTLB_DIS, STLB_EN)
		 STREAM_MATCH_CFG(DIR_RW)
		 STREAM_MATCH_SID_VALUE(0x9)
		 STREAM_MATCH_SID_MASK(0xF9F)>,
		<9 STREAM_CFG(PTLB_ID(0x6), STLB_ID(0x6), FETCH_SIZE(SIZE1), PTLB_DIS, STLB_DIS)
		 STREAM_MATCH_CFG(DIR_RW)
		 STREAM_MATCH_SID_VALUE(0x0)
		 STREAM_MATCH_SID_MASK(0xF9F)>;
	};

	sysmmu_mtnr_s0_stream: sysmmu_mtnr_s0_stream {
		pmmu0,default_stream =
		<STREAM_CFG(PTLB_ID(0x1), STLB_ID(0x11), FETCH_SIZE(SIZE1), PTLB_EN, STLB_EN)>;
		pmmu0,stream_property =
		<1 STREAM_CFG(PTLB_ID(0x2), STLB_ID(0x12), FETCH_SIZE(SIZE1), PTLB_EN, STLB_EN)
		 STREAM_MATCH_CFG(DIR_READ)
		 STREAM_MATCH_SID_VALUE(0x1)
		 STREAM_MATCH_SID_MASK(0xF81)>,
		<2 STREAM_CFG(PTLB_ID(0x3), STLB_ID(0x13), FETCH_SIZE(SIZE1), PTLB_DIS, STLB_EN)
		 STREAM_MATCH_CFG(DIR_WRITE)
		 STREAM_MATCH_SID_VALUE(0x0)
		 STREAM_MATCH_SID_MASK(0xF81)>,
		<3 STREAM_CFG(PTLB_ID(0x4), STLB_ID(0x14), FETCH_SIZE(SIZE1), PTLB_DIS, STLB_EN)
		 STREAM_MATCH_CFG(DIR_WRITE)
		 STREAM_MATCH_SID_VALUE(0x1)
		 STREAM_MATCH_SID_MASK(0xF81)>,
		<4 STREAM_CFG(PTLB_ID(0x5), STLB_ID(0x15), FETCH_SIZE(SIZE1), PTLB_EN, STLB_EN)
		 STREAM_MATCH_CFG(DIR_READ)
		 STREAM_MATCH_SID_VALUE(0x80)
		 STREAM_MATCH_SID_MASK(0xF81)>,
		<5 STREAM_CFG(PTLB_ID(0x6), STLB_ID(0x16), FETCH_SIZE(SIZE1), PTLB_EN, STLB_EN)
		 STREAM_MATCH_CFG(DIR_READ)
		 STREAM_MATCH_SID_VALUE(0x81)
		 STREAM_MATCH_SID_MASK(0xF81)>,
		<6 STREAM_CFG(PTLB_ID(0x7), STLB_ID(0x17), FETCH_SIZE(SIZE1), PTLB_EN, STLB_EN)
		 STREAM_MATCH_CFG(DIR_READ)
		 STREAM_MATCH_SID_VALUE(0x100)
		 STREAM_MATCH_SID_MASK(0xF81)>,
		<7 STREAM_CFG(PTLB_ID(0x8), STLB_ID(0x18), FETCH_SIZE(SIZE1), PTLB_EN, STLB_EN)
		 STREAM_MATCH_CFG(DIR_READ)
		 STREAM_MATCH_SID_VALUE(0x101)
		 STREAM_MATCH_SID_MASK(0xF81)>,
		<8 STREAM_CFG(PTLB_ID(0x9), STLB_ID(0xD), FETCH_SIZE(SIZE2), PTLB_EN, STLB_EN)
		 STREAM_MATCH_CFG(DIR_WRITE)
		 STREAM_MATCH_SID_VALUE(0x100)
		 STREAM_MATCH_SID_MASK(0xF81)>,
		<9 STREAM_CFG(PTLB_ID(0xA), STLB_ID(0x19), FETCH_SIZE(SIZE1), PTLB_EN, STLB_EN)
		 STREAM_MATCH_CFG(DIR_READ)
		 STREAM_MATCH_SID_VALUE(0x180)
		 STREAM_MATCH_SID_MASK(0xF81)>,
		<10 STREAM_CFG(PTLB_ID(0xB), STLB_ID(0x1A), FETCH_SIZE(SIZE1), PTLB_EN, STLB_EN)
		 STREAM_MATCH_CFG(DIR_READ)
		 STREAM_MATCH_SID_VALUE(0x200)
		 STREAM_MATCH_SID_MASK(0xF81)>,
		<11 STREAM_CFG(PTLB_ID(0x0), STLB_ID(0x9), FETCH_SIZE(SIZE16), PTLB_DIS, STLB_EN)
		 STREAM_MATCH_CFG(DIR_READ)
		 STREAM_MATCH_SID_VALUE(0x280)
		 STREAM_MATCH_SID_MASK(0xF81)>,
		<12 STREAM_CFG(PTLB_ID(0xC), STLB_ID(0x1B), FETCH_SIZE(SIZE1), PTLB_EN, STLB_EN)
		 STREAM_MATCH_CFG(DIR_READ)
		 STREAM_MATCH_SID_VALUE(0x300)
		 STREAM_MATCH_SID_MASK(0xF81)>,
		<13 STREAM_CFG(PTLB_ID(0xD), STLB_ID(0x1C), FETCH_SIZE(SIZE1), PTLB_EN, STLB_EN)
		 STREAM_MATCH_CFG(DIR_READ)
		 STREAM_MATCH_SID_VALUE(0x301)
		 STREAM_MATCH_SID_MASK(0xF81)>,
		<14 STREAM_CFG(PTLB_ID(0xE), STLB_ID(0x1D), FETCH_SIZE(SIZE1), PTLB_DIS, STLB_EN)
		 STREAM_MATCH_CFG(DIR_WRITE)
		 STREAM_MATCH_SID_VALUE(0x300)
		 STREAM_MATCH_SID_MASK(0xF81)>,
		<15 STREAM_CFG(PTLB_ID(0xF), STLB_ID(0x1E), FETCH_SIZE(SIZE1), PTLB_DIS, STLB_EN)
		 STREAM_MATCH_CFG(DIR_WRITE)
		 STREAM_MATCH_SID_VALUE(0x301)
		 STREAM_MATCH_SID_MASK(0xF81)>,
		<16 STREAM_CFG(PTLB_ID(0x10), STLB_ID(0x1F), FETCH_SIZE(SIZE1), PTLB_DIS, STLB_EN)
		 STREAM_MATCH_CFG(DIR_WRITE)
		 STREAM_MATCH_SID_VALUE(0x302)
		 STREAM_MATCH_SID_MASK(0xF81)>,
		<17 STREAM_CFG(PTLB_ID(0x11), STLB_ID(0x20), FETCH_SIZE(SIZE1), PTLB_EN, STLB_EN)
		 STREAM_MATCH_CFG(DIR_READ)
		 STREAM_MATCH_SID_VALUE(0x380)
		 STREAM_MATCH_SID_MASK(0xF81)>,
		<18 STREAM_CFG(PTLB_ID(0x12), STLB_ID(0x21), FETCH_SIZE(SIZE1), PTLB_EN, STLB_EN)
		 STREAM_MATCH_CFG(DIR_READ)
		 STREAM_MATCH_SID_VALUE(0x381)
		 STREAM_MATCH_SID_MASK(0xF81)>,
		<19 STREAM_CFG(PTLB_ID(0x13), STLB_ID(0x22), FETCH_SIZE(SIZE1), PTLB_EN, STLB_EN)
		 STREAM_MATCH_CFG(DIR_READ)
		 STREAM_MATCH_SID_VALUE(0x400)
		 STREAM_MATCH_SID_MASK(0xF81)>,
		<20 STREAM_CFG(PTLB_ID(0x14), STLB_ID(0x23), FETCH_SIZE(SIZE1), PTLB_EN, STLB_EN)
		 STREAM_MATCH_CFG(DIR_READ)
		 STREAM_MATCH_SID_VALUE(0x401)
		 STREAM_MATCH_SID_MASK(0xF81)>,
		<21 STREAM_CFG(PTLB_ID(0x15), STLB_ID(0x24), FETCH_SIZE(SIZE1), PTLB_EN, STLB_EN)
		 STREAM_MATCH_CFG(DIR_READ)
		 STREAM_MATCH_SID_VALUE(0x480)
		 STREAM_MATCH_SID_MASK(0xF81)>,
		<22 STREAM_CFG(PTLB_ID(0x16), STLB_ID(0x25), FETCH_SIZE(SIZE1), PTLB_EN, STLB_EN)
		 STREAM_MATCH_CFG(DIR_READ)
		 STREAM_MATCH_SID_VALUE(0x500)
		 STREAM_MATCH_SID_MASK(0xF81)>,
		<23 STREAM_CFG(PTLB_ID(0x17), STLB_ID(0x26), FETCH_SIZE(SIZE1), PTLB_DIS, STLB_EN)
		 STREAM_MATCH_CFG(DIR_WRITE)
		 STREAM_MATCH_SID_VALUE(0x500)
		 STREAM_MATCH_SID_MASK(0xF81)>,
		<24 STREAM_CFG(PTLB_ID(0x18), STLB_ID(0x27), FETCH_SIZE(SIZE1), PTLB_DIS, STLB_EN)
		 STREAM_MATCH_CFG(DIR_WRITE)
		 STREAM_MATCH_SID_VALUE(0x501)
		 STREAM_MATCH_SID_MASK(0xF81)>,
		<25 STREAM_CFG(PTLB_ID(0x19), STLB_ID(0x28), FETCH_SIZE(SIZE1), PTLB_DIS, STLB_EN)
		 STREAM_MATCH_CFG(DIR_WRITE)
		 STREAM_MATCH_SID_VALUE(0x502)
		 STREAM_MATCH_SID_MASK(0xF81)>,
		<26 STREAM_CFG(PTLB_ID(0x1A), STLB_ID(0x29), FETCH_SIZE(SIZE1), PTLB_EN, STLB_EN)
		 STREAM_MATCH_CFG(DIR_READ)
		 STREAM_MATCH_SID_VALUE(0x580)
		 STREAM_MATCH_SID_MASK(0xF81)>,
		<27 STREAM_CFG(PTLB_ID(0x1B), STLB_ID(0x2A), FETCH_SIZE(SIZE1), PTLB_EN, STLB_EN)
		 STREAM_MATCH_CFG(DIR_READ)
		 STREAM_MATCH_SID_VALUE(0x600)
		 STREAM_MATCH_SID_MASK(0xF81)>,
		<28 STREAM_CFG(PTLB_ID(0x1C), STLB_ID(0x2B), FETCH_SIZE(SIZE1), PTLB_EN, STLB_EN)
		 STREAM_MATCH_CFG(DIR_READ)
		 STREAM_MATCH_SID_VALUE(0x680)
		 STREAM_MATCH_SID_MASK(0xF81)>,
		<29 STREAM_CFG(PTLB_ID(0x1D), STLB_ID(0x2C), FETCH_SIZE(SIZE1), PTLB_EN, STLB_EN)
		 STREAM_MATCH_CFG(DIR_READ)
		 STREAM_MATCH_SID_VALUE(0x700)
		 STREAM_MATCH_SID_MASK(0xF81)>,
		<30 STREAM_CFG(PTLB_ID(0x1E), STLB_ID(0x2D), FETCH_SIZE(SIZE1), PTLB_EN, STLB_EN)
		 STREAM_MATCH_CFG(DIR_WRITE)
		 STREAM_MATCH_SID_VALUE(0x700)
		 STREAM_MATCH_SID_MASK(0xF81)>,
		<31 STREAM_CFG(PTLB_ID(0x1F), STLB_ID(0x2E), FETCH_SIZE(SIZE1), PTLB_EN, STLB_EN)
		 STREAM_MATCH_CFG(DIR_WRITE)
		 STREAM_MATCH_SID_VALUE(0x701)
		 STREAM_MATCH_SID_MASK(0xF81)>,
		<32 STREAM_CFG(PTLB_ID(0x20), STLB_ID(0x2F), FETCH_SIZE(SIZE1), PTLB_EN, STLB_EN)
		 STREAM_MATCH_CFG(DIR_WRITE)
		 STREAM_MATCH_SID_VALUE(0x702)
		 STREAM_MATCH_SID_MASK(0xF81)>,
		<33 STREAM_CFG(PTLB_ID(0x21), STLB_ID(0x30), FETCH_SIZE(SIZE1), PTLB_EN, STLB_EN)
		 STREAM_MATCH_CFG(DIR_READ)
		 STREAM_MATCH_SID_VALUE(0x780)
		 STREAM_MATCH_SID_MASK(0xF81)>,
		<34 STREAM_CFG(PTLB_ID(0x22), STLB_ID(0x31), FETCH_SIZE(SIZE1), PTLB_EN, STLB_EN)
		 STREAM_MATCH_CFG(DIR_READ)
		 STREAM_MATCH_SID_VALUE(0x800)
		 STREAM_MATCH_SID_MASK(0xF81)>,
		<35 STREAM_CFG(PTLB_ID(0x23), STLB_ID(0x32), FETCH_SIZE(SIZE1), PTLB_EN, STLB_EN)
		 STREAM_MATCH_CFG(DIR_READ)
		 STREAM_MATCH_SID_VALUE(0x880)
		 STREAM_MATCH_SID_MASK(0xF81)>,
		<36 STREAM_CFG(PTLB_ID(0x24), STLB_ID(0x37), FETCH_SIZE(SIZE1), PTLB_DIS, STLB_DIS)
		 STREAM_MATCH_CFG(DIR_READ)
		 STREAM_MATCH_SID_VALUE(0x900)
		 STREAM_MATCH_SID_MASK(0xF81)>,
		<37 STREAM_CFG(PTLB_ID(0x25), STLB_ID(0x39), FETCH_SIZE(SIZE1), PTLB_DIS, STLB_DIS)
		 STREAM_MATCH_CFG(DIR_WRITE)
		 STREAM_MATCH_SID_VALUE(0x900)
		 STREAM_MATCH_SID_MASK(0xF81)>;
		pmmu1,default_stream =
		<STREAM_CFG(PTLB_ID(0x0), STLB_ID(0x0), FETCH_SIZE(SIZE32), PTLB_DIS, STLB_EN)>;
		pmmu1,stream_property =
		<1 STREAM_CFG(PTLB_ID(0x4), STLB_ID(0xE), FETCH_SIZE(SIZE2), PTLB_EN, STLB_EN)
		 STREAM_MATCH_CFG(DIR_READ)
		 STREAM_MATCH_SID_VALUE(0x1)
		 STREAM_MATCH_SID_MASK(0xF81)>,
		<2 STREAM_CFG(PTLB_ID(0x5), STLB_ID(0x33), FETCH_SIZE(SIZE1), PTLB_DIS, STLB_EN)
		 STREAM_MATCH_CFG(DIR_WRITE)
		 STREAM_MATCH_SID_VALUE(0x0)
		 STREAM_MATCH_SID_MASK(0xF81)>,
		<3 STREAM_CFG(PTLB_ID(0x6), STLB_ID(0x34), FETCH_SIZE(SIZE1), PTLB_DIS, STLB_EN)
		 STREAM_MATCH_CFG(DIR_WRITE)
		 STREAM_MATCH_SID_VALUE(0x1)
		 STREAM_MATCH_SID_MASK(0xF81)>,
		<4 STREAM_CFG(PTLB_ID(0x1), STLB_ID(0x1), FETCH_SIZE(SIZE32), PTLB_DIS, STLB_EN)
		 STREAM_MATCH_CFG(DIR_READ)
		 STREAM_MATCH_SID_VALUE(0x80)
		 STREAM_MATCH_SID_MASK(0xF81)>,
		<5 STREAM_CFG(PTLB_ID(0x7), STLB_ID(0x35), FETCH_SIZE(SIZE1), PTLB_DIS, STLB_EN)
		 STREAM_MATCH_CFG(DIR_WRITE)
		 STREAM_MATCH_SID_VALUE(0x80)
		 STREAM_MATCH_SID_MASK(0xF81)>,
		<6 STREAM_CFG(PTLB_ID(0x8), STLB_ID(0x36), FETCH_SIZE(SIZE1), PTLB_DIS, STLB_EN)
		 STREAM_MATCH_CFG(DIR_WRITE)
		 STREAM_MATCH_SID_VALUE(0x81)
		 STREAM_MATCH_SID_MASK(0xF81)>,
		<7 STREAM_CFG(PTLB_ID(0x2), STLB_ID(0x6), FETCH_SIZE(SIZE16), PTLB_DIS, STLB_EN)
		 STREAM_MATCH_CFG(DIR_READ)
		 STREAM_MATCH_SID_VALUE(0x100)
		 STREAM_MATCH_SID_MASK(0xF81)>,
		<8 STREAM_CFG(PTLB_ID(0x3), STLB_ID(0xA), FETCH_SIZE(SIZE8), PTLB_DIS, STLB_EN)
		 STREAM_MATCH_CFG(DIR_READ)
		 STREAM_MATCH_SID_VALUE(0x180)
		 STREAM_MATCH_SID_MASK(0xF81)>,
		<9 STREAM_CFG(PTLB_ID(0x9), STLB_ID(0x38), FETCH_SIZE(SIZE1), PTLB_DIS, STLB_EN)
		 STREAM_MATCH_CFG(DIR_READ)
		 STREAM_MATCH_SID_VALUE(0x200)
		 STREAM_MATCH_SID_MASK(0xF81)>;
		pmmu2,default_stream =
		<STREAM_CFG(PTLB_ID(0x0), STLB_ID(0x2), FETCH_SIZE(SIZE32), PTLB_DIS, STLB_EN)>;
		pmmu2,stream_property =
		<1 STREAM_CFG(PTLB_ID(0x4), STLB_ID(0xF), FETCH_SIZE(SIZE2), PTLB_EN, STLB_EN)
		 STREAM_MATCH_CFG(DIR_READ)
		 STREAM_MATCH_SID_VALUE(0x1)
		 STREAM_MATCH_SID_MASK(0xF81)>,
		<2 STREAM_CFG(PTLB_ID(0x5), STLB_ID(0x3A), FETCH_SIZE(SIZE1), PTLB_DIS, STLB_EN)
		 STREAM_MATCH_CFG(DIR_WRITE)
		 STREAM_MATCH_SID_VALUE(0x0)
		 STREAM_MATCH_SID_MASK(0xF81)>,
		<3 STREAM_CFG(PTLB_ID(0x1), STLB_ID(0x3), FETCH_SIZE(SIZE32), PTLB_DIS, STLB_EN)
		 STREAM_MATCH_CFG(DIR_READ)
		 STREAM_MATCH_SID_VALUE(0x80)
		 STREAM_MATCH_SID_MASK(0xF81)>,
		<4 STREAM_CFG(PTLB_ID(0x2), STLB_ID(0x7), FETCH_SIZE(SIZE16), PTLB_DIS, STLB_EN)
		 STREAM_MATCH_CFG(DIR_READ)
		 STREAM_MATCH_SID_VALUE(0x100)
		 STREAM_MATCH_SID_MASK(0xF81)>,
		<5 STREAM_CFG(PTLB_ID(0x3), STLB_ID(0xB), FETCH_SIZE(SIZE8), PTLB_DIS, STLB_EN)
		 STREAM_MATCH_CFG(DIR_READ)
		 STREAM_MATCH_SID_VALUE(0x180)
		 STREAM_MATCH_SID_MASK(0xF81)>;
		pmmu3,default_stream =
		<STREAM_CFG(PTLB_ID(0x0), STLB_ID(0x4), FETCH_SIZE(SIZE32), PTLB_DIS, STLB_EN)>;
		pmmu3,stream_property =
		<1 STREAM_CFG(PTLB_ID(0x4), STLB_ID(0x10), FETCH_SIZE(SIZE2), PTLB_DIS, STLB_EN)
		 STREAM_MATCH_CFG(DIR_READ)
		 STREAM_MATCH_SID_VALUE(0x1)
		 STREAM_MATCH_SID_MASK(0xF81)>,
		<2 STREAM_CFG(PTLB_ID(0x1), STLB_ID(0x5), FETCH_SIZE(SIZE32), PTLB_DIS, STLB_EN)
		 STREAM_MATCH_CFG(DIR_READ)
		 STREAM_MATCH_SID_VALUE(0x80)
		 STREAM_MATCH_SID_MASK(0xF81)>,
		<3 STREAM_CFG(PTLB_ID(0x2), STLB_ID(0x8), FETCH_SIZE(SIZE16), PTLB_DIS, STLB_EN)
		 STREAM_MATCH_CFG(DIR_READ)
		 STREAM_MATCH_SID_VALUE(0x100)
		 STREAM_MATCH_SID_MASK(0xF81)>,
		<4 STREAM_CFG(PTLB_ID(0x3), STLB_ID(0xC), FETCH_SIZE(SIZE8), PTLB_DIS, STLB_EN)
		 STREAM_MATCH_CFG(DIR_READ)
		 STREAM_MATCH_SID_VALUE(0x180)
		 STREAM_MATCH_SID_MASK(0xF81)>;
	};

	sysmmu_rgbp_s0_stream: sysmmu_rgbp_s0_stream {
		pmmu0,default_stream =
		<STREAM_CFG(PTLB_ID(0x9), STLB_ID(0x13), FETCH_SIZE(SIZE1), PTLB_DIS, STLB_DIS)>;
		pmmu0,stream_property =
		<1 STREAM_CFG(PTLB_ID(0xB), STLB_ID(0x17), FETCH_SIZE(SIZE1), PTLB_DIS, STLB_DIS)
		 STREAM_MATCH_CFG(DIR_WRITE)
		 STREAM_MATCH_SID_VALUE(0x0)
		 STREAM_MATCH_SID_MASK(0xF81)>,
		<2 STREAM_CFG(PTLB_ID(0xA), STLB_ID(0x14), FETCH_SIZE(SIZE1), PTLB_DIS, STLB_DIS)
		 STREAM_MATCH_CFG(DIR_READ)
		 STREAM_MATCH_SID_VALUE(0x80)
		 STREAM_MATCH_SID_MASK(0xF81)>,
		<3 STREAM_CFG(PTLB_ID(0x0), STLB_ID(0x0), FETCH_SIZE(SIZE1), PTLB_EN, STLB_EN)
		 STREAM_MATCH_CFG(DIR_READ)
		 STREAM_MATCH_SID_VALUE(0x100)
		 STREAM_MATCH_SID_MASK(0xF81)>,
		<4 STREAM_CFG(PTLB_ID(0x1), STLB_ID(0x1), FETCH_SIZE(SIZE1), PTLB_EN, STLB_EN)
		 STREAM_MATCH_CFG(DIR_WRITE)
		 STREAM_MATCH_SID_VALUE(0x100)
		 STREAM_MATCH_SID_MASK(0xF9F)>,
		<5 STREAM_CFG(PTLB_ID(0x2), STLB_ID(0x2), FETCH_SIZE(SIZE1), PTLB_EN, STLB_EN)
		 STREAM_MATCH_CFG(DIR_WRITE)
		 STREAM_MATCH_SID_VALUE(0x108)
		 STREAM_MATCH_SID_MASK(0xF9F)>,
		<6 STREAM_CFG(PTLB_ID(0x3), STLB_ID(0x3), FETCH_SIZE(SIZE1), PTLB_EN, STLB_EN)
		 STREAM_MATCH_CFG(DIR_WRITE)
		 STREAM_MATCH_SID_VALUE(0x110)
		 STREAM_MATCH_SID_MASK(0xF9F)>,
		<7 STREAM_CFG(PTLB_ID(0x4), STLB_ID(0x4), FETCH_SIZE(SIZE1), PTLB_EN, STLB_EN)
		 STREAM_MATCH_CFG(DIR_WRITE)
		 STREAM_MATCH_SID_VALUE(0x118)
		 STREAM_MATCH_SID_MASK(0xF9F)>,
		<8 STREAM_CFG(PTLB_ID(0x5), STLB_ID(0x5), FETCH_SIZE(SIZE1), PTLB_EN, STLB_EN)
		 STREAM_MATCH_CFG(DIR_WRITE)
		 STREAM_MATCH_SID_VALUE(0x180)
		 STREAM_MATCH_SID_MASK(0xF9F)>,
		<9 STREAM_CFG(PTLB_ID(0x6), STLB_ID(0x6), FETCH_SIZE(SIZE1), PTLB_EN, STLB_EN)
		 STREAM_MATCH_CFG(DIR_WRITE)
		 STREAM_MATCH_SID_VALUE(0x188)
		 STREAM_MATCH_SID_MASK(0xF9F)>,
		<10 STREAM_CFG(PTLB_ID(0x7), STLB_ID(0x7), FETCH_SIZE(SIZE1), PTLB_EN, STLB_EN)
		 STREAM_MATCH_CFG(DIR_WRITE)
		 STREAM_MATCH_SID_VALUE(0x190)
		 STREAM_MATCH_SID_MASK(0xF9F)>,
		<11 STREAM_CFG(PTLB_ID(0x8), STLB_ID(0x8), FETCH_SIZE(SIZE1), PTLB_EN, STLB_EN)
		 STREAM_MATCH_CFG(DIR_WRITE)
		 STREAM_MATCH_SID_VALUE(0x198)
		 STREAM_MATCH_SID_MASK(0xF9F)>;
		pmmu1,default_stream =
		<STREAM_CFG(PTLB_ID(0xA), STLB_ID(0x15), FETCH_SIZE(SIZE1), PTLB_DIS, STLB_DIS)>;
		pmmu1,stream_property =
		<1 STREAM_CFG(PTLB_ID(0xB), STLB_ID(0x16), FETCH_SIZE(SIZE1), PTLB_DIS, STLB_DIS)
		 STREAM_MATCH_CFG(DIR_READ)
		 STREAM_MATCH_SID_VALUE(0x80)
		 STREAM_MATCH_SID_MASK(0xF81)>,
		<2 STREAM_CFG(PTLB_ID(0x0), STLB_ID(0x9), FETCH_SIZE(SIZE1), PTLB_EN, STLB_EN)
		 STREAM_MATCH_CFG(DIR_READ)
		 STREAM_MATCH_SID_VALUE(0x100)
		 STREAM_MATCH_SID_MASK(0xF81)>,
		<3 STREAM_CFG(PTLB_ID(0x1), STLB_ID(0xA), FETCH_SIZE(SIZE1), PTLB_EN, STLB_EN)
		 STREAM_MATCH_CFG(DIR_WRITE)
		 STREAM_MATCH_SID_VALUE(0x100)
		 STREAM_MATCH_SID_MASK(0xF9F)>,
		<4 STREAM_CFG(PTLB_ID(0x2), STLB_ID(0xB), FETCH_SIZE(SIZE1), PTLB_EN, STLB_EN)
		 STREAM_MATCH_CFG(DIR_WRITE)
		 STREAM_MATCH_SID_VALUE(0x108)
		 STREAM_MATCH_SID_MASK(0xF9F)>,
		<5 STREAM_CFG(PTLB_ID(0x3), STLB_ID(0xC), FETCH_SIZE(SIZE1), PTLB_EN, STLB_EN)
		 STREAM_MATCH_CFG(DIR_WRITE)
		 STREAM_MATCH_SID_VALUE(0x110)
		 STREAM_MATCH_SID_MASK(0xF9F)>,
		<6 STREAM_CFG(PTLB_ID(0x4), STLB_ID(0xD), FETCH_SIZE(SIZE1), PTLB_EN, STLB_EN)
		 STREAM_MATCH_CFG(DIR_WRITE)
		 STREAM_MATCH_SID_VALUE(0x118)
		 STREAM_MATCH_SID_MASK(0xF9F)>,
		<7 STREAM_CFG(PTLB_ID(0x5), STLB_ID(0xE), FETCH_SIZE(SIZE1), PTLB_EN, STLB_EN)
		 STREAM_MATCH_CFG(DIR_READ)
		 STREAM_MATCH_SID_VALUE(0x180)
		 STREAM_MATCH_SID_MASK(0xF81)>,
		<8 STREAM_CFG(PTLB_ID(0x6), STLB_ID(0xF), FETCH_SIZE(SIZE1), PTLB_EN, STLB_EN)
		 STREAM_MATCH_CFG(DIR_WRITE)
		 STREAM_MATCH_SID_VALUE(0x180)
		 STREAM_MATCH_SID_MASK(0xF9F)>,
		<9 STREAM_CFG(PTLB_ID(0x7), STLB_ID(0x10), FETCH_SIZE(SIZE1), PTLB_EN, STLB_EN)
		 STREAM_MATCH_CFG(DIR_WRITE)
		 STREAM_MATCH_SID_VALUE(0x188)
		 STREAM_MATCH_SID_MASK(0xF9F)>,
		<10 STREAM_CFG(PTLB_ID(0x8), STLB_ID(0x11), FETCH_SIZE(SIZE1), PTLB_EN, STLB_EN)
		 STREAM_MATCH_CFG(DIR_WRITE)
		 STREAM_MATCH_SID_VALUE(0x190)
		 STREAM_MATCH_SID_MASK(0xF9F)>,
		<11 STREAM_CFG(PTLB_ID(0x9), STLB_ID(0x12), FETCH_SIZE(SIZE1), PTLB_EN, STLB_EN)
		 STREAM_MATCH_CFG(DIR_WRITE)
		 STREAM_MATCH_SID_VALUE(0x198)
		 STREAM_MATCH_SID_MASK(0xF9F)>;
	};

	sysmmu_sdma_s0_stream: sysmmu_sdma_s0_stream {
		pmmu0,default_stream =
		<STREAM_CFG(PTLB_ID(0x0), STLB_ID(0x0), FETCH_SIZE(SIZE8), PTLB_EN, STLB_EN)>;
		pmmu0,stream_property =
		<1 STREAM_CFG(PTLB_ID(0x1), STLB_ID(0x1), FETCH_SIZE(SIZE1), PTLB_DIS, STLB_DIS)
		 STREAM_MATCH_CFG(DIR_RW)
		 STREAM_MATCH_SID_VALUE(0x40)
		 STREAM_MATCH_SID_MASK(0xFC0)>;
		pmmu1,default_stream =
		<STREAM_CFG(PTLB_ID(0x0), STLB_ID(0x0), FETCH_SIZE(SIZE8), PTLB_EN, STLB_EN)>;
		pmmu1,stream_property =
		<1 STREAM_CFG(PTLB_ID(0x1), STLB_ID(0x1), FETCH_SIZE(SIZE1), PTLB_DIS, STLB_DIS)
		 STREAM_MATCH_CFG(DIR_RW)
		 STREAM_MATCH_SID_VALUE(0x40)
		 STREAM_MATCH_SID_MASK(0xFC0)>;
		pmmu2,default_stream =
		<STREAM_CFG(PTLB_ID(0x0), STLB_ID(0x0), FETCH_SIZE(SIZE8), PTLB_EN, STLB_EN)>;
		pmmu2,stream_property =
		<1 STREAM_CFG(PTLB_ID(0x1), STLB_ID(0x1), FETCH_SIZE(SIZE1), PTLB_DIS, STLB_DIS)
		 STREAM_MATCH_CFG(DIR_RW)
		 STREAM_MATCH_SID_VALUE(0x40)
		 STREAM_MATCH_SID_MASK(0xFC0)>;
		pmmu3,default_stream =
		<STREAM_CFG(PTLB_ID(0x0), STLB_ID(0x0), FETCH_SIZE(SIZE8), PTLB_EN, STLB_EN)>;
		pmmu3,stream_property =
		<1 STREAM_CFG(PTLB_ID(0x1), STLB_ID(0x1), FETCH_SIZE(SIZE1), PTLB_DIS, STLB_DIS)
		 STREAM_MATCH_CFG(DIR_RW)
		 STREAM_MATCH_SID_VALUE(0x40)
		 STREAM_MATCH_SID_MASK(0xFC0)>;
	};

	sysmmu_sdma_s1_stream: sysmmu_sdma_s1_stream {
		pmmu0,default_stream =
		<STREAM_CFG(PTLB_ID(0x0), STLB_ID(0x0), FETCH_SIZE(SIZE1), PTLB_DIS, STLB_DIS)>;
		pmmu0,stream_property =
		<1 STREAM_CFG(PTLB_ID(0xB), STLB_ID(0xB), FETCH_SIZE(SIZE1), PTLB_DIS, STLB_DIS)
		 STREAM_MATCH_CFG(DIR_READ)
		 STREAM_MATCH_SID_VALUE(0x1)
		 STREAM_MATCH_SID_MASK(0xF9F)>,
		<2 STREAM_CFG(PTLB_ID(0x5), STLB_ID(0x1), FETCH_SIZE(SIZE1), PTLB_DIS, STLB_EN)
		 STREAM_MATCH_CFG(DIR_READ)
		 STREAM_MATCH_SID_VALUE(0x11)
		 STREAM_MATCH_SID_MASK(0xF9F)>,
		<3 STREAM_CFG(PTLB_ID(0x6), STLB_ID(0x2), FETCH_SIZE(SIZE1), PTLB_DIS, STLB_EN)
		 STREAM_MATCH_CFG(DIR_READ)
		 STREAM_MATCH_SID_VALUE(0x2)
		 STREAM_MATCH_SID_MASK(0xF9F)>,
		<4 STREAM_CFG(PTLB_ID(0x1), STLB_ID(0x7), FETCH_SIZE(SIZE1), PTLB_EN, STLB_EN)
		 STREAM_MATCH_CFG(DIR_READ)
		 STREAM_MATCH_SID_VALUE(0x12)
		 STREAM_MATCH_SID_MASK(0xF9F)>,
		<5 STREAM_CFG(PTLB_ID(0x7), STLB_ID(0x3), FETCH_SIZE(SIZE1), PTLB_DIS, STLB_EN)
		 STREAM_MATCH_CFG(DIR_READ)
		 STREAM_MATCH_SID_VALUE(0x3)
		 STREAM_MATCH_SID_MASK(0xF9F)>,
		<6 STREAM_CFG(PTLB_ID(0x2), STLB_ID(0x8), FETCH_SIZE(SIZE1), PTLB_EN, STLB_EN)
		 STREAM_MATCH_CFG(DIR_READ)
		 STREAM_MATCH_SID_VALUE(0x13)
		 STREAM_MATCH_SID_MASK(0xF9F)>,
		<7 STREAM_CFG(PTLB_ID(0xC), STLB_ID(0xC), FETCH_SIZE(SIZE1), PTLB_DIS, STLB_DIS)
		 STREAM_MATCH_CFG(DIR_WRITE)
		 STREAM_MATCH_SID_VALUE(0x4)
		 STREAM_MATCH_SID_MASK(0xF8F)>,
		<8 STREAM_CFG(PTLB_ID(0x8), STLB_ID(0x4), FETCH_SIZE(SIZE1), PTLB_DIS, STLB_EN)
		 STREAM_MATCH_CFG(DIR_READ)
		 STREAM_MATCH_SID_VALUE(0x6)
		 STREAM_MATCH_SID_MASK(0xF9F)>,
		<9 STREAM_CFG(PTLB_ID(0x3), STLB_ID(0x9), FETCH_SIZE(SIZE1), PTLB_EN, STLB_EN)
		 STREAM_MATCH_CFG(DIR_READ)
		 STREAM_MATCH_SID_VALUE(0x16)
		 STREAM_MATCH_SID_MASK(0xF9F)>,
		<10 STREAM_CFG(PTLB_ID(0x9), STLB_ID(0x5), FETCH_SIZE(SIZE1), PTLB_DIS, STLB_EN)
		 STREAM_MATCH_CFG(DIR_READ)
		 STREAM_MATCH_SID_VALUE(0x7)
		 STREAM_MATCH_SID_MASK(0xF9F)>,
		<11 STREAM_CFG(PTLB_ID(0x4), STLB_ID(0xA), FETCH_SIZE(SIZE1), PTLB_EN, STLB_EN)
		 STREAM_MATCH_CFG(DIR_READ)
		 STREAM_MATCH_SID_VALUE(0x17)
		 STREAM_MATCH_SID_MASK(0xF9F)>,
		<12 STREAM_CFG(PTLB_ID(0xA), STLB_ID(0x6), FETCH_SIZE(SIZE1), PTLB_DIS, STLB_EN)
		 STREAM_MATCH_CFG(DIR_READ)
		 STREAM_MATCH_SID_VALUE(0x8)
		 STREAM_MATCH_SID_MASK(0xF9F)>;
	};

	sysmmu_ufd_s0_stream: sysmmu_ufd_s0_stream {
		pmmu0,default_stream =
		<STREAM_CFG(PTLB_ID(0x0), STLB_ID(0x0), FETCH_SIZE(SIZE1), PTLB_DIS, STLB_EN)>;
	};

	sysmmu_yuvp_s0_stream: sysmmu_yuvp_s0_stream {
		pmmu0,default_stream =
		<STREAM_CFG(PTLB_ID(0x4), STLB_ID(0xA), FETCH_SIZE(SIZE1), PTLB_DIS, STLB_DIS)>;
		pmmu0,stream_property =
		<1 STREAM_CFG(PTLB_ID(0x5), STLB_ID(0xD), FETCH_SIZE(SIZE1), PTLB_DIS, STLB_DIS)
		 STREAM_MATCH_CFG(DIR_WRITE)
		 STREAM_MATCH_SID_VALUE(0x0)
		 STREAM_MATCH_SID_MASK(0xF81)>,
		<2 STREAM_CFG(PTLB_ID(0x0), STLB_ID(0x0), FETCH_SIZE(SIZE1), PTLB_EN, STLB_EN)
		 STREAM_MATCH_CFG(DIR_READ)
		 STREAM_MATCH_SID_VALUE(0x80)
		 STREAM_MATCH_SID_MASK(0xF81)>,
		<3 STREAM_CFG(PTLB_ID(0x1), STLB_ID(0x1), FETCH_SIZE(SIZE1), PTLB_EN, STLB_EN)
		 STREAM_MATCH_CFG(DIR_READ)
		 STREAM_MATCH_SID_VALUE(0x100)
		 STREAM_MATCH_SID_MASK(0xF81)>,
		<4 STREAM_CFG(PTLB_ID(0x2), STLB_ID(0x2), FETCH_SIZE(SIZE1), PTLB_EN, STLB_EN)
		 STREAM_MATCH_CFG(DIR_READ)
		 STREAM_MATCH_SID_VALUE(0x180)
		 STREAM_MATCH_SID_MASK(0xF81)>,
		<5 STREAM_CFG(PTLB_ID(0x6), STLB_ID(0x3), FETCH_SIZE(SIZE1), PTLB_DIS, STLB_DIS)
		 STREAM_MATCH_CFG(DIR_WRITE)
		 STREAM_MATCH_SID_VALUE(0x180)
		 STREAM_MATCH_SID_MASK(0xF81)>,
		<6 STREAM_CFG(PTLB_ID(0x3), STLB_ID(0x4), FETCH_SIZE(SIZE1), PTLB_EN, STLB_EN)
		 STREAM_MATCH_CFG(DIR_READ)
		 STREAM_MATCH_SID_VALUE(0x200)
		 STREAM_MATCH_SID_MASK(0xF81)>;
		pmmu1,default_stream =
		<STREAM_CFG(PTLB_ID(0x0), STLB_ID(0x5), FETCH_SIZE(SIZE1), PTLB_EN, STLB_EN)>;
		pmmu1,stream_property =
		<1 STREAM_CFG(PTLB_ID(0x1), STLB_ID(0x6), FETCH_SIZE(SIZE1), PTLB_EN, STLB_EN)
		 STREAM_MATCH_CFG(DIR_READ)
		 STREAM_MATCH_SID_VALUE(0x80)
		 STREAM_MATCH_SID_MASK(0xF81)>,
		<2 STREAM_CFG(PTLB_ID(0x5), STLB_ID(0xB), FETCH_SIZE(SIZE1), PTLB_EN, STLB_DIS)
		 STREAM_MATCH_CFG(DIR_READ)
		 STREAM_MATCH_SID_VALUE(0x100)
		 STREAM_MATCH_SID_MASK(0xF81)>,
		<3 STREAM_CFG(PTLB_ID(0x2), STLB_ID(0x7), FETCH_SIZE(SIZE1), PTLB_DIS, STLB_EN)
		 STREAM_MATCH_CFG(DIR_WRITE)
		 STREAM_MATCH_SID_VALUE(0x100)
		 STREAM_MATCH_SID_MASK(0xF81)>,
		<4 STREAM_CFG(PTLB_ID(0x3), STLB_ID(0x8), FETCH_SIZE(SIZE1), PTLB_EN, STLB_EN)
		 STREAM_MATCH_CFG(DIR_READ)
		 STREAM_MATCH_SID_VALUE(0x180)
		 STREAM_MATCH_SID_MASK(0xF81)>,
		<5 STREAM_CFG(PTLB_ID(0x6), STLB_ID(0xC), FETCH_SIZE(SIZE1), PTLB_DIS, STLB_DIS)
		 STREAM_MATCH_CFG(DIR_READ)
		 STREAM_MATCH_SID_VALUE(0x200)
		 STREAM_MATCH_SID_MASK(0xF81)>,
		<6 STREAM_CFG(PTLB_ID(0x7), STLB_ID(0xE), FETCH_SIZE(SIZE1), PTLB_DIS, STLB_DIS)
		 STREAM_MATCH_CFG(DIR_WRITE)
		 STREAM_MATCH_SID_VALUE(0x200)
		 STREAM_MATCH_SID_MASK(0xF81)>,
		<7 STREAM_CFG(PTLB_ID(0x4), STLB_ID(0x9), FETCH_SIZE(SIZE1), PTLB_DIS, STLB_DIS)
		 STREAM_MATCH_CFG(DIR_WRITE)
		 STREAM_MATCH_SID_VALUE(0x280)
		 STREAM_MATCH_SID_MASK(0xF81)>;
	};

};
